// *************************************************************************** *
// *                                                                           *
// * Description:         CANDB File                                           *
// * Generated at:        2024-09-17 14:53                                     *
// * System:              SDB23200                                             *
// * Variant:             E371_PCMU_ADCU5                                      *
// * Network:             ChassisCAN1                                          *
// *                                                                           *
// *************************************************************************** *

VERSION "ChassisCAN1"

NS_ :

BS_ :

BU_ :  ASDM BBM ETC PSCM1 PSCM2 RBCM SAS VDDM

BO_ 147 AsdmChas1Fr01 : 8 ASDM
 SG_ AsyADL3FuncCtrlSts_UB : 32|1@0+ (1,0) [0|1] "" PSCM1
 SG_ AsyADL3FuncCtrlStsADMod : 27|2@0+ (1,0) [0|3] "" PSCM1
 SG_ AsyADL3FuncCtrlStsChks : 23|8@0+ (1.0,0.0) [0.0|255.0] "Unitless" PSCM1
 SG_ AsyADL3FuncCtrlStsCntr : 31|4@0+ (1.0,0.0) [0.0|15.0] "Unitless" PSCM1
 SG_ AsyADL3FuncCtrlStsCtrlSts : 33|1@0+ (1,0) [0|1] "" PSCM1
 SG_ AsyADL3FuncCtrlStsDegraded : 39|4@0+ (1.0,0.0) [0.0|15.0] "Unitless" PSCM1
 SG_ AsyADL3FuncCtrlStsQf : 25|2@0+ (1,0) [0|3] "" PSCM1
 SG_ AsyADL3FuncCtrlStsSts : 35|2@0+ (1,0) [0|3] "" PSCM1
 SG_ AsyADModeReq_UB : 48|1@0+ (1,0) [0|1] "" PSCM1
 SG_ AsyADModeReqADActiveReq : 51|2@0+ (1,0) [0|3] "" PSCM1
 SG_ AsyADModeReqADDeactiveReq : 49|1@0+ (1,0) [0|1] "" PSCM1
 SG_ AsyADModeReqChks : 47|8@0+ (1.0,0.0) [0.0|255.0] "Unitless" PSCM1
 SG_ AsyADModeReqCntr : 55|4@0+ (1.0,0.0) [0.0|15.0] "Unitless" PSCM1
 SG_ PASFuncActive : 15|1@0+ (1,0) [0|1] "" VDDM
 SG_ PASFuncActive_UB : 14|1@0+ (1,0) [0|1] "" VDDM
 SG_ RctaBrkReqQM : 13|1@0+ (1,0) [0|1] "" VDDM
 SG_ RctaBrkReqQM_UB : 12|1@0+ (1,0) [0|1] "" VDDM
 SG_ RcwmBrkReqQM : 11|1@0+ (1,0) [0|1] "" VDDM
 SG_ RcwmBrkReqQM_UB : 10|1@0+ (1,0) [0|1] "" VDDM

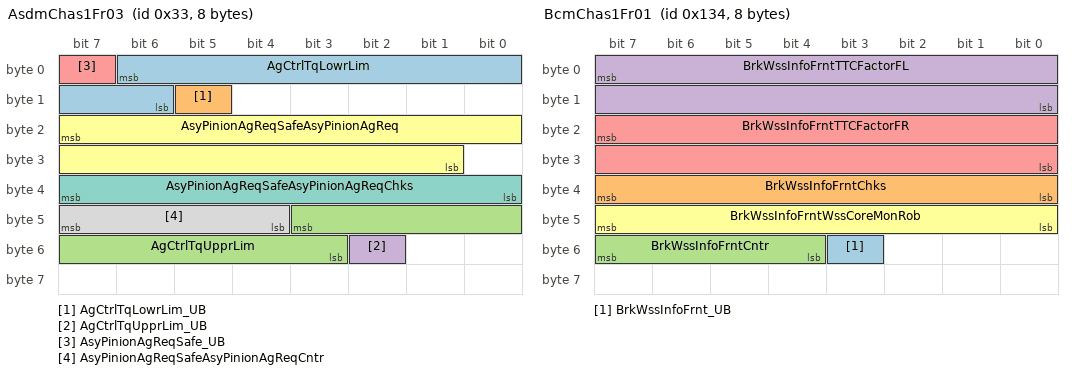
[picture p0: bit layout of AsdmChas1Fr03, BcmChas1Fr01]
BO_ 51 AsdmChas1Fr03 : 8 ASDM
 SG_ AgCtrlTqLowrLim : 6|9@0+ (0.125,-30.0) [-30.0|30.0] "Nm" PSCM1
 SG_ AgCtrlTqLowrLim_UB : 13|1@0+ (1,0) [0|1] "" PSCM1
 SG_ AgCtrlTqUpprLim : 43|9@0+ (0.125,-30.0) [-30.0|30.0] "Nm" PSCM1
 SG_ AgCtrlTqUpprLim_UB : 50|1@0+ (1,0) [0|1] "" PSCM1
 SG_ AsyPinionAgReqSafe_UB : 7|1@0+ (1,0) [0|1] "" PSCM1
 SG_ AsyPinionAgReqSafeAsyPinionAgReq : 23|15@0+ (0.0009765625,-14.5) [-14.5|17.4990234375] "rad" PSCM1
 SG_ AsyPinionAgReqSafeAsyPinionAgReqChks : 39|8@0+ (1.0,0.0) [0.0|255.0] "Unitless" PSCM1
 SG_ AsyPinionAgReqSafeAsyPinionAgReqCntr : 47|4@0+ (1.0,0.0) [0.0|15.0] "Unitless" PSCM1

BO_ 1321 AsdmChas1NMFr : 8 ASDM
 SG_ PNC16_ASDM : 16|1@0+ (1,0) [0|0] "" Vector__XXX
 SG_ PNC17_ASDM : 17|1@0+ (1,0) [0|0] "" Vector__XXX
 SG_ PNC18_ASDM : 18|1@0+ (1,0) [0|0] "" Vector__XXX
 SG_ PNC19_ASDM : 19|1@0+ (1,0) [0|0] "" Vector__XXX
 SG_ PNC20_ASDM : 20|1@0+ (1,0) [0|0] "" Vector__XXX
 SG_ PNC21_ASDM : 21|1@0+ (1,0) [0|0] "" Vector__XXX
 SG_ PNC22_ASDM : 22|1@0+ (1,0) [0|0] "" Vector__XXX
 SG_ PNC23_ASDM : 23|1@0+ (1,0) [0|0] "" Vector__XXX
 SG_ PNC24_ASDM : 24|1@0+ (1,0) [0|0] "" Vector__XXX
 SG_ PNC25_ASDM : 25|1@0+ (1,0) [0|0] "" Vector__XXX
 SG_ PNC26_ASDM : 26|1@0+ (1,0) [0|0] "" Vector__XXX
 SG_ PNC27_ASDM : 27|1@0+ (1,0) [0|0] "" Vector__XXX
 SG_ PNC28_ASDM : 28|1@0+ (1,0) [0|0] "" Vector__XXX
 SG_ PNC29_ASDM : 29|1@0+ (1,0) [0|0] "" Vector__XXX
 SG_ PNC30_ASDM : 30|1@0+ (1,0) [0|0] "" Vector__XXX
 SG_ PNC31_ASDM : 31|1@0+ (1,0) [0|0] "" Vector__XXX
 SG_ PNC32_ASDM : 32|1@0+ (1,0) [0|0] "" Vector__XXX
 SG_ PNC33_ASDM : 33|1@0+ (1,0) [0|0] "" Vector__XXX
 SG_ PNC34_ASDM : 34|1@0+ (1,0) [0|0] "" Vector__XXX
 SG_ PNC35_ASDM : 35|1@0+ (1,0) [0|0] "" Vector__XXX
 SG_ PNC36_ASDM : 36|1@0+ (1,0) [0|0] "" Vector__XXX
 SG_ PNC37_ASDM : 37|1@0+ (1,0) [0|0] "" Vector__XXX
 SG_ PNC38_ASDM : 38|1@0+ (1,0) [0|0] "" Vector__XXX
 SG_ PNC39_ASDM : 39|1@0+ (1,0) [0|0] "" Vector__XXX
 SG_ PNC40_ASDM : 40|1@0+ (1,0) [0|0] "" Vector__XXX
 SG_ PNC41_ASDM : 41|1@0+ (1,0) [0|0] "" Vector__XXX
 SG_ PNC42_ASDM : 42|1@0+ (1,0) [0|0] "" Vector__XXX
 SG_ NM_PNI_ASDM : 14|1@0+ (1,0) [0|0] "" Vector__XXX
 SG_ NM_AW_ASDM : 12|1@0+ (1,0) [0|0] "" Vector__XXX
 SG_ NM_CS_ASDM : 11|1@0+ (1,0) [0|0] "" Vector__XXX
 SG_ NM_RMR_ASDM : 8|1@0+ (1,0) [0|0] "" Vector__XXX
 SG_ NM_NodeID_ASDM : 7|8@0+ (1,0) [0|0] "" Vector__XXX

BO_ 308 BcmChas1Fr01 : 8 BBM
 SG_ BrkWssInfoFrnt_UB : 51|1@0+ (1,0) [0|1] "" RBCM
 SG_ BrkWssInfoFrntChks : 39|8@0+ (1.0,0.0) [0.0|255.0] "Unitless" RBCM
 SG_ BrkWssInfoFrntCntr : 55|4@0+ (1.0,0.0) [0.0|15.0] "Unitless" RBCM
 SG_ BrkWssInfoFrntTTCFactorFL : 7|16@0+ (0.00000916,0.7) [0.7|1.3003006] "Unitless" RBCM
 SG_ BrkWssInfoFrntTTCFactorFR : 23|16@0+ (0.00000916,0.7) [0.7|1.3003006] "Unitless" RBCM
 SG_ BrkWssInfoFrntWssCoreMonRob : 47|8@0+ (1.0,0.0) [0.0|255.0] "Unitless" RBCM

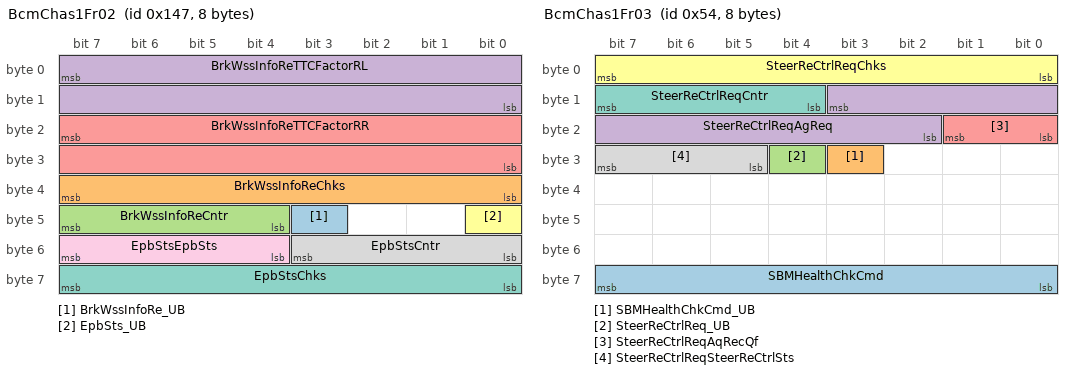
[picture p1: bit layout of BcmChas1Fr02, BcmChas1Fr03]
BO_ 327 BcmChas1Fr02 : 8 BBM
 SG_ BrkWssInfoRe_UB : 43|1@0+ (1,0) [0|1] "" RBCM
 SG_ BrkWssInfoReChks : 39|8@0+ (1.0,0.0) [0.0|255.0] "Unitless" RBCM
 SG_ BrkWssInfoReCntr : 47|4@0+ (1.0,0.0) [0.0|15.0] "Unitless" RBCM
 SG_ BrkWssInfoReTTCFactorRL : 7|16@0+ (0.00000916,0.7) [0.7|1.3003006] "Unitless" RBCM
 SG_ BrkWssInfoReTTCFactorRR : 23|16@0+ (0.00000916,0.7) [0.7|1.3003006] "Unitless" RBCM
 SG_ EpbSts_UB : 40|1@0+ (1,0) [0|1] "" RBCM
 SG_ EpbStsChks : 63|8@0+ (1.0,0.0) [0.0|255.0] "Unitless" RBCM
 SG_ EpbStsCntr : 51|4@0+ (1.0,0.0) [0.0|15.0] "Unitless" RBCM
 SG_ EpbStsEpbSts : 55|4@0+ (1,0) [0|15] "" RBCM

BO_ 84 BcmChas1Fr03 : 8 BBM
 SG_ SBMHealthChkCmd : 63|8@0+ (1.0,0.0) [0.0|255.0] "Unitless" RBCM
 SG_ SBMHealthChkCmd_UB : 27|1@0+ (1,0) [0|1] "" RBCM
 SG_ SteerReCtrlReq_UB : 28|1@0+ (1,0) [0|1] "" Vector__XXX
 SG_ SteerReCtrlReqAgReq : 11|10@0- (0.01,0.0) [-5.12|5.11] "Deg" Vector__XXX
 SG_ SteerReCtrlReqAqRecQf : 17|2@0+ (1,0) [0|3] "" Vector__XXX
 SG_ SteerReCtrlReqChks : 7|8@0+ (1.0,0.0) [0.0|255.0] "Unitless" Vector__XXX
 SG_ SteerReCtrlReqCntr : 15|4@0+ (1.0,0.0) [0.0|15.0] "Unitless" Vector__XXX
 SG_ SteerReCtrlReqSteerReCtrlSts : 31|3@0+ (1,0) [0|7] "" Vector__XXX

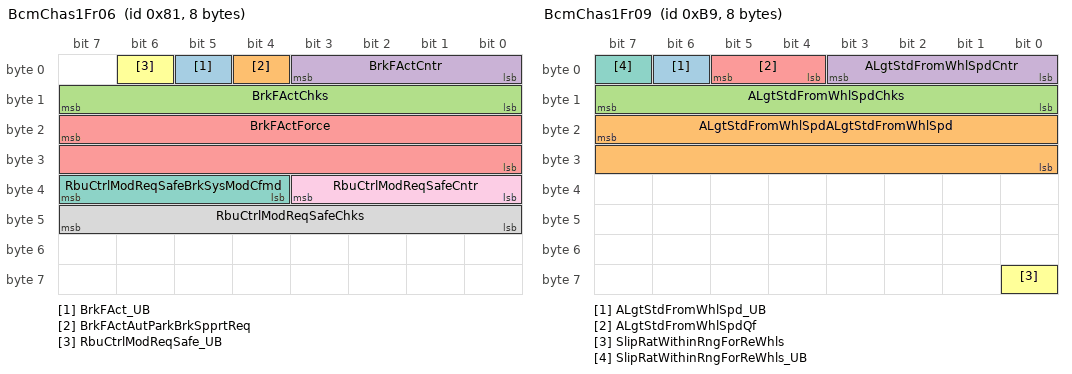
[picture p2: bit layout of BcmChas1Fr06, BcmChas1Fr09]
BO_ 129 BcmChas1Fr06 : 8 BBM
 SG_ BrkFAct_UB : 5|1@0+ (1,0) [0|1] "" RBCM
 SG_ BrkFActAutParkBrkSpprtReq : 4|1@0+ (1,0) [0|1] "" RBCM
 SG_ BrkFActChks : 15|8@0+ (1.0,0.0) [0.0|255.0] "Unitless" RBCM
 SG_ BrkFActCntr : 3|4@0+ (1.0,0.0) [0.0|15.0] "Unitless" RBCM
 SG_ BrkFActForce : 23|16@0+ (1.0,0.0) [0.0|50000.0] "N" RBCM
 SG_ RbuCtrlModReqSafe_UB : 6|1@0+ (1,0) [0|1] "" RBCM
 SG_ RbuCtrlModReqSafeBrkSysModCfmd : 39|4@0+ (1,0) [0|15] "" RBCM
 SG_ RbuCtrlModReqSafeChks : 47|8@0+ (1.0,0.0) [0.0|255.0] "Unitless" RBCM
 SG_ RbuCtrlModReqSafeCntr : 35|4@0+ (1.0,0.0) [0.0|15.0] "Unitless" RBCM

BO_ 265 BcmChas1Fr07 : 8 BBM
 SG_ EpbAvlPrim_UB : 57|1@0+ (1,0) [0|1] "" Vector__XXX
 SG_ EpbAvlPrimApplyFunctionalitiesAvailable : 27|1@0+ (1,0) [0|1] "" Vector__XXX
 SG_ EpbAvlPrimChks : 23|8@0+ (1.0,0.0) [0.0|255.0] "Unitless" Vector__XXX
 SG_ EpbAvlPrimCntr : 31|4@0+ (1.0,0.0) [0.0|15.0] "Unitless" Vector__XXX
 SG_ EpbAvlPrimDriveAwayIntention : 26|1@0+ (1,0) [0|1] "" Vector__XXX
 SG_ EpbAvlPrimHostAvailabilityFull : 25|1@0+ (1,0) [0|1] "" Vector__XXX
 SG_ EpbAvlPrimHostAvailabilityRelOnly : 24|1@0+ (1,0) [0|1] "" Vector__XXX
 SG_ EpbAvlPrimPrimarySystemAvailable : 39|1@0+ (1,0) [0|1] "" Vector__XXX
 SG_ EpbAvlPrimReserved1 : 38|1@0+ (1,0) [0|1] "" Vector__XXX
 SG_ EpbAvlPrimReserved2 : 37|1@0+ (1,0) [0|1] "" Vector__XXX
 SG_ EpbAvlPrimReserved3 : 36|1@0+ (1,0) [0|1] "" Vector__XXX
 SG_ EpbAvlPrimReserved4 : 35|1@0+ (1,0) [0|1] "" Vector__XXX
 SG_ EpbAvlPrimRollerTestBench : 34|1@0+ (1,0) [0|1] "" Vector__XXX
 SG_ PrimBrkSysSt_UB : 56|1@0+ (1,0) [0|1] "" RBCM
 SG_ PrimBrkSysStBrkSysSt : 7|4@0+ (1,0) [0|15] "" RBCM
 SG_ PrimBrkSysStChks : 15|8@0+ (1.0,0.0) [0.0|255.0] "Unitless" RBCM
 SG_ PrimBrkSysStCntr : 3|4@0+ (1.0,0.0) [0.0|15.0] "Unitless" RBCM

BO_ 185 BcmChas1Fr09 : 8 BBM
 SG_ ALgtStdFromWhlSpd_UB : 6|1@0+ (1,0) [0|1] "" Vector__XXX
 SG_ ALgtStdFromWhlSpdALgtStdFromWhlSpd : 23|16@0- (0.0009765625,0.0) [-18.0|18.0] "m/s^2" Vector__XXX
 SG_ ALgtStdFromWhlSpdChks : 15|8@0+ (1.0,0.0) [0.0|255.0] "Unitless" Vector__XXX
 SG_ ALgtStdFromWhlSpdCntr : 3|4@0+ (1.0,0.0) [0.0|15.0] "Unitless" Vector__XXX
 SG_ ALgtStdFromWhlSpdQf : 5|2@0+ (1,0) [0|3] "" Vector__XXX
 SG_ SlipRatWithinRngForReWhls : 56|1@0+ (1,0) [0|1] "" Vector__XXX
 SG_ SlipRatWithinRngForReWhls_UB : 7|1@0+ (1,0) [0|1] "" Vector__XXX

BO_ 1334 BcmChas1NMFr : 8 BBM
 SG_ PNC16_BBM : 16|1@0+ (1,0) [0|0] "" Vector__XXX
 SG_ PNC17_BBM : 17|1@0+ (1,0) [0|0] "" Vector__XXX
 SG_ PNC18_BBM : 18|1@0+ (1,0) [0|0] "" Vector__XXX
 SG_ PNC19_BBM : 19|1@0+ (1,0) [0|0] "" Vector__XXX
 SG_ PNC20_BBM : 20|1@0+ (1,0) [0|0] "" Vector__XXX
 SG_ PNC21_BBM : 21|1@0+ (1,0) [0|0] "" Vector__XXX
 SG_ PNC22_BBM : 22|1@0+ (1,0) [0|0] "" Vector__XXX
 SG_ PNC23_BBM : 23|1@0+ (1,0) [0|0] "" Vector__XXX
 SG_ PNC24_BBM : 24|1@0+ (1,0) [0|0] "" Vector__XXX
 SG_ PNC25_BBM : 25|1@0+ (1,0) [0|0] "" Vector__XXX
 SG_ PNC26_BBM : 26|1@0+ (1,0) [0|0] "" Vector__XXX
 SG_ PNC27_BBM : 27|1@0+ (1,0) [0|0] "" Vector__XXX
 SG_ PNC28_BBM : 28|1@0+ (1,0) [0|0] "" Vector__XXX
 SG_ PNC29_BBM : 29|1@0+ (1,0) [0|0] "" Vector__XXX
 SG_ PNC30_BBM : 30|1@0+ (1,0) [0|0] "" Vector__XXX
 SG_ PNC31_BBM : 31|1@0+ (1,0) [0|0] "" Vector__XXX
 SG_ PNC32_BBM : 32|1@0+ (1,0) [0|0] "" Vector__XXX
 SG_ PNC33_BBM : 33|1@0+ (1,0) [0|0] "" Vector__XXX
 SG_ PNC34_BBM : 34|1@0+ (1,0) [0|0] "" Vector__XXX
 SG_ PNC35_BBM : 35|1@0+ (1,0) [0|0] "" Vector__XXX
 SG_ PNC36_BBM : 36|1@0+ (1,0) [0|0] "" Vector__XXX
 SG_ PNC37_BBM : 37|1@0+ (1,0) [0|0] "" Vector__XXX
 SG_ PNC38_BBM : 38|1@0+ (1,0) [0|0] "" Vector__XXX
 SG_ PNC39_BBM : 39|1@0+ (1,0) [0|0] "" Vector__XXX
 SG_ PNC40_BBM : 40|1@0+ (1,0) [0|0] "" Vector__XXX
 SG_ PNC41_BBM : 41|1@0+ (1,0) [0|0] "" Vector__XXX
 SG_ PNC42_BBM : 42|1@0+ (1,0) [0|0] "" Vector__XXX
 SG_ NM_PNI_BBM : 14|1@0+ (1,0) [0|0] "" Vector__XXX
 SG_ NM_AW_BBM : 12|1@0+ (1,0) [0|0] "" Vector__XXX
 SG_ NM_CS_BBM : 11|1@0+ (1,0) [0|0] "" Vector__XXX
 SG_ NM_RMR_BBM : 8|1@0+ (1,0) [0|0] "" Vector__XXX
 SG_ NM_NodeID_BBM : 7|8@0+ (1,0) [0|0] "" Vector__XXX

BO_ 134 EcmChas1BsgFr40 : 8 VDDM
 SG_ DrvgCyc : 39|1@0+ (1,0) [0|1] "" Vector__XXX
 SG_ DrvgCyc_UB : 38|1@0+ (1,0) [0|1] "" Vector__XXX

BO_ 544 EcmChas1BsgFr41 : 8 VDDM
 SG_ AccrPedlRat_UB : 7|1@0+ (1,0) [0|1] "" RBCM
 SG_ AccrPedlRatAccrPedlRat : 6|15@0+ (0.00390625,0.0) [0.0|100.0] "%" RBCM
 SG_ AccrPedlRatChks : 23|8@0+ (1.0,0.0) [0.0|255.0] "Unitless" RBCM
 SG_ AccrPedlRatCntr : 31|4@0+ (1.0,0.0) [0.0|15.0] "Unitless" RBCM

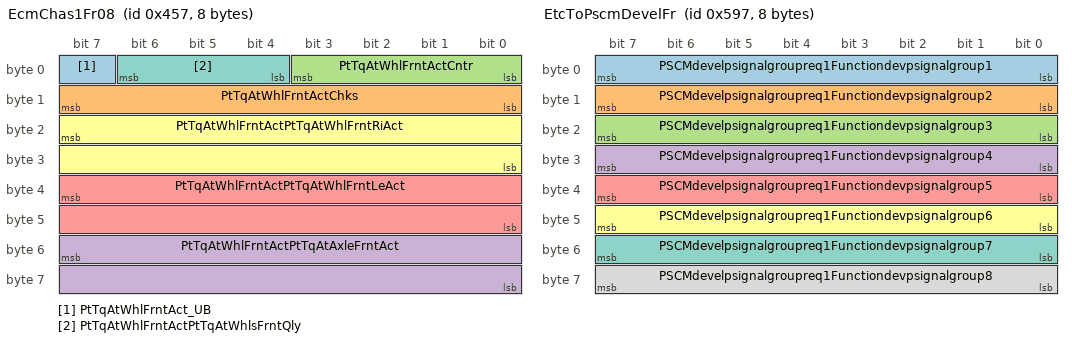
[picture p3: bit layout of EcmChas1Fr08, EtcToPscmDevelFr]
BO_ 1111 EcmChas1Fr08 : 8 VDDM
 SG_ PtTqAtWhlFrntAct_UB : 7|1@0+ (1,0) [0|1] "" PSCM1
 SG_ PtTqAtWhlFrntActChks : 15|8@0+ (1.0,0.0) [0.0|255.0] "Unitless" PSCM1
 SG_ PtTqAtWhlFrntActCntr : 3|4@0+ (1.0,0.0) [0.0|15.0] "Unitless" PSCM1
 SG_ PtTqAtWhlFrntActPtTqAtAxleFrntAct : 55|16@0- (1.0,0.0) [-20000.0|20000.0] "NewtonMeter" PSCM1
 SG_ PtTqAtWhlFrntActPtTqAtWhlFrntLeAct : 39|16@0- (1.0,0.0) [-20000.0|20000.0] "NewtonMeter" PSCM1
 SG_ PtTqAtWhlFrntActPtTqAtWhlFrntRiAct : 23|16@0- (1.0,0.0) [-20000.0|20000.0] "NewtonMeter" PSCM1
 SG_ PtTqAtWhlFrntActPtTqAtWhlsFrntQly : 6|3@0+ (1,0) [0|7] "" PSCM1

BO_ 131 EcmChas1Fr31 : 8 VDDM
 SG_ EngSt1WdSts_UB : 23|1@0+ (1,0) [0|1] "" Vector__XXX
 SG_ EngSt1WdStsChks : 7|8@0+ (1.0,0.0) [0.0|255.0] "Unitless" Vector__XXX
 SG_ EngSt1WdStsCntr : 15|4@0+ (1.0,0.0) [0.0|15.0] "Unitless" Vector__XXX
 SG_ EngSt1WdStsEngSt1WdSts : 11|4@0+ (1,0) [0|15] "" Vector__XXX

BO_ 752 EcmChas1Fr37 : 8 VDDM
 SG_ DrvrGearLvrInfoIndcn : 15|3@0+ (1,0) [0|7] "" Vector__XXX
 SG_ DrvrGearLvrInfoIndcn_UB : 12|1@0+ (1,0) [0|1] "" Vector__XXX
 SG_ EngSt1WdSts1 : 11|4@0+ (1,0) [0|15] "" SAS
 SG_ EngSt1WdSts1_UB : 41|1@0+ (1,0) [0|1] "" SAS

BO_ 121 EcmChas1Fr53 : 8 VDDM
 SG_ EngPAmbAir : 63|8@0+ (5.0,0.0) [0.0|1275.0] "hPa" Vector__XXX
 SG_ EngPAmbAir_UB : 48|1@0+ (1,0) [0|1] "" Vector__XXX

BO_ 1429 EtcToMvemXcpFr01 : 8 ETC

BO_ 1424 EtcToMvemXcpFr02 : 8 ETC

BO_ 1425 EtcToMvemXcpFr03 : 8 ETC

BO_ 1441 EtcToPscm1cChas1XcpFr01 : 8 ETC

BO_ 1409 EtcToPscmChas1XcpFr01 : 8 ETC

BO_ 1416 EtcToPscmChas1XcpFr02 : 8 ETC

BO_ 1418 EtcToPscmChas1XcpFr03 : 8 ETC

BO_ 1420 EtcToPscmChas1XcpFr04 : 8 ETC

BO_ 1431 EtcToPscmDevelFr : 8 ETC
 SG_ PSCMdevelpsignalgroupreq1Functiondevpsignalgroup1 : 7|8@0+ (1.0,0.0) [0.0|255.0] "Unitless" PSCM1
 SG_ PSCMdevelpsignalgroupreq1Functiondevpsignalgroup2 : 15|8@0+ (1.0,0.0) [0.0|255.0] "Unitless" PSCM1
 SG_ PSCMdevelpsignalgroupreq1Functiondevpsignalgroup3 : 23|8@0+ (1.0,0.0) [0.0|255.0] "Unitless" PSCM1
 SG_ PSCMdevelpsignalgroupreq1Functiondevpsignalgroup4 : 31|8@0+ (1.0,0.0) [0.0|255.0] "Unitless" PSCM1
 SG_ PSCMdevelpsignalgroupreq1Functiondevpsignalgroup5 : 39|8@0+ (1.0,0.0) [0.0|255.0] "Unitless" PSCM1
 SG_ PSCMdevelpsignalgroupreq1Functiondevpsignalgroup6 : 47|8@0+ (1.0,0.0) [0.0|255.0] "Unitless" PSCM1
 SG_ PSCMdevelpsignalgroupreq1Functiondevpsignalgroup7 : 55|8@0+ (1.0,0.0) [0.0|255.0] "Unitless" PSCM1
 SG_ PSCMdevelpsignalgroupreq1Functiondevpsignalgroup8 : 63|8@0+ (1.0,0.0) [0.0|255.0] "Unitless" PSCM1

BO_ 1442 EtcToRasmChas1XcpFr01 : 8 ETC

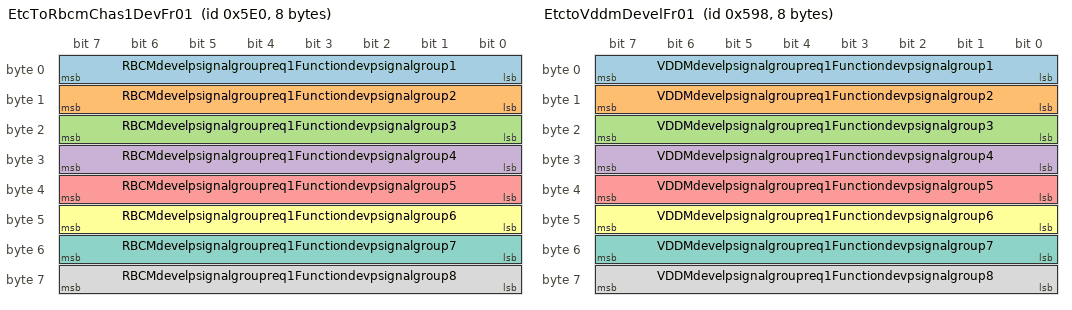
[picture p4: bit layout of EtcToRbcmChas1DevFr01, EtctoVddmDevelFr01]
BO_ 1504 EtcToRbcmChas1DevFr01 : 8 ETC
 SG_ RBCMdevelpsignalgroupreq1Functiondevpsignalgroup1 : 7|8@0+ (1.0,0.0) [0.0|255.0] "Unitless" Vector__XXX
 SG_ RBCMdevelpsignalgroupreq1Functiondevpsignalgroup2 : 15|8@0+ (1.0,0.0) [0.0|255.0] "Unitless" Vector__XXX
 SG_ RBCMdevelpsignalgroupreq1Functiondevpsignalgroup3 : 23|8@0+ (1.0,0.0) [0.0|255.0] "Unitless" Vector__XXX
 SG_ RBCMdevelpsignalgroupreq1Functiondevpsignalgroup4 : 31|8@0+ (1.0,0.0) [0.0|255.0] "Unitless" Vector__XXX
 SG_ RBCMdevelpsignalgroupreq1Functiondevpsignalgroup5 : 39|8@0+ (1.0,0.0) [0.0|255.0] "Unitless" Vector__XXX
 SG_ RBCMdevelpsignalgroupreq1Functiondevpsignalgroup6 : 47|8@0+ (1.0,0.0) [0.0|255.0] "Unitless" Vector__XXX
 SG_ RBCMdevelpsignalgroupreq1Functiondevpsignalgroup7 : 55|8@0+ (1.0,0.0) [0.0|255.0] "Unitless" Vector__XXX
 SG_ RBCMdevelpsignalgroupreq1Functiondevpsignalgroup8 : 63|8@0+ (1.0,0.0) [0.0|255.0] "Unitless" Vector__XXX

BO_ 1414 EtcToTcmXcpFr01 : 8 ETC

BO_ 1411 EtcToTcmXcpFr02 : 8 ETC

BO_ 1421 EtctoVddmBcmXCPFr01 : 8 ETC

BO_ 1432 EtctoVddmDevelFr01 : 8 ETC
 SG_ VDDMdevelpsignalgroupreq1Functiondevpsignalgroup1 : 7|8@0+ (1.0,0.0) [0.0|255.0] "Unitless" BBM
 SG_ VDDMdevelpsignalgroupreq1Functiondevpsignalgroup2 : 15|8@0+ (1.0,0.0) [0.0|255.0] "Unitless" BBM
 SG_ VDDMdevelpsignalgroupreq1Functiondevpsignalgroup3 : 23|8@0+ (1.0,0.0) [0.0|255.0] "Unitless" BBM
 SG_ VDDMdevelpsignalgroupreq1Functiondevpsignalgroup4 : 31|8@0+ (1.0,0.0) [0.0|255.0] "Unitless" BBM
 SG_ VDDMdevelpsignalgroupreq1Functiondevpsignalgroup5 : 39|8@0+ (1.0,0.0) [0.0|255.0] "Unitless" BBM
 SG_ VDDMdevelpsignalgroupreq1Functiondevpsignalgroup6 : 47|8@0+ (1.0,0.0) [0.0|255.0] "Unitless" BBM
 SG_ VDDMdevelpsignalgroupreq1Functiondevpsignalgroup7 : 55|8@0+ (1.0,0.0) [0.0|255.0] "Unitless" BBM
 SG_ VDDMdevelpsignalgroupreq1Functiondevpsignalgroup8 : 63|8@0+ (1.0,0.0) [0.0|255.0] "Unitless" BBM

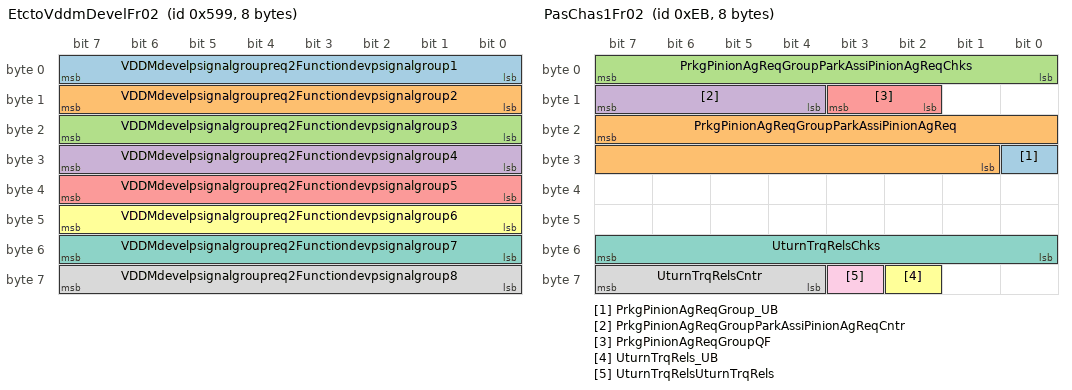
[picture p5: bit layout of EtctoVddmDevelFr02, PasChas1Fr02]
BO_ 1433 EtctoVddmDevelFr02 : 8 ETC
 SG_ VDDMdevelpsignalgroupreq2Functiondevpsignalgroup1 : 7|8@0+ (1.0,0.0) [0.0|255.0] "Unitless" BBM
 SG_ VDDMdevelpsignalgroupreq2Functiondevpsignalgroup2 : 15|8@0+ (1.0,0.0) [0.0|255.0] "Unitless" BBM
 SG_ VDDMdevelpsignalgroupreq2Functiondevpsignalgroup3 : 23|8@0+ (1.0,0.0) [0.0|255.0] "Unitless" BBM
 SG_ VDDMdevelpsignalgroupreq2Functiondevpsignalgroup4 : 31|8@0+ (1.0,0.0) [0.0|255.0] "Unitless" BBM
 SG_ VDDMdevelpsignalgroupreq2Functiondevpsignalgroup5 : 39|8@0+ (1.0,0.0) [0.0|255.0] "Unitless" BBM
 SG_ VDDMdevelpsignalgroupreq2Functiondevpsignalgroup6 : 47|8@0+ (1.0,0.0) [0.0|255.0] "Unitless" BBM
 SG_ VDDMdevelpsignalgroupreq2Functiondevpsignalgroup7 : 55|8@0+ (1.0,0.0) [0.0|255.0] "Unitless" BBM
 SG_ VDDMdevelpsignalgroupreq2Functiondevpsignalgroup8 : 63|8@0+ (1.0,0.0) [0.0|255.0] "Unitless" BBM

BO_ 235 PasChas1Fr02 : 8 ASDM
 SG_ PrkgPinionAgReqGroup_UB : 24|1@0+ (1,0) [0|1] "" PSCM1
 SG_ PrkgPinionAgReqGroupParkAssiPinionAgReq : 23|15@0+ (0.000976563,-14.5) [-14.5|17.499039821] "rad" PSCM1
 SG_ PrkgPinionAgReqGroupParkAssiPinionAgReqChks : 7|8@0+ (1.0,0.0) [0.0|255.0] "Unitless" PSCM1
 SG_ PrkgPinionAgReqGroupParkAssiPinionAgReqCntr : 15|4@0+ (1.0,0.0) [0.0|15.0] "Unitless" PSCM1
 SG_ PrkgPinionAgReqGroupQF : 11|2@0+ (1,0) [0|3] "" PSCM1
 SG_ UturnTrqRels_UB : 58|1@0+ (1,0) [0|1] "" PSCM1
 SG_ UturnTrqRelsChks : 55|8@0+ (1.0,0.0) [0.0|255.0] "Unitless" PSCM1
 SG_ UturnTrqRelsCntr : 63|4@0+ (1.0,0.0) [0.0|15.0] "Unitless" PSCM1
 SG_ UturnTrqRelsUturnTrqRels : 59|1@0+ (1,0) [0|1] "" PSCM1

BO_ 149 PasChas1Fr04 : 8 ASDM
 SG_ PrkgGearReqGroup_UB : 10|1@0+ (1,0) [0|1] "" VDDM
 SG_ PrkgGearReqGroupChks : 7|8@0+ (1.0,0.0) [0.0|255.0] "Unitless" VDDM
 SG_ PrkgGearReqGroupCntr : 15|4@0+ (1.0,0.0) [0.0|15.0] "Unitless" VDDM
 SG_ PrkgGearReqGroupReqSts1 : 11|1@0+ (1,0) [0|1] "" VDDM

BO_ 1654 Pscm2cToVddmChas1DiagResFrame : 8 PSCM2
 SG_ Pscm2cToVddmChas1DiagResNpdu : 7|64@0+ (1,0) [0|0] "" VDDM

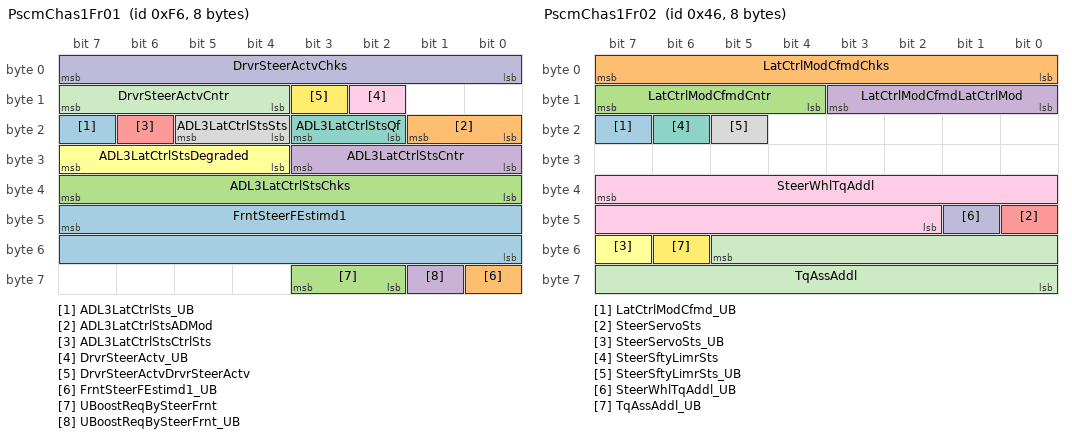
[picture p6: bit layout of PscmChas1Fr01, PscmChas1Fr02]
BO_ 246 PscmChas1Fr01 : 8 PSCM1
 SG_ ADL3LatCtrlSts_UB : 23|1@0+ (1,0) [0|1] "" ASDM
 SG_ ADL3LatCtrlStsADMod : 17|2@0+ (1,0) [0|3] "" ASDM
 SG_ ADL3LatCtrlStsChks : 39|8@0+ (1.0,0.0) [0.0|255.0] "Unitless" ASDM
 SG_ ADL3LatCtrlStsCntr : 27|4@0+ (1.0,0.0) [0.0|15.0] "Unitless" ASDM
 SG_ ADL3LatCtrlStsCtrlSts : 22|1@0+ (1,0) [0|1] "" ASDM
 SG_ ADL3LatCtrlStsDegraded : 31|4@0+ (1,0) [0|15] "" ASDM
 SG_ ADL3LatCtrlStsQf : 19|2@0+ (1,0) [0|3] "" ASDM
 SG_ ADL3LatCtrlStsSts : 21|2@0+ (1,0) [0|3] "" ASDM
 SG_ DrvrSteerActv_UB : 10|1@0+ (1,0) [0|1] "" ASDM
 SG_ DrvrSteerActvChks : 7|8@0+ (1.0,0.0) [0.0|255.0] "Unitless" ASDM
 SG_ DrvrSteerActvCntr : 15|4@0+ (1.0,0.0) [0.0|15.0] "Unitless" ASDM
 SG_ DrvrSteerActvDrvrSteerActv : 11|1@0+ (1,0) [0|1] "" ASDM
 SG_ FrntSteerFEstimd1 : 47|16@0- (1.0,0.0) [-32768.0|32767.0] "N" BBM
 SG_ FrntSteerFEstimd1_UB : 56|1@0+ (1,0) [0|1] "" BBM
 SG_ UBoostReqBySteerFrnt : 59|2@0+ (1,0) [0|3] "" VDDM
 SG_ UBoostReqBySteerFrnt_UB : 57|1@0+ (1,0) [0|1] "" VDDM

BO_ 70 PscmChas1Fr02 : 8 PSCM1
 SG_ LatCtrlModCfmd_UB : 23|1@0+ (1,0) [0|1] "" ASDM,BBM,VDDM
 SG_ LatCtrlModCfmdChks : 7|8@0+ (1.0,0.0) [0.0|255.0] "Unitless" ASDM,BBM,VDDM
 SG_ LatCtrlModCfmdCntr : 15|4@0+ (1.0,0.0) [0.0|15.0] "Unitless" ASDM,BBM,VDDM
 SG_ LatCtrlModCfmdLatCtrlMod : 11|4@0+ (1,0) [0|15] "" ASDM,BBM,VDDM
 SG_ SteerServoSts : 40|1@0+ (1,0) [0|1] "" ASDM,VDDM
 SG_ SteerServoSts_UB : 55|1@0+ (1,0) [0|1] "" ASDM,VDDM
 SG_ SteerSftyLimrSts : 22|1@0+ (1,0) [0|1] "" ASDM
 SG_ SteerSftyLimrSts_UB : 21|1@0+ (1,0) [0|1] "" ASDM
 SG_ SteerWhlTqAddl : 39|14@0- (0.00390625,0.0) [-30.0|30.0] "NewtonMeter" ASDM,BBM,VDDM
 SG_ SteerWhlTqAddl_UB : 41|1@0+ (1,0) [0|1] "" ASDM,BBM,VDDM
 SG_ TqAssAddl : 53|14@0- (0.00390625,0.0) [-30.0|30.0] "NewtonMeter" ASDM
 SG_ TqAssAddl_UB : 54|1@0+ (1,0) [0|1] "" ASDM

BO_ 444 PscmChas1Fr03 : 8 PSCM1
 SG_ DrvrSteerWhlHldGroup_UB : 1|1@0+ (1,0) [0|1] "" ASDM,VDDM
 SG_ DrvrSteerWhlHldGroupDrvrSteerWhlHld : 7|2@0+ (1,0) [0|3] "" ASDM,VDDM
 SG_ DrvrSteerWhlHldGroupDrvrSteerWhlHldQly : 5|4@0+ (1.0,0.0) [0.0|15.0] "Unitless" ASDM,VDDM
 SG_ SteerErrReq : 46|3@0+ (1,0) [0|7] "" VDDM
 SG_ SteerErrReq_UB : 47|1@0+ (1,0) [0|1] "" VDDM
 SG_ SteerExtFctSts_UB : 43|1@0+ (1,0) [0|1] "" ASDM
 SG_ SteerExtFctStsChks : 63|8@0+ (1.0,0.0) [0.0|255.0] "Unitless" ASDM
 SG_ SteerExtFctStsCntr : 51|4@0+ (1.0,0.0) [0.0|15.0] "Unitless" ASDM
 SG_ SteerExtFctStsDrvrSteerOvrd : 52|1@0+ (1,0) [0|1] "" ASDM
 SG_ SteerExtFctStsExtFctLowerLimActive : 53|1@0+ (1,0) [0|1] "" ASDM
 SG_ SteerExtFctStsExtFctRateLimActive : 54|1@0+ (1,0) [0|1] "" ASDM
 SG_ SteerExtFctStsExtFctUpperLimActive : 55|1@0+ (1,0) [0|1] "" ASDM
 SG_ SteerExtFctStsExtSafeLimActive : 40|1@0+ (1,0) [0|1] "" ASDM
 SG_ SteerExtFctStsLatAgReqNotInRange : 41|1@0+ (1,0) [0|1] "" ASDM
 SG_ SteerExtFctStsLatCtrlReqNotInRange : 42|1@0+ (1,0) [0|1] "" ASDM
 SG_ SteerStsToParkAssi : 15|3@0+ (1,0) [0|7] "" ASDM,BBM
 SG_ SteerStsToParkAssi_UB : 0|1@0+ (1,0) [0|1] "" ASDM,BBM

BO_ 955 PscmChas1Fr06 : 8 PSCM1
 SG_ PinionSteerAgMax1 : 54|15@0- (0.0009765625,0.0) [-14.5|14.5] "rad" VDDM
 SG_ PinionSteerAgMax1_UB : 55|1@0+ (1,0) [0|1] "" VDDM

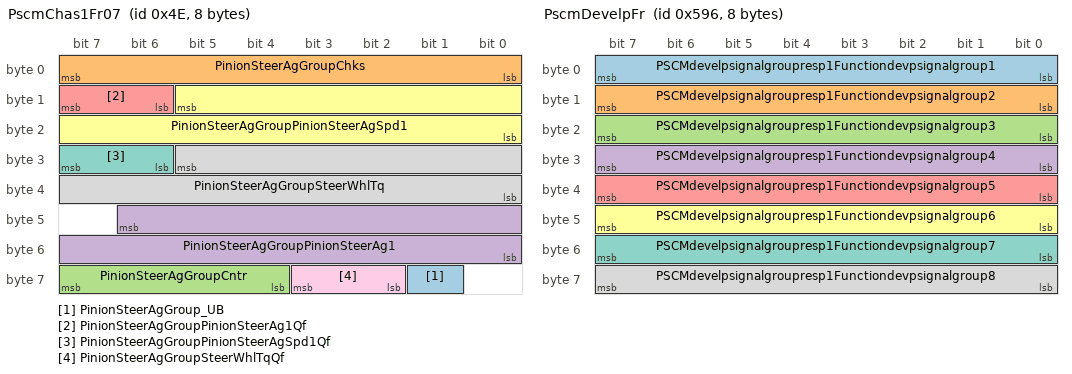
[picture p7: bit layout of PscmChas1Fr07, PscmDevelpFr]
BO_ 78 PscmChas1Fr07 : 8 PSCM1
 SG_ PinionSteerAgGroup_UB : 57|1@0+ (1,0) [0|1] "" ASDM,BBM,VDDM
 SG_ PinionSteerAgGroupChks : 7|8@0+ (1.0,0.0) [0.0|255.0] "Unitless" ASDM,BBM,VDDM
 SG_ PinionSteerAgGroupCntr : 63|4@0+ (1.0,0.0) [0.0|15.0] "Unitless" ASDM,BBM,VDDM
 SG_ PinionSteerAgGroupPinionSteerAg1 : 46|15@0- (0.0009765625,0.0) [-14.5|14.5] "rad" ASDM,BBM,VDDM
 SG_ PinionSteerAgGroupPinionSteerAg1Qf : 15|2@0+ (1,0) [0|3] "" ASDM,BBM,VDDM
 SG_ PinionSteerAgGroupPinionSteerAgSpd1 : 13|14@0- (0.0078125,0.0) [-50.0|50.0] "rad/s" ASDM,BBM,VDDM
 SG_ PinionSteerAgGroupPinionSteerAgSpd1Qf : 31|2@0+ (1,0) [0|3] "" ASDM,BBM,VDDM
 SG_ PinionSteerAgGroupSteerWhlTq : 29|14@0- (0.00390625,0.0) [-30.0|30.0] "NewtonMeter" ASDM,BBM,VDDM
 SG_ PinionSteerAgGroupSteerWhlTqQf : 59|2@0+ (1,0) [0|3] "" ASDM,BBM,VDDM

BO_ 1315 PscmChas1NMFr : 8 PSCM1
 SG_ PNC16_PSCM1 : 16|1@0+ (1,0) [0|0] "" Vector__XXX
 SG_ PNC17_PSCM1 : 17|1@0+ (1,0) [0|0] "" Vector__XXX
 SG_ PNC18_PSCM1 : 18|1@0+ (1,0) [0|0] "" Vector__XXX
 SG_ PNC19_PSCM1 : 19|1@0+ (1,0) [0|0] "" Vector__XXX
 SG_ PNC20_PSCM1 : 20|1@0+ (1,0) [0|0] "" Vector__XXX
 SG_ PNC21_PSCM1 : 21|1@0+ (1,0) [0|0] "" Vector__XXX
 SG_ PNC22_PSCM1 : 22|1@0+ (1,0) [0|0] "" Vector__XXX
 SG_ PNC23_PSCM1 : 23|1@0+ (1,0) [0|0] "" Vector__XXX
 SG_ PNC24_PSCM1 : 24|1@0+ (1,0) [0|0] "" Vector__XXX
 SG_ PNC25_PSCM1 : 25|1@0+ (1,0) [0|0] "" Vector__XXX
 SG_ PNC26_PSCM1 : 26|1@0+ (1,0) [0|0] "" Vector__XXX
 SG_ PNC27_PSCM1 : 27|1@0+ (1,0) [0|0] "" Vector__XXX
 SG_ PNC28_PSCM1 : 28|1@0+ (1,0) [0|0] "" Vector__XXX
 SG_ PNC29_PSCM1 : 29|1@0+ (1,0) [0|0] "" Vector__XXX
 SG_ PNC30_PSCM1 : 30|1@0+ (1,0) [0|0] "" Vector__XXX
 SG_ PNC31_PSCM1 : 31|1@0+ (1,0) [0|0] "" Vector__XXX
 SG_ PNC32_PSCM1 : 32|1@0+ (1,0) [0|0] "" Vector__XXX
 SG_ PNC33_PSCM1 : 33|1@0+ (1,0) [0|0] "" Vector__XXX
 SG_ PNC34_PSCM1 : 34|1@0+ (1,0) [0|0] "" Vector__XXX
 SG_ PNC35_PSCM1 : 35|1@0+ (1,0) [0|0] "" Vector__XXX
 SG_ PNC36_PSCM1 : 36|1@0+ (1,0) [0|0] "" Vector__XXX
 SG_ PNC37_PSCM1 : 37|1@0+ (1,0) [0|0] "" Vector__XXX
 SG_ PNC38_PSCM1 : 38|1@0+ (1,0) [0|0] "" Vector__XXX
 SG_ PNC39_PSCM1 : 39|1@0+ (1,0) [0|0] "" Vector__XXX
 SG_ PNC40_PSCM1 : 40|1@0+ (1,0) [0|0] "" Vector__XXX
 SG_ PNC41_PSCM1 : 41|1@0+ (1,0) [0|0] "" Vector__XXX
 SG_ PNC42_PSCM1 : 42|1@0+ (1,0) [0|0] "" Vector__XXX
 SG_ NM_PNI_PSCM1 : 14|1@0+ (1,0) [0|0] "" Vector__XXX
 SG_ NM_AW_PSCM1 : 12|1@0+ (1,0) [0|0] "" Vector__XXX
 SG_ NM_CS_PSCM1 : 11|1@0+ (1,0) [0|0] "" Vector__XXX
 SG_ NM_RMR_PSCM1 : 8|1@0+ (1,0) [0|0] "" Vector__XXX
 SG_ NM_NodeID_PSCM1 : 7|8@0+ (1,0) [0|0] "" Vector__XXX

BO_ 1430 PscmDevelpFr : 8 PSCM1
 SG_ PSCMdevelpsignalgroupresp1Functiondevpsignalgroup1 : 7|8@0+ (1.0,0.0) [0.0|255.0] "Unitless" ETC
 SG_ PSCMdevelpsignalgroupresp1Functiondevpsignalgroup2 : 15|8@0+ (1.0,0.0) [0.0|255.0] "Unitless" ETC
 SG_ PSCMdevelpsignalgroupresp1Functiondevpsignalgroup3 : 23|8@0+ (1.0,0.0) [0.0|255.0] "Unitless" ETC
 SG_ PSCMdevelpsignalgroupresp1Functiondevpsignalgroup4 : 31|8@0+ (1.0,0.0) [0.0|255.0] "Unitless" ETC
 SG_ PSCMdevelpsignalgroupresp1Functiondevpsignalgroup5 : 39|8@0+ (1.0,0.0) [0.0|255.0] "Unitless" ETC
 SG_ PSCMdevelpsignalgroupresp1Functiondevpsignalgroup6 : 47|8@0+ (1.0,0.0) [0.0|255.0] "Unitless" ETC
 SG_ PSCMdevelpsignalgroupresp1Functiondevpsignalgroup7 : 55|8@0+ (1.0,0.0) [0.0|255.0] "Unitless" ETC
 SG_ PSCMdevelpsignalgroupresp1Functiondevpsignalgroup8 : 63|8@0+ (1.0,0.0) [0.0|255.0] "Unitless" ETC

BO_ 1410 PscmToEtcChas1XcpFr01 : 8 PSCM1

BO_ 1417 PscmToEtcChas1XcpFr02 : 8 PSCM1

BO_ 1419 PscmToEtcChas1XcpFr03 : 8 PSCM1

BO_ 1415 PscmToEtcChas1XcpFr04 : 8 PSCM1

BO_ 1412 PscmToEtcChas1XcpFr05 : 8 PSCM1

BO_ 1423 PscmToEtcChas1XcpFr06 : 8 PSCM1

BO_ 1648 PscmToVddmChas1DiagResFrame : 8 PSCM1
 SG_ PscmToVddmChas1DiagResNpdu : 7|64@0+ (1,0) [0|0] "" VDDM

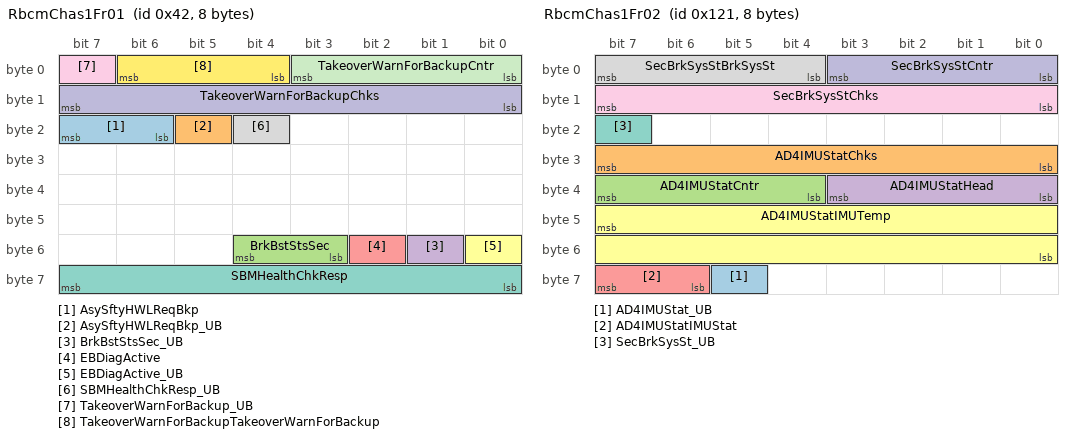
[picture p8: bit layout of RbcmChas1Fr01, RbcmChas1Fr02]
BO_ 66 RbcmChas1Fr01 : 8 RBCM
 SG_ AsySftyHWLReqBkp : 23|2@0+ (1,0) [0|3] "" Vector__XXX
 SG_ AsySftyHWLReqBkp_UB : 21|1@0+ (1,0) [0|1] "" Vector__XXX
 SG_ BrkBstStsSec : 52|2@0+ (1,0) [0|3] "" BBM
 SG_ BrkBstStsSec_UB : 49|1@0+ (1,0) [0|1] "" BBM
 SG_ EBDiagActive : 50|1@0+ (1,0) [0|1] "" BBM
 SG_ EBDiagActive_UB : 48|1@0+ (1,0) [0|1] "" BBM
 SG_ SBMHealthChkResp : 63|8@0+ (1.0,0.0) [0.0|255.0] "Unitless" BBM
 SG_ SBMHealthChkResp_UB : 20|1@0+ (1,0) [0|1] "" BBM
 SG_ TakeoverWarnForBackup_UB : 7|1@0+ (1,0) [0|1] "" Vector__XXX
 SG_ TakeoverWarnForBackupChks : 15|8@0+ (1.0,0.0) [0.0|255.0] "Unitless" Vector__XXX
 SG_ TakeoverWarnForBackupCntr : 3|4@0+ (1.0,0.0) [0.0|15.0] "Unitless" Vector__XXX
 SG_ TakeoverWarnForBackupTakeoverWarnForBackup : 6|3@0+ (1,0) [0|7] "" Vector__XXX

BO_ 289 RbcmChas1Fr02 : 8 RBCM
 SG_ AD4IMUStat_UB : 61|1@0+ (1,0) [0|1] "" BBM
 SG_ AD4IMUStatChks : 31|8@0+ (1.0,0.0) [0.0|255.0] "Unitless" BBM
 SG_ AD4IMUStatCntr : 39|4@0+ (1.0,0.0) [0.0|15.0] "Unitless" BBM
 SG_ AD4IMUStatHead : 35|4@0+ (1.0,0.0) [0.0|15.0] "Unitless" BBM
 SG_ AD4IMUStatIMUStat : 63|2@0+ (1,0) [0|3] "" BBM
 SG_ AD4IMUStatIMUTemp : 47|16@0- (0.01,0.0) [-50.0|150.0] "degC" BBM
 SG_ SecBrkSysSt_UB : 23|1@0+ (1,0) [0|1] "" BBM,VDDM
 SG_ SecBrkSysStBrkSysSt : 7|4@0+ (1,0) [0|15] "" BBM,VDDM
 SG_ SecBrkSysStChks : 15|8@0+ (1.0,0.0) [0.0|255.0] "Unitless" BBM,VDDM
 SG_ SecBrkSysStCntr : 3|4@0+ (1.0,0.0) [0.0|15.0] "Unitless" BBM,VDDM

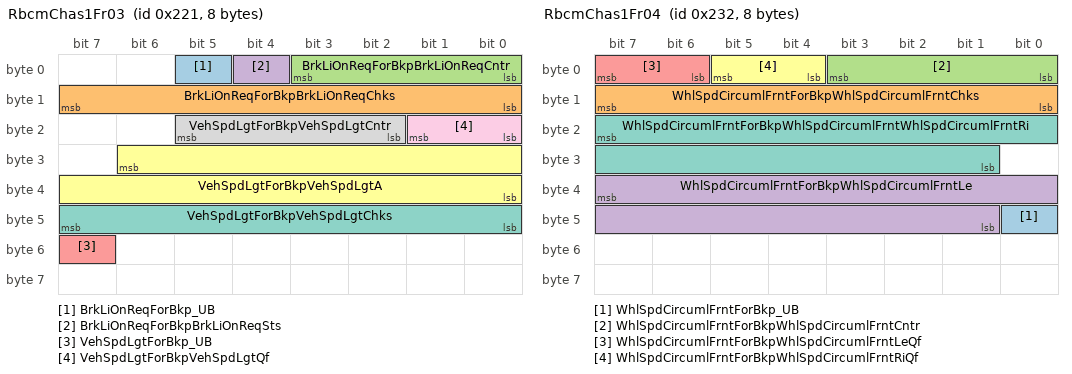
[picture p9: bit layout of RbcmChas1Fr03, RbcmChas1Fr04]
BO_ 545 RbcmChas1Fr03 : 8 RBCM
 SG_ BrkLiOnReqForBkp_UB : 5|1@0+ (1,0) [0|1] "" VDDM
 SG_ BrkLiOnReqForBkpBrkLiOnReqChks : 15|8@0+ (1.0,0.0) [0.0|255.0] "Unitless" VDDM
 SG_ BrkLiOnReqForBkpBrkLiOnReqCntr : 3|4@0+ (1.0,0.0) [0.0|15.0] "Unitless" VDDM
 SG_ BrkLiOnReqForBkpBrkLiOnReqSts : 4|1@0+ (1,0) [0|1] "" VDDM
 SG_ VehSpdLgtForBkp_UB : 55|1@0+ (1,0) [0|1] "" VDDM
 SG_ VehSpdLgtForBkpVehSpdLgtA : 30|15@0+ (0.00391,0.0) [0.0|125.0027] "m/s" VDDM
 SG_ VehSpdLgtForBkpVehSpdLgtChks : 47|8@0+ (1.0,0.0) [0.0|255.0] "Unitless" VDDM
 SG_ VehSpdLgtForBkpVehSpdLgtCntr : 21|4@0+ (1.0,0.0) [0.0|15.0] "Unitless" VDDM
 SG_ VehSpdLgtForBkpVehSpdLgtQf : 17|2@0+ (1,0) [0|3] "" VDDM

BO_ 562 RbcmChas1Fr04 : 8 RBCM
 SG_ WhlSpdCircumlFrntForBkp_UB : 40|1@0+ (1,0) [0|1] "" VDDM
 SG_ WhlSpdCircumlFrntForBkpWhlSpdCircumlFrntChks : 15|8@0+ (1.0,0.0) [0.0|255.0] "Unitless" VDDM
 SG_ WhlSpdCircumlFrntForBkpWhlSpdCircumlFrntCntr : 3|4@0+ (1.0,0.0) [0.0|15.0] "Unitless" VDDM
 SG_ WhlSpdCircumlFrntForBkpWhlSpdCircumlFrntLe : 39|15@0+ (0.00391,0.0) [0.0|125.0027] "m/s" VDDM
 SG_ WhlSpdCircumlFrntForBkpWhlSpdCircumlFrntLeQf : 7|2@0+ (1,0) [0|3] "" VDDM
 SG_ WhlSpdCircumlFrntForBkpWhlSpdCircumlFrntRiQf : 5|2@0+ (1,0) [0|3] "" VDDM
 SG_ WhlSpdCircumlFrntForBkpWhlSpdCircumlFrntWhlSpdCircumlFrntRi : 23|15@0+ (0.00391,0.0) [0.0|125.0027] "m/s" VDDM

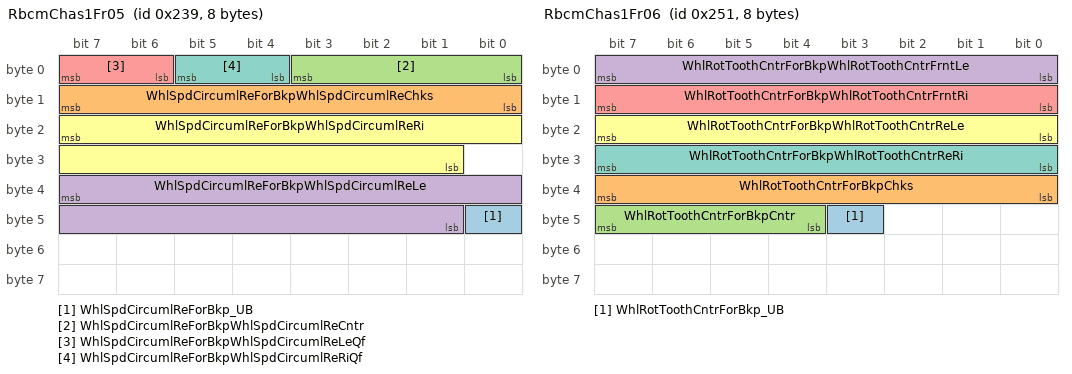
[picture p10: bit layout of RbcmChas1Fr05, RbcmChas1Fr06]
BO_ 569 RbcmChas1Fr05 : 8 RBCM
 SG_ WhlSpdCircumlReForBkp_UB : 40|1@0+ (1,0) [0|1] "" VDDM
 SG_ WhlSpdCircumlReForBkpWhlSpdCircumlReChks : 15|8@0+ (1.0,0.0) [0.0|255.0] "Unitless" VDDM
 SG_ WhlSpdCircumlReForBkpWhlSpdCircumlReCntr : 3|4@0+ (1.0,0.0) [0.0|15.0] "Unitless" VDDM
 SG_ WhlSpdCircumlReForBkpWhlSpdCircumlReLe : 39|15@0+ (0.00391,0.0) [0.0|125.0027] "m/s" VDDM
 SG_ WhlSpdCircumlReForBkpWhlSpdCircumlReLeQf : 7|2@0+ (1,0) [0|3] "" VDDM
 SG_ WhlSpdCircumlReForBkpWhlSpdCircumlReRi : 23|15@0+ (0.00391,0.0) [0.0|125.0027] "m/s" VDDM
 SG_ WhlSpdCircumlReForBkpWhlSpdCircumlReRiQf : 5|2@0+ (1,0) [0|3] "" VDDM

BO_ 593 RbcmChas1Fr06 : 8 RBCM
 SG_ WhlRotToothCntrForBkp_UB : 43|1@0+ (1,0) [0|1] "" VDDM
 SG_ WhlRotToothCntrForBkpChks : 39|8@0+ (1.0,0.0) [0.0|255.0] "Unitless" VDDM
 SG_ WhlRotToothCntrForBkpCntr : 47|4@0+ (1.0,0.0) [0.0|15.0] "Unitless" VDDM
 SG_ WhlRotToothCntrForBkpWhlRotToothCntrFrntLe : 7|8@0+ (1.0,0.0) [0.0|255.0] "Unitless" VDDM
 SG_ WhlRotToothCntrForBkpWhlRotToothCntrFrntRi : 15|8@0+ (1.0,0.0) [0.0|255.0] "Unitless" VDDM
 SG_ WhlRotToothCntrForBkpWhlRotToothCntrReLe : 23|8@0+ (1.0,0.0) [0.0|255.0] "Unitless" VDDM
 SG_ WhlRotToothCntrForBkpWhlRotToothCntrReRi : 31|8@0+ (1.0,0.0) [0.0|255.0] "Unitless" VDDM

BO_ 323 RbcmChas1Fr09 : 8 RBCM
 SG_ AD4IMUAcceX_UB : 56|1@0+ (1,0) [0|1] "" BBM
 SG_ AD4IMUAcceXAcce : 7|32@0- (0.00002,0.0) [-10.0|10.0] "g" BBM
 SG_ AD4IMUAcceXChks : 39|8@0+ (1.0,0.0) [0.0|255.0] "Unitless" BBM
 SG_ AD4IMUAcceXCntr : 47|4@0+ (1.0,0.0) [0.0|15.0] "Unitless" BBM
 SG_ AD4IMUAcceXHead : 43|4@0+ (1.0,0.0) [0.0|15.0] "Unitless" BBM

BO_ 177 RbcmChas1Fr10 : 8 RBCM
 SG_ AD4IMUAcceY_UB : 56|1@0+ (1,0) [0|1] "" BBM
 SG_ AD4IMUAcceYAcce : 7|32@0- (0.00002,0.0) [-10.0|10.0] "g" BBM
 SG_ AD4IMUAcceYChks : 39|8@0+ (1.0,0.0) [0.0|255.0] "Unitless" BBM
 SG_ AD4IMUAcceYCntr : 47|4@0+ (1.0,0.0) [0.0|15.0] "Unitless" BBM
 SG_ AD4IMUAcceYHead : 43|4@0+ (1.0,0.0) [0.0|15.0] "Unitless" BBM

BO_ 181 RbcmChas1Fr11 : 8 RBCM
 SG_ AD4IMUAcceZ_UB : 56|1@0+ (1,0) [0|1] "" BBM
 SG_ AD4IMUAcceZAcce : 7|32@0- (0.00002,0.0) [-10.0|10.0] "g" BBM
 SG_ AD4IMUAcceZChks : 39|8@0+ (1.0,0.0) [0.0|255.0] "Unitless" BBM
 SG_ AD4IMUAcceZCntr : 47|4@0+ (1.0,0.0) [0.0|15.0] "Unitless" BBM
 SG_ AD4IMUAcceZHead : 43|4@0+ (1.0,0.0) [0.0|15.0] "Unitless" BBM

BO_ 193 RbcmChas1Fr12 : 8 RBCM
 SG_ AD4IMUGyroX_UB : 56|1@0+ (1,0) [0|1] "" BBM
 SG_ AD4IMUGyroXChks : 7|8@0+ (1.0,0.0) [0.0|255.0] "Unitless" BBM
 SG_ AD4IMUGyroXCntr : 15|4@0+ (1.0,0.0) [0.0|15.0] "Unitless" BBM
 SG_ AD4IMUGyroXGyro : 23|32@0- (0.001,0.0) [-500.0|500.0] "DegPerSec" BBM
 SG_ AD4IMUGyroXHead : 11|4@0+ (1.0,0.0) [0.0|15.0] "Unitless" BBM

BO_ 200 RbcmChas1Fr13 : 8 RBCM
 SG_ AD4IMUGyroY_UB : 56|1@0+ (1,0) [0|1] "" BBM
 SG_ AD4IMUGyroYChks : 7|8@0+ (1.0,0.0) [0.0|255.0] "Unitless" BBM
 SG_ AD4IMUGyroYCntr : 15|4@0+ (1.0,0.0) [0.0|15.0] "Unitless" BBM
 SG_ AD4IMUGyroYGyro : 23|32@0- (0.001,0.0) [-500.0|500.0] "DegPerSec" BBM
 SG_ AD4IMUGyroYHead : 11|4@0+ (1.0,0.0) [0.0|15.0] "Unitless" BBM

BO_ 166 RbcmChas1Fr14 : 8 RBCM
 SG_ AD4IMUGyroZ_UB : 56|1@0+ (1,0) [0|1] "" BBM
 SG_ AD4IMUGyroZChks : 7|8@0+ (1.0,0.0) [0.0|255.0] "Unitless" BBM
 SG_ AD4IMUGyroZCntr : 15|4@0+ (1.0,0.0) [0.0|15.0] "Unitless" BBM
 SG_ AD4IMUGyroZGyro : 23|32@0- (0.001,0.0) [-500.0|500.0] "DegPerSec" BBM
 SG_ AD4IMUGyroZHead : 11|4@0+ (1.0,0.0) [0.0|15.0] "Unitless" BBM

BO_ 1333 RbcmChas1NMFr : 8 RBCM
 SG_ PNC16_RBCM : 16|1@0+ (1,0) [0|0] "" VDDM
 SG_ PNC17_RBCM : 17|1@0+ (1,0) [0|0] "" VDDM
 SG_ PNC18_RBCM : 18|1@0+ (1,0) [0|0] "" VDDM
 SG_ PNC19_RBCM : 19|1@0+ (1,0) [0|0] "" VDDM
 SG_ PNC20_RBCM : 20|1@0+ (1,0) [0|0] "" VDDM
 SG_ PNC21_RBCM : 21|1@0+ (1,0) [0|0] "" VDDM
 SG_ PNC22_RBCM : 22|1@0+ (1,0) [0|0] "" VDDM
 SG_ PNC23_RBCM : 23|1@0+ (1,0) [0|0] "" VDDM
 SG_ PNC24_RBCM : 24|1@0+ (1,0) [0|0] "" VDDM
 SG_ PNC25_RBCM : 25|1@0+ (1,0) [0|0] "" VDDM
 SG_ PNC26_RBCM : 26|1@0+ (1,0) [0|0] "" VDDM
 SG_ PNC27_RBCM : 27|1@0+ (1,0) [0|0] "" VDDM
 SG_ PNC28_RBCM : 28|1@0+ (1,0) [0|0] "" VDDM
 SG_ PNC29_RBCM : 29|1@0+ (1,0) [0|0] "" VDDM
 SG_ PNC30_RBCM : 30|1@0+ (1,0) [0|0] "" VDDM
 SG_ PNC31_RBCM : 31|1@0+ (1,0) [0|0] "" VDDM
 SG_ PNC32_RBCM : 32|1@0+ (1,0) [0|0] "" VDDM
 SG_ PNC33_RBCM : 33|1@0+ (1,0) [0|0] "" VDDM
 SG_ PNC34_RBCM : 34|1@0+ (1,0) [0|0] "" VDDM
 SG_ PNC35_RBCM : 35|1@0+ (1,0) [0|0] "" VDDM
 SG_ PNC36_RBCM : 36|1@0+ (1,0) [0|0] "" VDDM
 SG_ PNC37_RBCM : 37|1@0+ (1,0) [0|0] "" VDDM
 SG_ PNC38_RBCM : 38|1@0+ (1,0) [0|0] "" VDDM
 SG_ PNC39_RBCM : 39|1@0+ (1,0) [0|0] "" VDDM
 SG_ PNC40_RBCM : 40|1@0+ (1,0) [0|0] "" VDDM
 SG_ PNC41_RBCM : 41|1@0+ (1,0) [0|0] "" VDDM
 SG_ PNC42_RBCM : 42|1@0+ (1,0) [0|0] "" VDDM
 SG_ NM_PNI_RBCM : 14|1@0+ (1,0) [0|0] "" VDDM
 SG_ NM_AW_RBCM : 12|1@0+ (1,0) [0|0] "" VDDM
 SG_ NM_CS_RBCM : 11|1@0+ (1,0) [0|0] "" VDDM
 SG_ NM_RMR_RBCM : 8|1@0+ (1,0) [0|0] "" VDDM
 SG_ NM_NodeID_RBCM : 7|8@0+ (1,0) [0|0] "" VDDM

BO_ 1383 RbcmChas1VFCVectorFr : 8 RBCM
 SG_ VFCVectorRBCMBlockID : 1|2@0+ (1.0,0.0) [0.0|3.0] "Unitless" ETC
 SG_ VFCVectorRBCMVFCid0 : 2|1@0+ (1,0) [0|1] "" ETC
 SG_ VFCVectorRBCMVFCid1 : 3|1@0+ (1,0) [0|1] "" ETC
 SG_ VFCVectorRBCMVFCid10 : 12|1@0+ (1,0) [0|1] "" ETC
 SG_ VFCVectorRBCMVFCid11 : 13|1@0+ (1,0) [0|1] "" ETC
 SG_ VFCVectorRBCMVFCid12 : 14|1@0+ (1,0) [0|1] "" ETC
 SG_ VFCVectorRBCMVFCid13 : 15|1@0+ (1,0) [0|1] "" ETC
 SG_ VFCVectorRBCMVFCid14 : 16|1@0+ (1,0) [0|1] "" ETC
 SG_ VFCVectorRBCMVFCid15 : 17|1@0+ (1,0) [0|1] "" ETC
 SG_ VFCVectorRBCMVFCid16 : 18|1@0+ (1,0) [0|1] "" ETC
 SG_ VFCVectorRBCMVFCid17 : 19|1@0+ (1,0) [0|1] "" ETC
 SG_ VFCVectorRBCMVFCid18 : 20|1@0+ (1,0) [0|1] "" ETC
 SG_ VFCVectorRBCMVFCid19 : 21|1@0+ (1,0) [0|1] "" ETC
 SG_ VFCVectorRBCMVFCid2 : 4|1@0+ (1,0) [0|1] "" ETC
 SG_ VFCVectorRBCMVFCid20 : 22|1@0+ (1,0) [0|1] "" ETC
 SG_ VFCVectorRBCMVFCid21 : 23|1@0+ (1,0) [0|1] "" ETC
 SG_ VFCVectorRBCMVFCid22 : 24|1@0+ (1,0) [0|1] "" ETC
 SG_ VFCVectorRBCMVFCid23 : 25|1@0+ (1,0) [0|1] "" ETC
 SG_ VFCVectorRBCMVFCid24 : 26|1@0+ (1,0) [0|1] "" ETC
 SG_ VFCVectorRBCMVFCid25 : 27|1@0+ (1,0) [0|1] "" ETC
 SG_ VFCVectorRBCMVFCid26 : 28|1@0+ (1,0) [0|1] "" ETC
 SG_ VFCVectorRBCMVFCid27 : 29|1@0+ (1,0) [0|1] "" ETC
 SG_ VFCVectorRBCMVFCid28 : 30|1@0+ (1,0) [0|1] "" ETC
 SG_ VFCVectorRBCMVFCid29 : 31|1@0+ (1,0) [0|1] "" ETC
 SG_ VFCVectorRBCMVFCid3 : 5|1@0+ (1,0) [0|1] "" ETC
 SG_ VFCVectorRBCMVFCid30 : 32|1@0+ (1,0) [0|1] "" ETC
 SG_ VFCVectorRBCMVFCid31 : 33|1@0+ (1,0) [0|1] "" ETC
 SG_ VFCVectorRBCMVFCid32 : 34|1@0+ (1,0) [0|1] "" ETC
 SG_ VFCVectorRBCMVFCid33 : 35|1@0+ (1,0) [0|1] "" ETC
 SG_ VFCVectorRBCMVFCid34 : 36|1@0+ (1,0) [0|1] "" ETC
 SG_ VFCVectorRBCMVFCid35 : 37|1@0+ (1,0) [0|1] "" ETC
 SG_ VFCVectorRBCMVFCid36 : 38|1@0+ (1,0) [0|1] "" ETC
 SG_ VFCVectorRBCMVFCid37 : 39|1@0+ (1,0) [0|1] "" ETC
 SG_ VFCVectorRBCMVFCid38 : 40|1@0+ (1,0) [0|1] "" ETC
 SG_ VFCVectorRBCMVFCid39 : 41|1@0+ (1,0) [0|1] "" ETC
 SG_ VFCVectorRBCMVFCid4 : 6|1@0+ (1,0) [0|1] "" ETC
 SG_ VFCVectorRBCMVFCid40 : 42|1@0+ (1,0) [0|1] "" ETC
 SG_ VFCVectorRBCMVFCid41 : 43|1@0+ (1,0) [0|1] "" ETC
 SG_ VFCVectorRBCMVFCid42 : 44|1@0+ (1,0) [0|1] "" ETC
 SG_ VFCVectorRBCMVFCid43 : 45|1@0+ (1,0) [0|1] "" ETC
 SG_ VFCVectorRBCMVFCid44 : 46|1@0+ (1,0) [0|1] "" ETC
 SG_ VFCVectorRBCMVFCid45 : 47|1@0+ (1,0) [0|1] "" ETC
 SG_ VFCVectorRBCMVFCid46 : 48|1@0+ (1,0) [0|1] "" ETC
 SG_ VFCVectorRBCMVFCid47 : 49|1@0+ (1,0) [0|1] "" ETC
 SG_ VFCVectorRBCMVFCid48 : 50|1@0+ (1,0) [0|1] "" ETC
 SG_ VFCVectorRBCMVFCid49 : 51|1@0+ (1,0) [0|1] "" ETC
 SG_ VFCVectorRBCMVFCid5 : 7|1@0+ (1,0) [0|1] "" ETC
 SG_ VFCVectorRBCMVFCid50 : 52|1@0+ (1,0) [0|1] "" ETC
 SG_ VFCVectorRBCMVFCid51 : 53|1@0+ (1,0) [0|1] "" ETC
 SG_ VFCVectorRBCMVFCid52 : 54|1@0+ (1,0) [0|1] "" ETC
 SG_ VFCVectorRBCMVFCid53 : 55|1@0+ (1,0) [0|1] "" ETC
 SG_ VFCVectorRBCMVFCid54 : 56|1@0+ (1,0) [0|1] "" ETC
 SG_ VFCVectorRBCMVFCid55 : 57|1@0+ (1,0) [0|1] "" ETC
 SG_ VFCVectorRBCMVFCid56 : 58|1@0+ (1,0) [0|1] "" ETC
 SG_ VFCVectorRBCMVFCid57 : 59|1@0+ (1,0) [0|1] "" ETC
 SG_ VFCVectorRBCMVFCid58 : 60|1@0+ (1,0) [0|1] "" ETC
 SG_ VFCVectorRBCMVFCid59 : 61|1@0+ (1,0) [0|1] "" ETC
 SG_ VFCVectorRBCMVFCid6 : 8|1@0+ (1,0) [0|1] "" ETC
 SG_ VFCVectorRBCMVFCid60 : 62|1@0+ (1,0) [0|1] "" ETC
 SG_ VFCVectorRBCMVFCid61 : 63|1@0+ (1,0) [0|1] "" ETC
 SG_ VFCVectorRBCMVFCid7 : 9|1@0+ (1,0) [0|1] "" ETC
 SG_ VFCVectorRBCMVFCid8 : 10|1@0+ (1,0) [0|1] "" ETC
 SG_ VFCVectorRBCMVFCid9 : 11|1@0+ (1,0) [0|1] "" ETC

BO_ 1653 RbcmToVddmChas1DiagResFrame : 8 RBCM
 SG_ RbcmToVddmChas1DiagResNpdu : 7|64@0+ (1,0) [0|0] "" VDDM

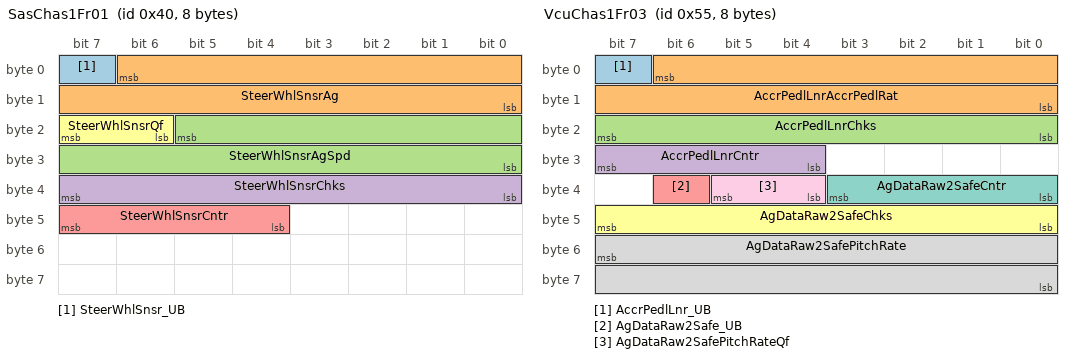
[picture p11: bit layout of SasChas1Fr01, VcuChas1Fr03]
BO_ 64 SasChas1Fr01 : 8 SAS
 SG_ SteerWhlSnsr_UB : 7|1@0+ (1,0) [0|1] "" ASDM,BBM,PSCM1,RBCM,VDDM
 SG_ SteerWhlSnsrAg : 6|15@0- (0.0009765625,0.0) [-14.5|14.5] "rad" ASDM,BBM,PSCM1,RBCM,VDDM
 SG_ SteerWhlSnsrAgSpd : 21|14@0- (0.0078125,0.0) [-50.0|50.0] "rad/s" ASDM,BBM,PSCM1,RBCM,VDDM
 SG_ SteerWhlSnsrChks : 39|8@0+ (1.0,0.0) [0.0|255.0] "Unitless" ASDM,BBM,PSCM1,RBCM,VDDM
 SG_ SteerWhlSnsrCntr : 47|4@0+ (1.0,0.0) [0.0|15.0] "Unitless" ASDM,BBM,PSCM1,RBCM,VDDM
 SG_ SteerWhlSnsrQf : 23|2@0+ (1,0) [0|3] "" ASDM,BBM,PSCM1,RBCM,VDDM

BO_ 1319 SasChas1NMFr : 8 SAS
 SG_ PNC16_SAS : 16|1@0+ (1,0) [0|0] "" RBCM
 SG_ PNC17_SAS : 17|1@0+ (1,0) [0|0] "" RBCM
 SG_ PNC18_SAS : 18|1@0+ (1,0) [0|0] "" RBCM
 SG_ PNC19_SAS : 19|1@0+ (1,0) [0|0] "" RBCM
 SG_ PNC20_SAS : 20|1@0+ (1,0) [0|0] "" RBCM
 SG_ PNC21_SAS : 21|1@0+ (1,0) [0|0] "" RBCM
 SG_ PNC22_SAS : 22|1@0+ (1,0) [0|0] "" RBCM
 SG_ PNC23_SAS : 23|1@0+ (1,0) [0|0] "" RBCM
 SG_ PNC24_SAS : 24|1@0+ (1,0) [0|0] "" RBCM
 SG_ PNC25_SAS : 25|1@0+ (1,0) [0|0] "" RBCM
 SG_ PNC26_SAS : 26|1@0+ (1,0) [0|0] "" RBCM
 SG_ PNC27_SAS : 27|1@0+ (1,0) [0|0] "" RBCM
 SG_ PNC28_SAS : 28|1@0+ (1,0) [0|0] "" RBCM
 SG_ PNC29_SAS : 29|1@0+ (1,0) [0|0] "" RBCM
 SG_ PNC30_SAS : 30|1@0+ (1,0) [0|0] "" RBCM
 SG_ PNC31_SAS : 31|1@0+ (1,0) [0|0] "" RBCM
 SG_ PNC32_SAS : 32|1@0+ (1,0) [0|0] "" RBCM
 SG_ PNC33_SAS : 33|1@0+ (1,0) [0|0] "" RBCM
 SG_ PNC34_SAS : 34|1@0+ (1,0) [0|0] "" RBCM
 SG_ PNC35_SAS : 35|1@0+ (1,0) [0|0] "" RBCM
 SG_ PNC36_SAS : 36|1@0+ (1,0) [0|0] "" RBCM
 SG_ PNC37_SAS : 37|1@0+ (1,0) [0|0] "" RBCM
 SG_ PNC38_SAS : 38|1@0+ (1,0) [0|0] "" RBCM
 SG_ PNC39_SAS : 39|1@0+ (1,0) [0|0] "" RBCM
 SG_ PNC40_SAS : 40|1@0+ (1,0) [0|0] "" RBCM
 SG_ PNC41_SAS : 41|1@0+ (1,0) [0|0] "" RBCM
 SG_ PNC42_SAS : 42|1@0+ (1,0) [0|0] "" RBCM
 SG_ NM_PNI_SAS : 14|1@0+ (1,0) [0|0] "" RBCM
 SG_ NM_AW_SAS : 12|1@0+ (1,0) [0|0] "" RBCM
 SG_ NM_CS_SAS : 11|1@0+ (1,0) [0|0] "" RBCM
 SG_ NM_RMR_SAS : 8|1@0+ (1,0) [0|0] "" RBCM
 SG_ NM_NodeID_SAS : 7|8@0+ (1,0) [0|0] "" RBCM

BO_ 1650 SasToVddmChas1DiagResFrame : 8 SAS
 SG_ SasToVddmChas1DiagResNpdu : 7|64@0+ (1,0) [0|0] "" VDDM

BO_ 54 VcuChas1Fr01 : 8 VDDM
 SG_ PrpsnTqReReq : 55|16@0- (1.0,0.0) [-20000.0|20000.0] "NewtonMeter" Vector__XXX
 SG_ PrpsnTqReReq_UB : 19|1@0+ (1,0) [0|1] "" Vector__XXX

BO_ 274 VcuChas1Fr02 : 8 VDDM
 SG_ SecParkBrkSysSt2_UB : 23|1@0+ (1,0) [0|1] "" BBM
 SG_ SecParkBrkSysSt2BrkSysSt : 7|4@0+ (1,0) [0|15] "" BBM
 SG_ SecParkBrkSysSt2Chks : 15|8@0+ (1.0,0.0) [0.0|255.0] "Unitless" BBM
 SG_ SecParkBrkSysSt2Cntr : 3|4@0+ (1.0,0.0) [0.0|15.0] "Unitless" BBM

BO_ 85 VcuChas1Fr03 : 8 VDDM
 SG_ AccrPedlLnr_UB : 7|1@0+ (1,0) [0|1] "" Vector__XXX
 SG_ AccrPedlLnrAccrPedlRat : 6|15@0+ (0.00390625,0.0) [0.0|100.0] "%" Vector__XXX
 SG_ AccrPedlLnrChks : 23|8@0+ (1.0,0.0) [0.0|255.0] "Unitless" Vector__XXX
 SG_ AccrPedlLnrCntr : 31|4@0+ (1.0,0.0) [0.0|15.0] "Unitless" Vector__XXX
 SG_ AgDataRaw2Safe_UB : 38|1@0+ (1,0) [0|1] "" RBCM
 SG_ AgDataRaw2SafeChks : 47|8@0+ (1.0,0.0) [0.0|255.0] "Unitless" RBCM
 SG_ AgDataRaw2SafeCntr : 35|4@0+ (1.0,0.0) [0.0|15.0] "Unitless" RBCM
 SG_ AgDataRaw2SafePitchRate : 55|16@0- (0.000244140625,0.0) [-6.0|6.0] "rad/s" RBCM
 SG_ AgDataRaw2SafePitchRateQf : 37|2@0+ (1,0) [0|3] "" RBCM

BO_ 375 VcuChas1Fr04 : 8 VDDM
 SG_ RlyPwrDistbnCmd1WdIgnRlyCmd : 58|1@0+ (1,0) [0|1] "" RBCM
 SG_ RlyPwrDistbnCmd1WdIgnRlyCmd_UB : 57|1@0+ (1,0) [0|1] "" RBCM

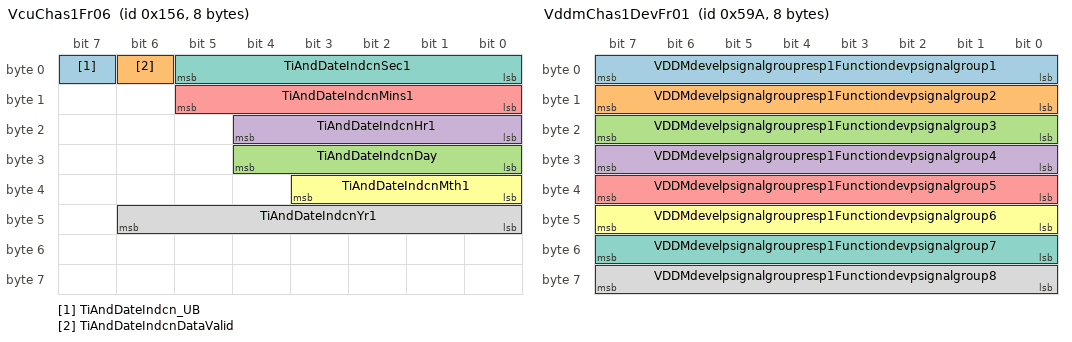
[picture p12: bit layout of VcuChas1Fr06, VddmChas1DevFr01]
BO_ 342 VcuChas1Fr06 : 8 VDDM
 SG_ TiAndDateIndcn_UB : 7|1@0+ (1,0) [0|1] "" PSCM1,RBCM
 SG_ TiAndDateIndcnDataValid : 6|1@0+ (1,0) [0|1] "" PSCM1,RBCM
 SG_ TiAndDateIndcnDay : 28|5@0+ (1.0,0.0) [1.0|31.0] "Days" PSCM1,RBCM
 SG_ TiAndDateIndcnHr1 : 20|5@0+ (1.0,0.0) [0.0|23.0] "hours" PSCM1,RBCM
 SG_ TiAndDateIndcnMins1 : 13|6@0+ (1.0,0.0) [0.0|59.0] "Mins" PSCM1,RBCM
 SG_ TiAndDateIndcnMth1 : 35|4@0+ (1.0,0.0) [1.0|12.0] "Month" PSCM1,RBCM
 SG_ TiAndDateIndcnSec1 : 5|6@0+ (1.0,0.0) [0.0|59.0] "s" PSCM1,RBCM
 SG_ TiAndDateIndcnYr1 : 46|7@0+ (1.0,0.0) [0.0|99.0] "Year" PSCM1,RBCM

BO_ 1434 VddmChas1DevFr01 : 8 BBM
 SG_ VDDMdevelpsignalgroupresp1Functiondevpsignalgroup1 : 7|8@0+ (1.0,0.0) [0.0|255.0] "Unitless" ETC
 SG_ VDDMdevelpsignalgroupresp1Functiondevpsignalgroup2 : 15|8@0+ (1.0,0.0) [0.0|255.0] "Unitless" ETC
 SG_ VDDMdevelpsignalgroupresp1Functiondevpsignalgroup3 : 23|8@0+ (1.0,0.0) [0.0|255.0] "Unitless" ETC
 SG_ VDDMdevelpsignalgroupresp1Functiondevpsignalgroup4 : 31|8@0+ (1.0,0.0) [0.0|255.0] "Unitless" ETC
 SG_ VDDMdevelpsignalgroupresp1Functiondevpsignalgroup5 : 39|8@0+ (1.0,0.0) [0.0|255.0] "Unitless" ETC
 SG_ VDDMdevelpsignalgroupresp1Functiondevpsignalgroup6 : 47|8@0+ (1.0,0.0) [0.0|255.0] "Unitless" ETC
 SG_ VDDMdevelpsignalgroupresp1Functiondevpsignalgroup7 : 55|8@0+ (1.0,0.0) [0.0|255.0] "Unitless" ETC
 SG_ VDDMdevelpsignalgroupresp1Functiondevpsignalgroup8 : 63|8@0+ (1.0,0.0) [0.0|255.0] "Unitless" ETC

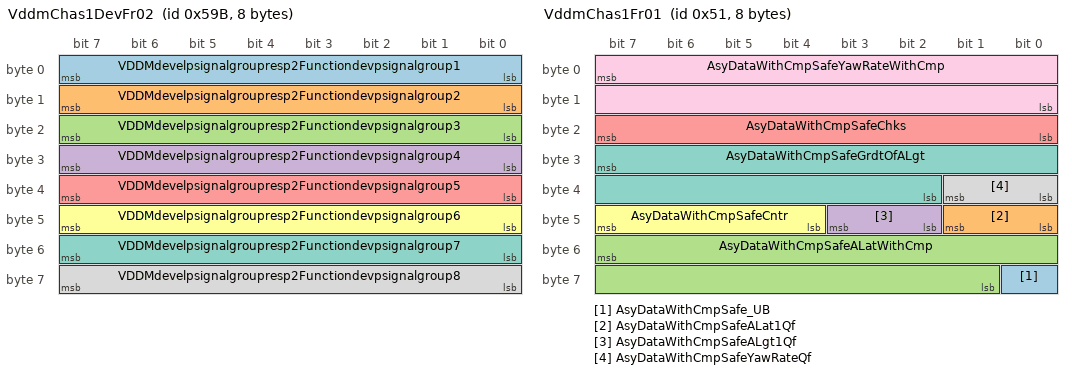
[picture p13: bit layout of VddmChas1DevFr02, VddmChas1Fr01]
BO_ 1435 VddmChas1DevFr02 : 8 BBM
 SG_ VDDMdevelpsignalgroupresp2Functiondevpsignalgroup1 : 7|8@0+ (1.0,0.0) [0.0|255.0] "Unitless" ETC
 SG_ VDDMdevelpsignalgroupresp2Functiondevpsignalgroup2 : 15|8@0+ (1.0,0.0) [0.0|255.0] "Unitless" ETC
 SG_ VDDMdevelpsignalgroupresp2Functiondevpsignalgroup3 : 23|8@0+ (1.0,0.0) [0.0|255.0] "Unitless" ETC
 SG_ VDDMdevelpsignalgroupresp2Functiondevpsignalgroup4 : 31|8@0+ (1.0,0.0) [0.0|255.0] "Unitless" ETC
 SG_ VDDMdevelpsignalgroupresp2Functiondevpsignalgroup5 : 39|8@0+ (1.0,0.0) [0.0|255.0] "Unitless" ETC
 SG_ VDDMdevelpsignalgroupresp2Functiondevpsignalgroup6 : 47|8@0+ (1.0,0.0) [0.0|255.0] "Unitless" ETC
 SG_ VDDMdevelpsignalgroupresp2Functiondevpsignalgroup7 : 55|8@0+ (1.0,0.0) [0.0|255.0] "Unitless" ETC
 SG_ VDDMdevelpsignalgroupresp2Functiondevpsignalgroup8 : 63|8@0+ (1.0,0.0) [0.0|255.0] "Unitless" ETC

BO_ 81 VddmChas1Fr01 : 8 VDDM
 SG_ AsyDataWithCmpSafe_UB : 56|1@0+ (1,0) [0|1] "" PSCM1
 SG_ AsyDataWithCmpSafeALat1Qf : 41|2@0+ (1,0) [0|3] "" PSCM1
 SG_ AsyDataWithCmpSafeALatWithCmp : 55|15@0- (0.0085,0.0) [-138.99200000000002|139.00050000000002] "m/s^2" PSCM1
 SG_ AsyDataWithCmpSafeALgt1Qf : 43|2@0+ (1,0) [0|3] "" PSCM1
 SG_ AsyDataWithCmpSafeChks : 23|8@0+ (1.0,0.0) [0.0|255.0] "Unitless" PSCM1
 SG_ AsyDataWithCmpSafeCntr : 47|4@0+ (1.0,0.0) [0.0|15.0] "Unitless" PSCM1
 SG_ AsyDataWithCmpSafeGrdtOfALgt : 31|14@0- (0.00390625,0.0) [-30.0|30.0] "m/s^3" PSCM1
 SG_ AsyDataWithCmpSafeYawRateQf : 33|2@0+ (1,0) [0|3] "" PSCM1
 SG_ AsyDataWithCmpSafeYawRateWithCmp : 7|16@0- (0.000244140625,0.0) [-6.0|6.0] "rad/s" PSCM1

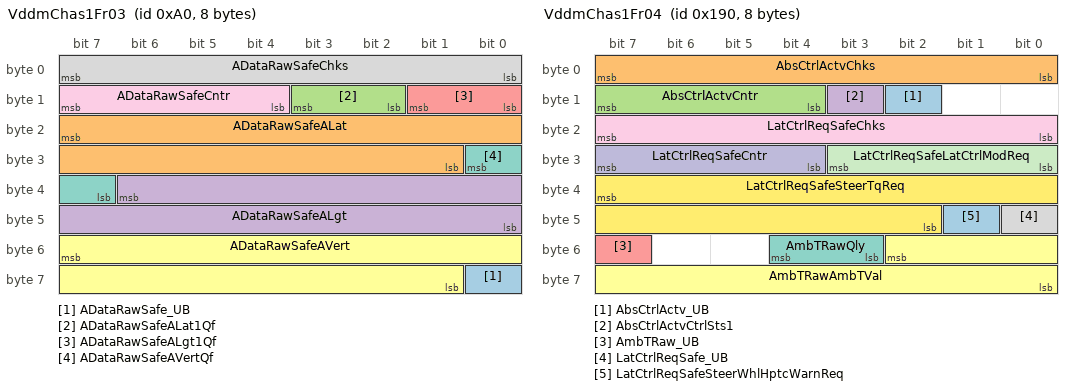
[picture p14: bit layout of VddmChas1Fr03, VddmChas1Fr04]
BO_ 160 VddmChas1Fr03 : 8 VDDM
 SG_ ADataRawSafe_UB : 56|1@0+ (1,0) [0|1] "" PSCM1,RBCM
 SG_ ADataRawSafeALat : 23|15@0- (0.0085,0.0) [-138.99200000000002|139.00050000000002] "m/s^2" PSCM1,RBCM
 SG_ ADataRawSafeALat1Qf : 11|2@0+ (1,0) [0|3] "" PSCM1,RBCM
 SG_ ADataRawSafeALgt : 38|15@0- (0.0085,0.0) [-138.99200000000002|139.00050000000002] "m/s^2" PSCM1,RBCM
 SG_ ADataRawSafeALgt1Qf : 9|2@0+ (1,0) [0|3] "" PSCM1,RBCM
 SG_ ADataRawSafeAVert : 55|15@0- (0.0085,0.0) [-138.99200000000002|139.00050000000002] "m/s^2" PSCM1,RBCM
 SG_ ADataRawSafeAVertQf : 24|2@0+ (1,0) [0|3] "" PSCM1,RBCM
 SG_ ADataRawSafeChks : 7|8@0+ (1.0,0.0) [0.0|255.0] "Unitless" PSCM1,RBCM
 SG_ ADataRawSafeCntr : 15|4@0+ (1.0,0.0) [0.0|15.0] "Unitless" PSCM1,RBCM

BO_ 400 VddmChas1Fr04 : 8 BBM
 SG_ AbsCtrlActv_UB : 10|1@0+ (1,0) [0|1] "" PSCM1
 SG_ AbsCtrlActvChks : 7|8@0+ (1.0,0.0) [0.0|255.0] "Unitless" PSCM1
 SG_ AbsCtrlActvCntr : 15|4@0+ (1.0,0.0) [0.0|15.0] "Unitless" PSCM1
 SG_ AbsCtrlActvCtrlSts1 : 11|1@0+ (1,0) [0|1] "" PSCM1
 SG_ AmbTRaw_UB : 55|1@0+ (1,0) [0|1] "" PSCM1
 SG_ AmbTRawAmbTVal : 50|11@0+ (0.1,-70.0) [-70.0|134.70000000000002] "degC" PSCM1
 SG_ AmbTRawQly : 52|2@0+ (1,0) [0|3] "" PSCM1
 SG_ LatCtrlReqSafe_UB : 40|1@0+ (1,0) [0|1] "" PSCM1
 SG_ LatCtrlReqSafeChks : 23|8@0+ (1.0,0.0) [0.0|255.0] "Unitless" PSCM1
 SG_ LatCtrlReqSafeCntr : 31|4@0+ (1.0,0.0) [0.0|15.0] "Unitless" PSCM1
 SG_ LatCtrlReqSafeLatCtrlModReq : 27|4@0+ (1,0) [0|15] "" PSCM1
 SG_ LatCtrlReqSafeSteerTqReq : 39|14@0- (0.00390625,0.0) [-30.0|30.0] "NewtonMeter" PSCM1
 SG_ LatCtrlReqSafeSteerWhlHptcWarnReq : 41|1@0+ (1,0) [0|1] "" PSCM1

BO_ 224 VddmChas1Fr05 : 8 BBM
 SG_ VehSpdLgt_UB : 39|1@0+ (1,0) [0|1] "" PSCM1,SAS
 SG_ VehSpdLgtA : 38|15@0+ (0.00391,0.0) [0.0|125.0027] "m/s" PSCM1,SAS
 SG_ VehSpdLgtChks : 55|8@0+ (1.0,0.0) [0.0|255.0] "Unitless" PSCM1,SAS
 SG_ VehSpdLgtCntr : 63|4@0+ (1.0,0.0) [0.0|15.0] "Unitless" PSCM1,SAS
 SG_ VehSpdLgtQf : 59|2@0+ (1,0) [0|3] "" PSCM1,SAS

BO_ 928 VddmChas1Fr08 : 8 BBM
 SG_ AmbTIndcdWithUnit_UB : 9|1@0+ (1,0) [0|1] "" SAS
 SG_ AmbTIndcdWithUnitAmbTIndcd : 19|12@0+ (0.1,-100.0) [-100.0|309.5] "Unitless" SAS
 SG_ AmbTIndcdWithUnitAmbTIndcdUnit : 23|2@0+ (1,0) [0|3] "" SAS
 SG_ AmbTIndcdWithUnitQF : 21|2@0+ (1,0) [0|3] "" SAS

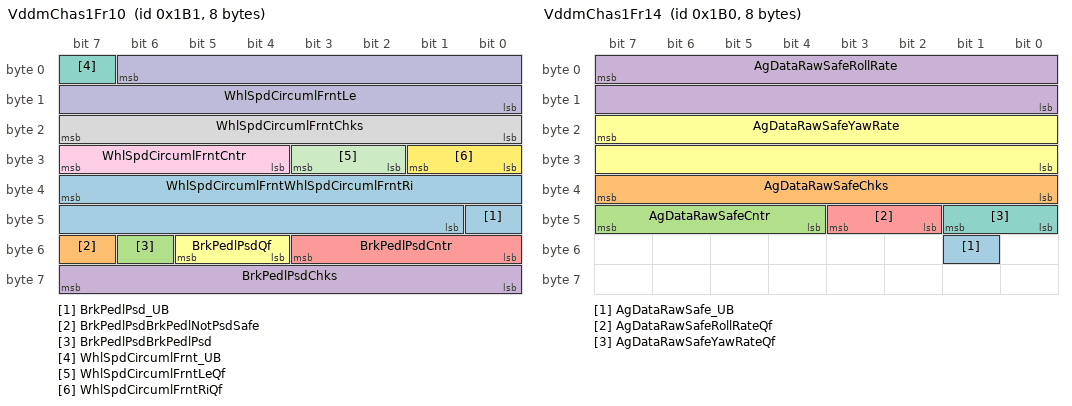
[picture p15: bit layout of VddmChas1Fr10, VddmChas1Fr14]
BO_ 433 VddmChas1Fr10 : 8 BBM
 SG_ BrkPedlPsd_UB : 40|1@0+ (1,0) [0|1] "" PSCM1
 SG_ BrkPedlPsdBrkPedlNotPsdSafe : 55|1@0+ (1,0) [0|1] "" PSCM1
 SG_ BrkPedlPsdBrkPedlPsd : 54|1@0+ (1,0) [0|1] "" PSCM1
 SG_ BrkPedlPsdChks : 63|8@0+ (1.0,0.0) [0.0|255.0] "Unitless" PSCM1
 SG_ BrkPedlPsdCntr : 51|4@0+ (1.0,0.0) [0.0|15.0] "Unitless" PSCM1
 SG_ BrkPedlPsdQf : 53|2@0+ (1,0) [0|3] "" PSCM1
 SG_ WhlSpdCircumlFrnt_UB : 7|1@0+ (1,0) [0|1] "" PSCM1
 SG_ WhlSpdCircumlFrntChks : 23|8@0+ (1.0,0.0) [0.0|255.0] "Unitless" PSCM1
 SG_ WhlSpdCircumlFrntCntr : 31|4@0+ (1.0,0.0) [0.0|15.0] "Unitless" PSCM1
 SG_ WhlSpdCircumlFrntLe : 6|15@0+ (0.00391,0.0) [0.0|125.0027] "m/s" PSCM1
 SG_ WhlSpdCircumlFrntLeQf : 27|2@0+ (1,0) [0|3] "" PSCM1
 SG_ WhlSpdCircumlFrntRiQf : 25|2@0+ (1,0) [0|3] "" PSCM1
 SG_ WhlSpdCircumlFrntWhlSpdCircumlFrntRi : 39|15@0+ (0.00391,0.0) [0.0|125.0027] "m/s" PSCM1

BO_ 432 VddmChas1Fr14 : 8 VDDM
 SG_ AgDataRawSafe_UB : 49|1@0+ (1,0) [0|1] "" PSCM1,RBCM
 SG_ AgDataRawSafeChks : 39|8@0+ (1.0,0.0) [0.0|255.0] "Unitless" PSCM1,RBCM
 SG_ AgDataRawSafeCntr : 47|4@0+ (1.0,0.0) [0.0|15.0] "Unitless" PSCM1,RBCM
 SG_ AgDataRawSafeRollRate : 7|16@0- (0.000244140625,0.0) [-6.0|6.0] "rad/s" PSCM1,RBCM
 SG_ AgDataRawSafeRollRateQf : 43|2@0+ (1,0) [0|3] "" PSCM1,RBCM
 SG_ AgDataRawSafeYawRate : 23|16@0- (0.000244140625,0.0) [-6.0|6.0] "rad/s" PSCM1,RBCM
 SG_ AgDataRawSafeYawRateQf : 41|2@0+ (1,0) [0|3] "" PSCM1,RBCM

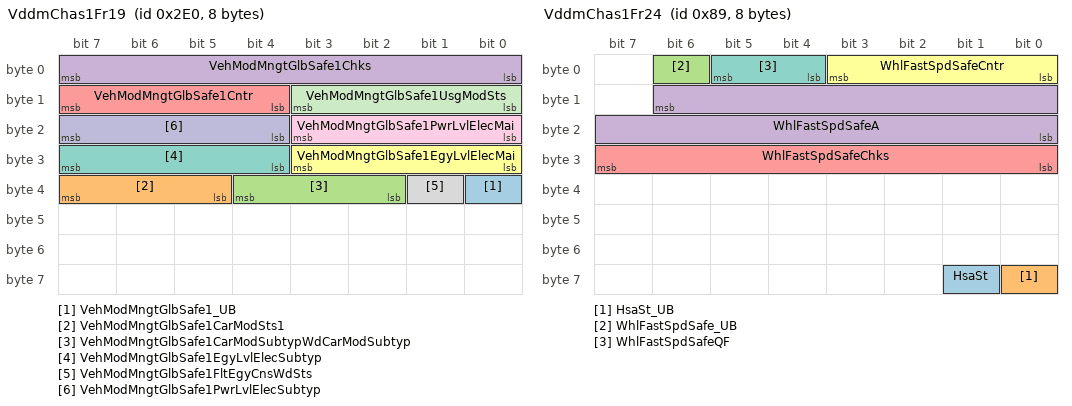
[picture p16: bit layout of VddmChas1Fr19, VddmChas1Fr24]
BO_ 736 VddmChas1Fr19 : 8 VDDM
 SG_ VehModMngtGlbSafe1_UB : 32|1@0+ (1,0) [0|1] "" PSCM1,SAS
 SG_ VehModMngtGlbSafe1CarModSts1 : 39|3@0+ (1,0) [0|7] "" PSCM1,SAS
 SG_ VehModMngtGlbSafe1CarModSubtypWdCarModSubtyp : 36|3@0+ (1.0,0.0) [0.0|7.0] "Unitless" PSCM1,SAS
 SG_ VehModMngtGlbSafe1Chks : 7|8@0+ (1.0,0.0) [0.0|255.0] "Unitless" PSCM1,SAS
 SG_ VehModMngtGlbSafe1Cntr : 15|4@0+ (1.0,0.0) [0.0|15.0] "Unitless" PSCM1,SAS
 SG_ VehModMngtGlbSafe1EgyLvlElecMai : 27|4@0+ (1.0,0.0) [0.0|15.0] "Unitless" PSCM1,SAS
 SG_ VehModMngtGlbSafe1EgyLvlElecSubtyp : 31|4@0+ (1.0,0.0) [0.0|15.0] "Unitless" PSCM1,SAS
 SG_ VehModMngtGlbSafe1FltEgyCnsWdSts : 33|1@0+ (1,0) [0|1] "" PSCM1,SAS
 SG_ VehModMngtGlbSafe1PwrLvlElecMai : 19|4@0+ (1.0,0.0) [0.0|15.0] "Unitless" PSCM1,SAS
 SG_ VehModMngtGlbSafe1PwrLvlElecSubtyp : 23|4@0+ (1.0,0.0) [0.0|15.0] "Unitless" PSCM1,SAS
 SG_ VehModMngtGlbSafe1UsgModSts : 11|4@0+ (1,0) [0|15] "" PSCM1,SAS

BO_ 38 VddmChas1Fr21 : 8 VDDM
 SG_ VFCInfoEna : 62|1@0+ (1,0) [0|1] "" Vector__XXX
 SG_ VFCInfoEna_UB : 61|1@0+ (1,0) [0|1] "" Vector__XXX

BO_ 1123 VddmChas1Fr22 : 8 VDDM
 SG_ SteerSetg_UB : 51|1@0+ (1,0) [0|1] "" PSCM1
 SG_ SteerSetgPen : 59|4@0+ (1,0) [0|15] "" PSCM1
 SG_ SteerSetgSteerAsscLvl : 62|3@0+ (1,0) [0|7] "" PSCM1
 SG_ SteerSetgSteerMod : 50|3@0+ (1,0) [0|7] "" PSCM1

BO_ 784 VddmChas1Fr23 : 8 VDDM
 SG_ CmptmtTFrnt_UB : 23|1@0+ (1,0) [0|1] "" SAS
 SG_ CmptmtTFrntCmptmtTFrnt : 21|11@0+ (0.1,-60.0) [-60.0|125.0] "degC" SAS
 SG_ CmptmtTFrntFanForCmptmtTRunng : 24|1@0+ (1,0) [0|1] "" SAS
 SG_ CmptmtTFrntQf : 26|2@0+ (1,0) [0|3] "" SAS

BO_ 137 VddmChas1Fr24 : 8 BBM
 SG_ HsaSt : 57|1@0+ (1,0) [0|1] "" Vector__XXX
 SG_ HsaSt_UB : 56|1@0+ (1,0) [0|1] "" Vector__XXX
 SG_ WhlFastSpdSafe_UB : 6|1@0+ (1,0) [0|1] "" PSCM1,RBCM
 SG_ WhlFastSpdSafeA : 14|15@0+ (0.00391,0.0) [0.0|125.0027] "m/s" PSCM1,RBCM
 SG_ WhlFastSpdSafeChks : 31|8@0+ (1.0,0.0) [0.0|255.0] "Unitless" PSCM1,RBCM
 SG_ WhlFastSpdSafeCntr : 3|4@0+ (1.0,0.0) [0.0|15.0] "Unitless" PSCM1,RBCM
 SG_ WhlFastSpdSafeQF : 5|2@0+ (1,0) [0|3] "" PSCM1,RBCM

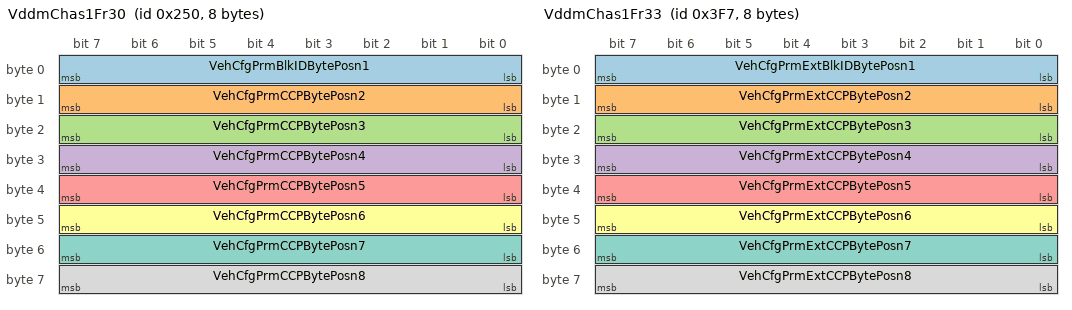
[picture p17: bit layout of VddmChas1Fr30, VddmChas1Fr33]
BO_ 592 VddmChas1Fr30 : 8 VDDM
 SG_ VehCfgPrmBlkIDBytePosn1 : 7|8@0+ (1.0,0.0) [0.0|255.0] "Unitless" PSCM1,RBCM,SAS
 SG_ VehCfgPrmCCPBytePosn2 : 15|8@0+ (1.0,0.0) [0.0|255.0] "Unitless" PSCM1,RBCM,SAS
 SG_ VehCfgPrmCCPBytePosn3 : 23|8@0+ (1.0,0.0) [0.0|255.0] "Unitless" PSCM1,RBCM,SAS
 SG_ VehCfgPrmCCPBytePosn4 : 31|8@0+ (1.0,0.0) [0.0|255.0] "Unitless" PSCM1,RBCM,SAS
 SG_ VehCfgPrmCCPBytePosn5 : 39|8@0+ (1.0,0.0) [0.0|255.0] "Unitless" PSCM1,RBCM,SAS
 SG_ VehCfgPrmCCPBytePosn6 : 47|8@0+ (1.0,0.0) [0.0|255.0] "Unitless" PSCM1,RBCM,SAS
 SG_ VehCfgPrmCCPBytePosn7 : 55|8@0+ (1.0,0.0) [0.0|255.0] "Unitless" PSCM1,RBCM,SAS
 SG_ VehCfgPrmCCPBytePosn8 : 63|8@0+ (1.0,0.0) [0.0|255.0] "Unitless" PSCM1,RBCM,SAS

BO_ 1015 VddmChas1Fr33 : 8 VDDM
 SG_ VehCfgPrmExtBlkIDBytePosn1 : 7|8@0+ (1.0,0.0) [0.0|255.0] "Unitless" PSCM1,RBCM
 SG_ VehCfgPrmExtCCPBytePosn2 : 15|8@0+ (1.0,0.0) [0.0|255.0] "Unitless" PSCM1,RBCM
 SG_ VehCfgPrmExtCCPBytePosn3 : 23|8@0+ (1.0,0.0) [0.0|255.0] "Unitless" PSCM1,RBCM
 SG_ VehCfgPrmExtCCPBytePosn4 : 31|8@0+ (1.0,0.0) [0.0|255.0] "Unitless" PSCM1,RBCM
 SG_ VehCfgPrmExtCCPBytePosn5 : 39|8@0+ (1.0,0.0) [0.0|255.0] "Unitless" PSCM1,RBCM
 SG_ VehCfgPrmExtCCPBytePosn6 : 47|8@0+ (1.0,0.0) [0.0|255.0] "Unitless" PSCM1,RBCM
 SG_ VehCfgPrmExtCCPBytePosn7 : 55|8@0+ (1.0,0.0) [0.0|255.0] "Unitless" PSCM1,RBCM
 SG_ VehCfgPrmExtCCPBytePosn8 : 63|8@0+ (1.0,0.0) [0.0|255.0] "Unitless" PSCM1,RBCM

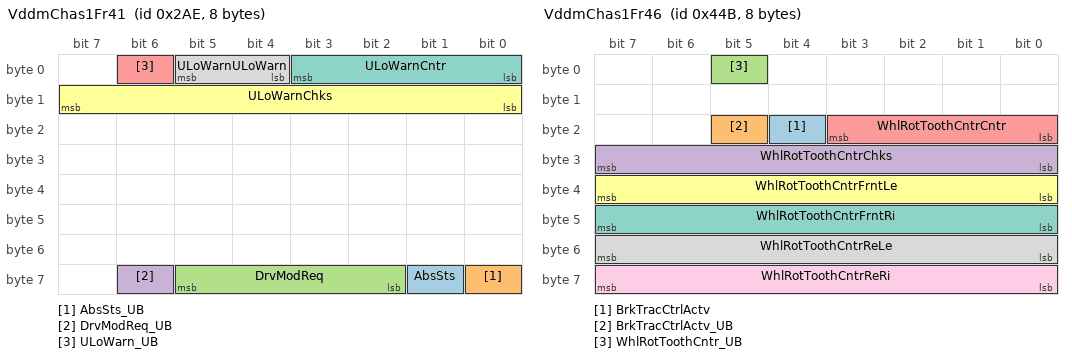
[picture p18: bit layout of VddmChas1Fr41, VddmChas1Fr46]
BO_ 686 VddmChas1Fr41 : 8 BBM
 SG_ AbsSts : 57|1@0+ (1,0) [0|1] "" Vector__XXX
 SG_ AbsSts_UB : 56|1@0+ (1,0) [0|1] "" Vector__XXX
 SG_ DrvModReq : 61|4@0+ (1,0) [0|15] "" PSCM1
 SG_ DrvModReq_UB : 62|1@0+ (1,0) [0|1] "" PSCM1
 SG_ ULoWarn_UB : 6|1@0+ (1,0) [0|1] "" PSCM1
 SG_ ULoWarnChks : 15|8@0+ (1.0,0.0) [0.0|255.0] "Unitless" PSCM1
 SG_ ULoWarnCntr : 3|4@0+ (1.0,0.0) [0.0|15.0] "Unitless" PSCM1
 SG_ ULoWarnULoWarn : 5|2@0+ (1,0) [0|3] "" PSCM1

BO_ 1267 VddmChas1Fr44 : 8 BBM
 SG_ EscSt_UB : 39|1@0+ (1,0) [0|1] "" PSCM1
 SG_ EscStChks : 47|8@0+ (1.0,0.0) [0.0|255.0] "Unitless" PSCM1
 SG_ EscStCntr : 35|4@0+ (1.0,0.0) [0.0|15.0] "Unitless" PSCM1
 SG_ EscStEscSt : 38|3@0+ (1,0) [0|7] "" PSCM1

BO_ 1099 VddmChas1Fr46 : 8 BBM
 SG_ BrkTracCtrlActv : 20|1@0+ (1,0) [0|1] "" PSCM1
 SG_ BrkTracCtrlActv_UB : 21|1@0+ (1,0) [0|1] "" PSCM1
 SG_ WhlRotToothCntr_UB : 5|1@0+ (1,0) [0|1] "" PSCM1
 SG_ WhlRotToothCntrChks : 31|8@0+ (1.0,0.0) [0.0|255.0] "Unitless" PSCM1
 SG_ WhlRotToothCntrCntr : 19|4@0+ (1.0,0.0) [0.0|15.0] "Unitless" PSCM1
 SG_ WhlRotToothCntrFrntLe : 39|8@0+ (1.0,0.0) [0.0|255.0] "Unitless" PSCM1
 SG_ WhlRotToothCntrFrntRi : 47|8@0+ (1.0,0.0) [0.0|255.0] "Unitless" PSCM1
 SG_ WhlRotToothCntrReLe : 55|8@0+ (1.0,0.0) [0.0|255.0] "Unitless" PSCM1
 SG_ WhlRotToothCntrReRi : 63|8@0+ (1.0,0.0) [0.0|255.0] "Unitless" PSCM1

BO_ 26 VddmChas1Fr47 : 8 VDDM
 SG_ AgDataCmpQuality_UB : 43|1@0+ (1,0) [0|1] "" PSCM1
 SG_ AgDataCmpQualityPitchRateCmpQuality : 7|8@0+ (1.0,0.0) [0.0|255.0] "Unitless" PSCM1
 SG_ AgDataCmpQualityRollRateCmpQuality : 15|8@0+ (1.0,0.0) [0.0|255.0] "Unitless" PSCM1
 SG_ AgDataCmpQualityYawRateCmpQuality : 23|8@0+ (1.0,0.0) [0.0|255.0] "Unitless" PSCM1

BO_ 1159 VddmChas1Fr48 : 8 BBM
 SG_ VehMtnSt_UB : 7|1@0+ (1,0) [0|1] "" PSCM1
 SG_ VehMtnStChks : 15|8@0+ (1.0,0.0) [0.0|255.0] "Unitless" PSCM1
 SG_ VehMtnStCntr : 6|4@0+ (1.0,0.0) [0.0|15.0] "Unitless" PSCM1
 SG_ VehMtnStVehMtnSt : 2|3@0+ (1,0) [0|7] "" PSCM1

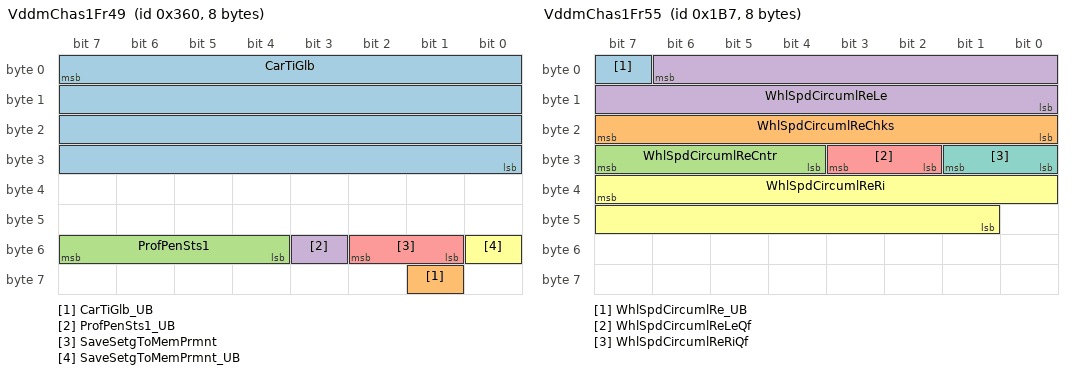
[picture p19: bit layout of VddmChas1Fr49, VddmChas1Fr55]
BO_ 864 VddmChas1Fr49 : 8 VDDM
 SG_ CarTiGlb : 7|32@0+ (0.1,0.0) [0.0|429496729.5] "s" PSCM1,SAS
 SG_ CarTiGlb_UB : 57|1@0+ (1,0) [0|1] "" PSCM1,SAS
 SG_ ProfPenSts1 : 55|4@0+ (1,0) [0|15] "" PSCM1
 SG_ ProfPenSts1_UB : 51|1@0+ (1,0) [0|1] "" PSCM1
 SG_ SaveSetgToMemPrmnt : 50|2@0+ (1,0) [0|3] "" PSCM1
 SG_ SaveSetgToMemPrmnt_UB : 48|1@0+ (1,0) [0|1] "" PSCM1

BO_ 896 VddmChas1Fr50 : 8 VDDM
 SG_ VehBattU_UB : 54|1@0+ (1,0) [0|1] "" PSCM1,SAS
 SG_ VehBattUSysU : 63|8@0+ (0.1,0.0) [0.0|25.0] "Volt" PSCM1,SAS
 SG_ VehBattUSysUQf : 49|2@0+ (1,0) [0|3] "" PSCM1,SAS

BO_ 496 VddmChas1Fr53 : 8 VDDM
 SG_ BkpOfDstTrvld : 7|21@0+ (1.0,0.0) [0.0|2000000.0] "km" PSCM1,SAS
 SG_ BkpOfDstTrvld_UB : 53|1@0+ (1,0) [0|1] "" PSCM1,SAS
 SG_ DrvModReqForChampnMod : 18|3@0+ (1,0) [0|7] "" PSCM1
 SG_ DrvModReqForChampnMod_UB : 54|1@0+ (1,0) [0|1] "" PSCM1

BO_ 580 VddmChas1Fr54 : 8 VDDM
 SG_ IDcDcActLoSide_UB : 4|1@0+ (1,0) [0|1] "" PSCM1
 SG_ IDcDcActLoSideChks : 15|8@0+ (1.0,0.0) [0.0|255.0] "Unitless" PSCM1
 SG_ IDcDcActLoSideCntr : 3|4@0+ (1.0,0.0) [0.0|15.0] "Unitless" PSCM1
 SG_ IDcDcActLoSideIDcDcActLoSide : 23|12@0+ (0.1,0.0) [0.0|409.5] "A" PSCM1

BO_ 439 VddmChas1Fr55 : 8 BBM
 SG_ WhlSpdCircumlRe_UB : 7|1@0+ (1,0) [0|1] "" PSCM1
 SG_ WhlSpdCircumlReChks : 23|8@0+ (1.0,0.0) [0.0|255.0] "Unitless" PSCM1
 SG_ WhlSpdCircumlReCntr : 31|4@0+ (1.0,0.0) [0.0|15.0] "Unitless" PSCM1
 SG_ WhlSpdCircumlReLe : 6|15@0+ (0.00391,0.0) [0.0|125.0027] "m/s" PSCM1
 SG_ WhlSpdCircumlReLeQf : 27|2@0+ (1,0) [0|3] "" PSCM1
 SG_ WhlSpdCircumlReRi : 39|15@0+ (0.00391,0.0) [0.0|125.0027] "m/s" PSCM1
 SG_ WhlSpdCircumlReRiQf : 25|2@0+ (1,0) [0|3] "" PSCM1

BO_ 1313 VddmChas1NMFr : 8 VDDM
 SG_ PNC16_VDDM : 16|1@0+ (1,0) [0|0] "" Vector__XXX
 SG_ PNC17_VDDM : 17|1@0+ (1,0) [0|0] "" Vector__XXX
 SG_ PNC18_VDDM : 18|1@0+ (1,0) [0|0] "" Vector__XXX
 SG_ PNC19_VDDM : 19|1@0+ (1,0) [0|0] "" Vector__XXX
 SG_ PNC20_VDDM : 20|1@0+ (1,0) [0|0] "" Vector__XXX
 SG_ PNC21_VDDM : 21|1@0+ (1,0) [0|0] "" Vector__XXX
 SG_ PNC22_VDDM : 22|1@0+ (1,0) [0|0] "" Vector__XXX
 SG_ PNC23_VDDM : 23|1@0+ (1,0) [0|0] "" Vector__XXX
 SG_ PNC24_VDDM : 24|1@0+ (1,0) [0|0] "" Vector__XXX
 SG_ PNC25_VDDM : 25|1@0+ (1,0) [0|0] "" Vector__XXX
 SG_ PNC26_VDDM : 26|1@0+ (1,0) [0|0] "" Vector__XXX
 SG_ PNC27_VDDM : 27|1@0+ (1,0) [0|0] "" Vector__XXX
 SG_ PNC28_VDDM : 28|1@0+ (1,0) [0|0] "" Vector__XXX
 SG_ PNC29_VDDM : 29|1@0+ (1,0) [0|0] "" Vector__XXX
 SG_ PNC30_VDDM : 30|1@0+ (1,0) [0|0] "" Vector__XXX
 SG_ PNC31_VDDM : 31|1@0+ (1,0) [0|0] "" Vector__XXX
 SG_ PNC32_VDDM : 32|1@0+ (1,0) [0|0] "" Vector__XXX
 SG_ PNC33_VDDM : 33|1@0+ (1,0) [0|0] "" Vector__XXX
 SG_ PNC34_VDDM : 34|1@0+ (1,0) [0|0] "" Vector__XXX
 SG_ PNC35_VDDM : 35|1@0+ (1,0) [0|0] "" Vector__XXX
 SG_ PNC36_VDDM : 36|1@0+ (1,0) [0|0] "" Vector__XXX
 SG_ PNC37_VDDM : 37|1@0+ (1,0) [0|0] "" Vector__XXX
 SG_ PNC38_VDDM : 38|1@0+ (1,0) [0|0] "" Vector__XXX
 SG_ PNC39_VDDM : 39|1@0+ (1,0) [0|0] "" Vector__XXX
 SG_ PNC40_VDDM : 40|1@0+ (1,0) [0|0] "" Vector__XXX
 SG_ PNC41_VDDM : 41|1@0+ (1,0) [0|0] "" Vector__XXX
 SG_ PNC42_VDDM : 42|1@0+ (1,0) [0|0] "" Vector__XXX
 SG_ NM_PNI_VDDM : 14|1@0+ (1,0) [0|0] "" Vector__XXX
 SG_ NM_AW_VDDM : 12|1@0+ (1,0) [0|0] "" Vector__XXX
 SG_ NM_CS_VDDM : 11|1@0+ (1,0) [0|0] "" Vector__XXX
 SG_ NM_RMR_VDDM : 8|1@0+ (1,0) [0|0] "" Vector__XXX
 SG_ NM_NodeID_VDDM : 7|8@0+ (1,0) [0|0] "" Vector__XXX

BO_ 2047 VddmToAllFuncChas1DiagReqFrame : 8 VDDM
 SG_ VddmToAllFuncChas1DiagReqNpdu : 7|64@0+ (1,0) [0|0] "" PSCM1, PSCM2, RBCM, SAS

BO_ 1908 VddmToPscm100FITbChas1DiagReqFrame : 8 VDDM
 SG_ VddmToPscm100FITbChas1DiagReqNpdu : 7|64@0+ (1,0) [0|0] "" Vector__XXX

BO_ 1910 VddmToPscm2cChas1DiagReqFrame : 8 VDDM
 SG_ VddmToPscm2cChas1DiagReqNpdu : 7|64@0+ (1,0) [0|0] "" PSCM2

BO_ 1904 VddmToPscmChas1DiagReqFrame : 8 VDDM
 SG_ VddmToPscmChas1DiagReqNpdu : 7|64@0+ (1,0) [0|0] "" PSCM1

BO_ 1909 VddmToRbcmChas1DiagReqFrame : 8 VDDM
 SG_ VddmToRbcmChas1DiagReqNpdu : 7|64@0+ (1,0) [0|0] "" RBCM

BO_ 1906 VddmToSasChas1DiagReqFrame : 8 VDDM
 SG_ VddmToSasChas1DiagReqNpdu : 7|64@0+ (1,0) [0|0] "" SAS

// Node Comments
CM_ BU_ ETC "External Tester Connector";
CM_ BU_ SAS "Steering Angle Sensor";

// Signal Comments
CM_ SG_ 147 AsyADL3FuncCtrlStsADMod "ADMod";
CM_ SG_ 147 AsyADL3FuncCtrlStsChks "Checksum";
CM_ SG_ 147 AsyADL3FuncCtrlStsCntr "Counter";
CM_ SG_ 147 AsyADL3FuncCtrlStsCtrlSts "CtrlSts";
CM_ SG_ 147 AsyADL3FuncCtrlStsDegraded "Degraded";
CM_ SG_ 147 AsyADL3FuncCtrlStsQf "Qf";
CM_ SG_ 147 AsyADL3FuncCtrlStsSts "Status";
CM_ SG_ 147 AsyADModeReqADActiveReq "ADActiveRequest";
CM_ SG_ 147 AsyADModeReqADDeactiveReq "AD Deactive Request";
CM_ SG_ 147 AsyADModeReqChks "Checksum";
CM_ SG_ 147 AsyADModeReqCntr "Counter";
CM_ SG_ 147 PASFuncActive "Parking function.";
CM_ SG_ 147 RctaBrkReqQM "Indicating RCTA braking is committed.
This signal complies with QM.";
CM_ SG_ 147 RcwmBrkReqQM "Indicating RCW braking request is committed. This signal complies with QM.";
CM_ SG_ 51 AgCtrlTqLowrLim "Lower limit for angle controller torque request.";
CM_ SG_ 51 AgCtrlTqUpprLim "Upper limit for angle controller torque request.";
CM_ SG_ 51 AsyPinionAgReqSafeAsyPinionAgReq "Steering request signal from Active Safety with end-to-end protection ";
CM_ SG_ 51 AsyPinionAgReqSafeAsyPinionAgReqChks "CRC";
CM_ SG_ 51 AsyPinionAgReqSafeAsyPinionAgReqCntr "Counter";
CM_ SG_ 308 BrkWssInfoFrntChks "checksum
";
CM_ SG_ 308 BrkWssInfoFrntCntr "counter";
CM_ SG_ 308 BrkWssInfoFrntTTCFactorFL "Correction factor needed by BBM to calculate Vehicle speed. If VDDM lost, then BBM use the latest value";
CM_ SG_ 308 BrkWssInfoFrntTTCFactorFR "Correction factor needed by BBM to calculate Vehicle speed. If VDDM lost, then BBM use the latest value";
CM_ SG_ 308 BrkWssInfoFrntWssCoreMonRob "wss core monitor";
CM_ SG_ 327 BrkWssInfoReChks "checksum
";
CM_ SG_ 327 BrkWssInfoReCntr "counter";
CM_ SG_ 327 BrkWssInfoReTTCFactorRL "Correction factor needed by BBM to calculate Vehicle speed. If VDDM lost, then BBM use the latest value";
CM_ SG_ 327 BrkWssInfoReTTCFactorRR "Correction factor needed by BBM to calculate Vehicle speed. If VDDM lost, then BBM use the latest value";
CM_ SG_ 327 EpbStsChks "Electrical Park Brake system status information Status for the rear wheel park actuator";
CM_ SG_ 327 EpbStsCntr "Electrical Park Brake system status information Counter for EPB status";
CM_ SG_ 327 EpbStsEpbSts "Electrical Park Brake system status information Status for the rear wheel park actuator";
CM_ SG_ 84 SBMHealthChkCmd "These signals are for BCM  and RBCM handshake during SelfTest, to check RBCM pressure build and valve status on lifecycle.";
CM_ SG_ 84 SteerReCtrlReqAgReq "Steering angle request";
CM_ SG_ 84 SteerReCtrlReqAqRecQf "Steering angle request Qf";
CM_ SG_ 84 SteerReCtrlReqChks "Checksum";
CM_ SG_ 84 SteerReCtrlReqCntr "Rolling counter";
CM_ SG_ 84 SteerReCtrlReqSteerReCtrlSts "Control bits for angle request, corporate with steer angle request and Qf to realize rear axle angle control";
CM_ SG_ 129 BrkFActAutParkBrkSpprtReq "AutParkBrkSpprtReq";
CM_ SG_ 129 BrkFActChks "checksum";
CM_ SG_ 129 BrkFActCntr "counter";
CM_ SG_ 129 BrkFActForce "Brake force in Newtons";
CM_ SG_ 129 RbuCtrlModReqSafeBrkSysModCfmd "Mode confirmation";
CM_ SG_ 129 RbuCtrlModReqSafeChks "checksum";
CM_ SG_ 129 RbuCtrlModReqSafeCntr "counter";
CM_ SG_ 265 EpbAvlPrimApplyFunctionalitiesAvailable "apply func available";
CM_ SG_ 265 EpbAvlPrimChks "Checksum";
CM_ SG_ 265 EpbAvlPrimCntr "Counter";
CM_ SG_ 265 EpbAvlPrimDriveAwayIntention "DAR";
CM_ SG_ 265 EpbAvlPrimHostAvailabilityFull "Host availabiltiy full";
CM_ SG_ 265 EpbAvlPrimHostAvailabilityRelOnly "Host availablity relay only";
CM_ SG_ 265 EpbAvlPrimPrimarySystemAvailable "Primary system available ";
CM_ SG_ 265 EpbAvlPrimReserved1 "reserved";
CM_ SG_ 265 EpbAvlPrimReserved2 "reserved";
CM_ SG_ 265 EpbAvlPrimReserved3 "reserved";
CM_ SG_ 265 EpbAvlPrimReserved4 "reserved";
CM_ SG_ 265 EpbAvlPrimRollerTestBench "Rollerbench";
CM_ SG_ 265 PrimBrkSysStBrkSysSt "brake system state";
CM_ SG_ 265 PrimBrkSysStChks "checksum";
CM_ SG_ 265 PrimBrkSysStCntr "counter";
CM_ SG_ 185 ALgtStdFromWhlSpdALgtStdFromWhlSpd "Longitudinal acceleration over ground.
end2endprotection=profile1A dataid= 12345 Longitudinal acceleration over ground";
CM_ SG_ 185 ALgtStdFromWhlSpdChks "Longitudinal acceleration over ground.
end2endprotection=profile1A dataid=12345 Checksum for longitudinal acceleration over ground";
CM_ SG_ 185 ALgtStdFromWhlSpdCntr "Longitudinal acceleration over ground.
end2endprotection=profile1A dataid=12345 Counter for longitudinal acceleration over ground";
CM_ SG_ 185 ALgtStdFromWhlSpdQf "Longitudinal acceleration over ground.
end2endprotection=profile1A dataid=12345 Qf for longitudinal acceleration over ground";
CM_ SG_ 185 SlipRatWithinRngForReWhls "The boolean flag of both rear wheels' slip ratio beyond the calibrated threshold";
CM_ SG_ 134 DrvgCyc " Transition from 0 to 1 indicates a start of a new Driving Cycle.";
CM_ SG_ 544 AccrPedlRatAccrPedlRat "Accelerator Pedal Position with adapted 0 point. Value as percentage of fully pressed pedal";
CM_ SG_ 544 AccrPedlRatChks "Accelerator Pedal Position with adapted 0 point. Value as percentage of fully pressed pedal. Checksum";
CM_ SG_ 544 AccrPedlRatCntr "Accelerator Pedal Position with adapted 0 point. Value as percentage of fully pressed pedal. Counter";
CM_ SG_ 1111 PtTqAtWhlFrntActChks "checksum";
CM_ SG_ 1111 PtTqAtWhlFrntActCntr "counter";
CM_ SG_ 1111 PtTqAtWhlFrntActPtTqAtAxleFrntAct "Actual torque delivered by the powertrain to the front axle";
CM_ SG_ 1111 PtTqAtWhlFrntActPtTqAtWhlFrntLeAct "Actual torque delivered by the powertrain to the front left wheel.";
CM_ SG_ 1111 PtTqAtWhlFrntActPtTqAtWhlFrntRiAct "Actual torque delivered by the powertrain to the front right wheel.";
CM_ SG_ 1111 PtTqAtWhlFrntActPtTqAtWhlsFrntQly "quality factor";
CM_ SG_ 131 EngSt1WdStsChks "checksum";
CM_ SG_ 131 EngSt1WdStsCntr "counter";
CM_ SG_ 131 EngSt1WdStsEngSt1WdSts "Signaling the state of the powerpack";
CM_ SG_ 752 DrvrGearLvrInfoIndcn "Indicates to the driver why the gear lever information is change.";
CM_ SG_ 752 EngSt1WdSts1 "Signaling the state of the powerpack(without E2E)";
CM_ SG_ 121 EngPAmbAir "Ambient pressure";
CM_ SG_ 1431 PSCMdevelpsignalgroupreq1Functiondevpsignalgroup1 "develop signal group request";
CM_ SG_ 1431 PSCMdevelpsignalgroupreq1Functiondevpsignalgroup2 "develop signal group request";
CM_ SG_ 1431 PSCMdevelpsignalgroupreq1Functiondevpsignalgroup3 "develop signal group request";
CM_ SG_ 1431 PSCMdevelpsignalgroupreq1Functiondevpsignalgroup4 "develop signal group request";
CM_ SG_ 1431 PSCMdevelpsignalgroupreq1Functiondevpsignalgroup5 "develop signal group request";
CM_ SG_ 1431 PSCMdevelpsignalgroupreq1Functiondevpsignalgroup6 "develop signal group request";
CM_ SG_ 1431 PSCMdevelpsignalgroupreq1Functiondevpsignalgroup7 "develop signal group request";
CM_ SG_ 1431 PSCMdevelpsignalgroupreq1Functiondevpsignalgroup8 "develop signal group request";
CM_ SG_ 1504 RBCMdevelpsignalgroupreq1Functiondevpsignalgroup1 "RBCM development signal";
CM_ SG_ 1504 RBCMdevelpsignalgroupreq1Functiondevpsignalgroup2 "RBCM development signal";
CM_ SG_ 1504 RBCMdevelpsignalgroupreq1Functiondevpsignalgroup3 "RBCM development signal";
CM_ SG_ 1504 RBCMdevelpsignalgroupreq1Functiondevpsignalgroup4 "RBCM development signal";
CM_ SG_ 1504 RBCMdevelpsignalgroupreq1Functiondevpsignalgroup5 "RBCM development signal";
CM_ SG_ 1504 RBCMdevelpsignalgroupreq1Functiondevpsignalgroup6 "RBCM development signal";
CM_ SG_ 1504 RBCMdevelpsignalgroupreq1Functiondevpsignalgroup7 "RBCM development signal";
CM_ SG_ 1504 RBCMdevelpsignalgroupreq1Functiondevpsignalgroup8 "RBCM development signal";
CM_ SG_ 1432 VDDMdevelpsignalgroupreq1Functiondevpsignalgroup1 "develop signal group request";
CM_ SG_ 1432 VDDMdevelpsignalgroupreq1Functiondevpsignalgroup2 "develop signal group request";
CM_ SG_ 1432 VDDMdevelpsignalgroupreq1Functiondevpsignalgroup3 "develop signal group request";
CM_ SG_ 1432 VDDMdevelpsignalgroupreq1Functiondevpsignalgroup4 "develop signal group request";
CM_ SG_ 1432 VDDMdevelpsignalgroupreq1Functiondevpsignalgroup5 "develop signal group request";
CM_ SG_ 1432 VDDMdevelpsignalgroupreq1Functiondevpsignalgroup6 "develop signal group request";
CM_ SG_ 1432 VDDMdevelpsignalgroupreq1Functiondevpsignalgroup7 "develop signal group request";
CM_ SG_ 1432 VDDMdevelpsignalgroupreq1Functiondevpsignalgroup8 "develop signal group request";
CM_ SG_ 1433 VDDMdevelpsignalgroupreq2Functiondevpsignalgroup1 "VDDM development signal";
CM_ SG_ 1433 VDDMdevelpsignalgroupreq2Functiondevpsignalgroup2 "VDDM development signal";
CM_ SG_ 1433 VDDMdevelpsignalgroupreq2Functiondevpsignalgroup3 "VDDM development signal";
CM_ SG_ 1433 VDDMdevelpsignalgroupreq2Functiondevpsignalgroup4 "VDDM development signal";
CM_ SG_ 1433 VDDMdevelpsignalgroupreq2Functiondevpsignalgroup5 "VDDM development signal";
CM_ SG_ 1433 VDDMdevelpsignalgroupreq2Functiondevpsignalgroup6 "VDDM development signal";
CM_ SG_ 1433 VDDMdevelpsignalgroupreq2Functiondevpsignalgroup7 "VDDM development signal";
CM_ SG_ 1433 VDDMdevelpsignalgroupreq2Functiondevpsignalgroup8 "VDDM development signal";
CM_ SG_ 235 PrkgPinionAgReqGroupParkAssiPinionAgReq "The requested steering pinion angle by the autonomous parking system.";
CM_ SG_ 235 PrkgPinionAgReqGroupParkAssiPinionAgReqChks "counter,For E2E Protection";
CM_ SG_ 235 PrkgPinionAgReqGroupParkAssiPinionAgReqCntr "CRC,to check the signal,For E2E Protection";
CM_ SG_ 235 PrkgPinionAgReqGroupQF "QF";
CM_ SG_ 235 UturnTrqRelsChks "Checksum";
CM_ SG_ 235 UturnTrqRelsCntr "Counter";
CM_ SG_ 235 UturnTrqRelsUturnTrqRels "Describes whether the current lateral control request is in U-turn mode.";
CM_ SG_ 149 PrkgGearReqGroupChks "counter";
CM_ SG_ 149 PrkgGearReqGroupCntr "checksum";
CM_ SG_ 149 PrkgGearReqGroupReqSts1 "After selecting the RPA and before the handshake is successful, the PAS requests to suspend the P file to pull up the EPB";
CM_ SG_ 246 ADL3LatCtrlStsADMod "Steering system AD mode status";
CM_ SG_ 246 ADL3LatCtrlStsChks "Counter of the signal group";
CM_ SG_ 246 ADL3LatCtrlStsCntr "Counter of the signal group";
CM_ SG_ 246 ADL3LatCtrlStsCtrlSts "Inform to AD systems which Channel (Primary/Secondary) signals is being used";
CM_ SG_ 246 ADL3LatCtrlStsDegraded "degraded";
CM_ SG_ 246 ADL3LatCtrlStsQf "quality factor";
CM_ SG_ 246 ADL3LatCtrlStsSts "- Green (2)- Full TJP function, neither input signal nor ECU internal error - Yellow (1)- TJP function but with minor error-  Red (0) - One or more Channel (Primary /Secondary) cant implement TJP for internal ECU or input signal error";
CM_ SG_ 246 DrvrSteerActvChks "Confirmation of driver steer actively Checksum";
CM_ SG_ 246 DrvrSteerActvCntr "Confirmation of driver steer actively Counter";
CM_ SG_ 246 DrvrSteerActvDrvrSteerActv "Indicates if the driver steers actively";
CM_ SG_ 246 FrntSteerFEstimd1 "FrntSteerFEstimd1 (Front Steer Force Estimated) provides estimates of the front steering rack force.";
CM_ SG_ 246 UBoostReqBySteerFrnt "UBoosReqBySteerFrnt is sent to the Electrical Management subsystem to request that sufficient electrical power is prodived for the steering system during special driving situations, e.g. parking manouvers.";
CM_ SG_ 70 LatCtrlModCfmdChks "Confirmation of lateral control request Confirmed lateral mode";
CM_ SG_ 70 LatCtrlModCfmdCntr "Confirmation of lateral control request Confirmed lateral mode";
CM_ SG_ 70 LatCtrlModCfmdLatCtrlMod "Confirmation of lateral control request Confirmed lateral mode";
CM_ SG_ 70 SteerServoSts "Status of lateral control request";
CM_ SG_ 70 SteerSftyLimrSts "Indicates the status of the PSCM's safety limiter for external functions.";
CM_ SG_ 70 SteerWhlTqAddl "Overlay torque from external requests";
CM_ SG_ 70 TqAssAddl "Total torque at motor";
CM_ SG_ 444 DrvrSteerWhlHldGroupDrvrSteerWhlHld "Hands on steering wheel information. Signal indicating whether the driver has his hands on the steering wheel or not.";
CM_ SG_ 444 DrvrSteerWhlHldGroupDrvrSteerWhlHldQly "Hands on steering wheel information. Confidence value for the DrvrSteerWhlHld estimation calculation, specifically indicating the confidence for the hands off state.";
CM_ SG_ 444 SteerErrReq "Sent from steering system to display to notify driver if no steering torque assist is available. Messages sent from Steering system to DIM";
CM_ SG_ 444 SteerExtFctStsChks "Confirmation of steer external function status Checksum";
CM_ SG_ 444 SteerExtFctStsCntr "Confirmation of steer external function status Counter";
CM_ SG_ 444 SteerExtFctStsDrvrSteerOvrd "Steering request of asking driver to take over";
CM_ SG_ 444 SteerExtFctStsExtFctLowerLimActive "Column  Torque Lower Limit ";
CM_ SG_ 444 SteerExtFctStsExtFctRateLimActive "External function rate Limit ";
CM_ SG_ 444 SteerExtFctStsExtFctUpperLimActive "Column Torque Upper Limit ";
CM_ SG_ 444 SteerExtFctStsExtSafeLimActive "External function torque output vs defined safety limiters ";
CM_ SG_ 444 SteerExtFctStsLatAgReqNotInRange "Pinion angle /current trajectory between primary and fall back ";
CM_ SG_ 444 SteerExtFctStsLatCtrlReqNotInRange "Lateral Ctrl request and primary and fall back ";
CM_ SG_ 444 SteerStsToParkAssi "SteerStsToParkAssi contains PSCM status related to execution of SAP.";
CM_ SG_ 955 PinionSteerAgMax1 "PinionSteerAgMax1 contains the current maximal pinion angle. Depends on tire size and vehicle type.";
CM_ SG_ 78 PinionSteerAgGroupChks "Checksum for PinionSteerAgGroup";
CM_ SG_ 78 PinionSteerAgGroupCntr "Counter for PinionSteerAgGroup";
CM_ SG_ 78 PinionSteerAgGroupPinionSteerAg1 "Calculated pinion steer angle at the front steering device";
CM_ SG_ 78 PinionSteerAgGroupPinionSteerAg1Qf "Quality factor for PinionSteerAg1";
CM_ SG_ 78 PinionSteerAgGroupPinionSteerAgSpd1 "Calculated pinion steer angle speed at the front steering device ";
CM_ SG_ 78 PinionSteerAgGroupPinionSteerAgSpd1Qf "Quality factor for PinionSteerAgSpd1";
CM_ SG_ 78 PinionSteerAgGroupSteerWhlTq "Torque on steering wheel";
CM_ SG_ 78 PinionSteerAgGroupSteerWhlTqQf "Quality factor for SteerWhlTq";
CM_ SG_ 1430 PSCMdevelpsignalgroupresp1Functiondevpsignalgroup1 "PSCM development signal";
CM_ SG_ 1430 PSCMdevelpsignalgroupresp1Functiondevpsignalgroup2 "PSCM development signal";
CM_ SG_ 1430 PSCMdevelpsignalgroupresp1Functiondevpsignalgroup3 "PSCM development signal";
CM_ SG_ 1430 PSCMdevelpsignalgroupresp1Functiondevpsignalgroup4 "PSCM development signal";
CM_ SG_ 1430 PSCMdevelpsignalgroupresp1Functiondevpsignalgroup5 "PSCM development signal";
CM_ SG_ 1430 PSCMdevelpsignalgroupresp1Functiondevpsignalgroup6 "PSCM development signal";
CM_ SG_ 1430 PSCMdevelpsignalgroupresp1Functiondevpsignalgroup7 "PSCM development signal";
CM_ SG_ 1430 PSCMdevelpsignalgroupresp1Functiondevpsignalgroup8 "PSCM development signal";
CM_ SG_ 66 AsySftyHWLReqBkp "Request to turn on/off the Hazard Warning Light For FLC2 SSM.";
CM_ SG_ 66 BrkBstStsSec "0: RHB_NotAvailable
1: RHB_Available
2: Reserved
3: Reserved";
CM_ SG_ 66 EBDiagActive "0: diagnosis is inactive
1: diagnosis is active";
CM_ SG_ 66 SBMHealthChkResp "These signals are for BCM  and RBCM handshake during SelfTest, to check RBCM pressure build and valve status on lifecycle.";
CM_ SG_ 66 TakeoverWarnForBackupChks "E2E Protect";
CM_ SG_ 66 TakeoverWarnForBackupCntr "E2E Protect";
CM_ SG_ 66 TakeoverWarnForBackupTakeoverWarnForBackup "Take over message sent to driver when FLC2 is working as back up replacement for ASDM.";
CM_ SG_ 289 AD4IMUStatChks "checksum";
CM_ SG_ 289 AD4IMUStatCntr "count";
CM_ SG_ 289 AD4IMUStatHead "Simultaneous number identification ";
CM_ SG_ 289 AD4IMUStatIMUStat "IMU(vehicle)  status";
CM_ SG_ 289 AD4IMUStatIMUTemp "IMU temperature";
CM_ SG_ 289 SecBrkSysStBrkSysSt "brake system state";
CM_ SG_ 289 SecBrkSysStChks "checksum";
CM_ SG_ 289 SecBrkSysStCntr "counter";
CM_ SG_ 545 BrkLiOnReqForBkpBrkLiOnReqChks "Checksum";
CM_ SG_ 545 BrkLiOnReqForBkpBrkLiOnReqCntr "Counter";
CM_ SG_ 545 BrkLiOnReqForBkpBrkLiOnReqSts "Status";
CM_ SG_ 545 VehSpdLgtForBkpVehSpdLgtA "vehicle speed for backup";
CM_ SG_ 545 VehSpdLgtForBkpVehSpdLgtChks "checksum";
CM_ SG_ 545 VehSpdLgtForBkpVehSpdLgtCntr "counter";
CM_ SG_ 545 VehSpdLgtForBkpVehSpdLgtQf "vehicle speed quality factor for backup";
CM_ SG_ 562 WhlSpdCircumlFrntForBkpWhlSpdCircumlFrntChks "Individual wheel speed from front wheel speed sensors. Checksum";
CM_ SG_ 562 WhlSpdCircumlFrntForBkpWhlSpdCircumlFrntCntr "Individual wheel speed from front wheel speed sensors. Counter";
CM_ SG_ 562 WhlSpdCircumlFrntForBkpWhlSpdCircumlFrntLe "Individual wheel speed from front wheel speed sensors. Wheel speed from front left wheel speed sensor using nominal value of wheel radius.";
CM_ SG_ 562 WhlSpdCircumlFrntForBkpWhlSpdCircumlFrntLeQf "Individual wheel speed from front wheel speed sensors. Qf for wheel speed sensor";
CM_ SG_ 562 WhlSpdCircumlFrntForBkpWhlSpdCircumlFrntRiQf "Individual wheel speed from front wheel speed sensors. Qf for wheel speed sensor";
CM_ SG_ 562 WhlSpdCircumlFrntForBkpWhlSpdCircumlFrntWhlSpdCircumlFrntRi "Individual wheel speed from front wheel speed sensors. Wheel speed from front right wheel speed sensor using nominal value of wheel radius
";
CM_ SG_ 569 WhlSpdCircumlReForBkpWhlSpdCircumlReChks "Individual wheel speed from rear wheel speed sensors. Checksum";
CM_ SG_ 569 WhlSpdCircumlReForBkpWhlSpdCircumlReCntr "Individual wheel speed from rear wheel speed sensors. Counter";
CM_ SG_ 569 WhlSpdCircumlReForBkpWhlSpdCircumlReLe "Individual wheel speed from rear wheel speed sensors. Wheel speed from rear left wheel speed sensor using nominal value of wheel radius.";
CM_ SG_ 569 WhlSpdCircumlReForBkpWhlSpdCircumlReLeQf "Individual wheel speed from rear wheel speed sensors. Qf for wheel speed sensor";
CM_ SG_ 569 WhlSpdCircumlReForBkpWhlSpdCircumlReRi "Individual wheel speed from rear wheel speed sensors. Wheel speed from rear right wheel speed sensor using nominal value of wheel radius.";
CM_ SG_ 569 WhlSpdCircumlReForBkpWhlSpdCircumlReRiQf "Individual wheel speed from rear wheel speed sensors. Qf for wheel speed sensor";
CM_ SG_ 593 WhlRotToothCntrForBkpChks "check sum";
CM_ SG_ 593 WhlRotToothCntrForBkpCntr "counter";
CM_ SG_ 593 WhlRotToothCntrForBkpWhlRotToothCntrFrntLe "Wheel rotation ticks for each individual wheel. Wheel rotation impuls counter front left. For one complete wheel revolution the counter will increase by 96 (with 48 magnetic pole-pairs).";
CM_ SG_ 593 WhlRotToothCntrForBkpWhlRotToothCntrFrntRi "Wheel rotation ticks for each individual wheel. Wheel rotation impuls counter front right. For one complete wheel revolution the counter will increase by 96 (with 48 magnetic pole-pairs).";
CM_ SG_ 593 WhlRotToothCntrForBkpWhlRotToothCntrReLe "Wheel rotation ticks for each individual wheel. Wheel rotation impuls counter rear left. For one complete wheel revolution the counter will increase by 96 (with 48 magnetic pole-pairs).";
CM_ SG_ 593 WhlRotToothCntrForBkpWhlRotToothCntrReRi "Wheel rotation ticks for each individual wheel. Wheel rotation impuls counter rear right. For one complete wheel revolution the counter will increase by 96 (with 48 magnetic pole-pairs).";
CM_ SG_ 323 AD4IMUAcceXAcce "IMU(vehicle) acceleration of X";
CM_ SG_ 323 AD4IMUAcceXChks "checksum";
CM_ SG_ 323 AD4IMUAcceXCntr "count";
CM_ SG_ 323 AD4IMUAcceXHead "Simultaneous number identification ";
CM_ SG_ 177 AD4IMUAcceYAcce "IMU(vehicle) acceleration of Y";
CM_ SG_ 177 AD4IMUAcceYChks "checksum";
CM_ SG_ 177 AD4IMUAcceYCntr "count";
CM_ SG_ 177 AD4IMUAcceYHead "Simultaneous number identification ";
CM_ SG_ 181 AD4IMUAcceZAcce "IMU(vehicle) acceleration of Z";
CM_ SG_ 181 AD4IMUAcceZChks "checksum";
CM_ SG_ 181 AD4IMUAcceZCntr "count";
CM_ SG_ 181 AD4IMUAcceZHead "Simultaneous number identification ";
CM_ SG_ 193 AD4IMUGyroXChks "checksum";
CM_ SG_ 193 AD4IMUGyroXCntr "count";
CM_ SG_ 193 AD4IMUGyroXGyro "IMU(vehicle) gyroscope of X";
CM_ SG_ 193 AD4IMUGyroXHead "Simultaneous number identification ";
CM_ SG_ 200 AD4IMUGyroYChks "checksum";
CM_ SG_ 200 AD4IMUGyroYCntr "count";
CM_ SG_ 200 AD4IMUGyroYGyro "IMU(vehicle) gyroscope of Y";
CM_ SG_ 200 AD4IMUGyroYHead "Simultaneous number identification ";
CM_ SG_ 166 AD4IMUGyroZChks "checksum";
CM_ SG_ 166 AD4IMUGyroZCntr "count";
CM_ SG_ 166 AD4IMUGyroZGyro "IMU(vehicle) gyroscope of Z";
CM_ SG_ 166 AD4IMUGyroZHead "Simultaneous number identification ";
CM_ SG_ 1383 VFCVectorRBCMBlockID "BlockID";
CM_ SG_ 1383 VFCVectorRBCMVFCid0 "SettingsComfort";
CM_ SG_ 1383 VFCVectorRBCMVFCid1 "ParkingDrivingClimatization";
CM_ SG_ 1383 VFCVectorRBCMVFCid10 "ExteriorLighting";
CM_ SG_ 1383 VFCVectorRBCMVFCid11 "VFCid11";
CM_ SG_ 1383 VFCVectorRBCMVFCid12 "Alarm";
CM_ SG_ 1383 VFCVectorRBCMVFCid13 "VFCid13";
CM_ SG_ 1383 VFCVectorRBCMVFCid14 "InteriorLighting";
CM_ SG_ 1383 VFCVectorRBCMVFCid15 "VFCid15";
CM_ SG_ 1383 VFCVectorRBCMVFCid16 "Locking";
CM_ SG_ 1383 VFCVectorRBCMVFCid17 "RemoteKeyFunctionality";
CM_ SG_ 1383 VFCVectorRBCMVFCid18 "PropulsionStart";
CM_ SG_ 1383 VFCVectorRBCMVFCid19 "VFCid19";
CM_ SG_ 1383 VFCVectorRBCMVFCid2 "PostClimatisation";
CM_ SG_ 1383 VFCVectorRBCMVFCid20 "VFCid20";
CM_ SG_ 1383 VFCVectorRBCMVFCid21 "PowerClosures";
CM_ SG_ 1383 VFCVectorRBCMVFCid22 "VehicleDriving";
CM_ SG_ 1383 VFCVectorRBCMVFCid23 "VFCid23";
CM_ SG_ 1383 VFCVectorRBCMVFCid24 "SettingsProfile";
CM_ SG_ 1383 VFCVectorRBCMVFCid25 "SeatComfortFunctions";
CM_ SG_ 1383 VFCVectorRBCMVFCid26 "Brake";
CM_ SG_ 1383 VFCVectorRBCMVFCid27 "InfotainmentPoll";
CM_ SG_ 1383 VFCVectorRBCMVFCid28 "HVEnergyStorage";
CM_ SG_ 1383 VFCVectorRBCMVFCid29 "VFCid29";
CM_ SG_ 1383 VFCVectorRBCMVFCid3 "PowertrainParkingClimatization";
CM_ SG_ 1383 VFCVectorRBCMVFCid30 "TelematicsConnectivity";
CM_ SG_ 1383 VFCVectorRBCMVFCid31 "VFCid31";
CM_ SG_ 1383 VFCVectorRBCMVFCid32 "VFCid32";
CM_ SG_ 1383 VFCVectorRBCMVFCid33 "Diagnostics";
CM_ SG_ 1383 VFCVectorRBCMVFCid34 "VehicleModeManagement";
CM_ SG_ 1383 VFCVectorRBCMVFCid35 "TrailerCaravanFunctions";
CM_ SG_ 1383 VFCVectorRBCMVFCid36 "Immobilizer";
CM_ SG_ 1383 VFCVectorRBCMVFCid37 "Windows";
CM_ SG_ 1383 VFCVectorRBCMVFCid38 "Visibility";
CM_ SG_ 1383 VFCVectorRBCMVFCid39 "VFCid39";
CM_ SG_ 1383 VFCVectorRBCMVFCid4 "VFCid4";
CM_ SG_ 1383 VFCVectorRBCMVFCid40 "VFCid40";
CM_ SG_ 1383 VFCVectorRBCMVFCid41 "InfotainmentPush";
CM_ SG_ 1383 VFCVectorRBCMVFCid42 "ChargingHV";
CM_ SG_ 1383 VFCVectorRBCMVFCid43 "BodyPreClimatisation";
CM_ SG_ 1383 VFCVectorRBCMVFCid44 "Crash";
CM_ SG_ 1383 VFCVectorRBCMVFCid45 "GlobalShortDuration";
CM_ SG_ 1383 VFCVectorRBCMVFCid46 "ExteriorLightsHazard";
CM_ SG_ 1383 VFCVectorRBCMVFCid47 "VFCid47";
CM_ SG_ 1383 VFCVectorRBCMVFCid48 "DoorOpenWarning";
CM_ SG_ 1383 VFCVectorRBCMVFCid49 "ChargingLVInit";
CM_ SG_ 1383 VFCVectorRBCMVFCid5 "VFCid5";
CM_ SG_ 1383 VFCVectorRBCMVFCid50 "VFCid50";
CM_ SG_ 1383 VFCVectorRBCMVFCid51 "VFCid51";
CM_ SG_ 1383 VFCVectorRBCMVFCid52 "HVBatteryThermalEventWarning";
CM_ SG_ 1383 VFCVectorRBCMVFCid53 "VisualAssist";
CM_ SG_ 1383 VFCVectorRBCMVFCid54 "VFCid54";
CM_ SG_ 1383 VFCVectorRBCMVFCid55 "VFCid55";
CM_ SG_ 1383 VFCVectorRBCMVFCid56 "VFCid56";
CM_ SG_ 1383 VFCVectorRBCMVFCid57 "VFCid57";
CM_ SG_ 1383 VFCVectorRBCMVFCid58 "VFCid58";
CM_ SG_ 1383 VFCVectorRBCMVFCid59 "VFCid59";
CM_ SG_ 1383 VFCVectorRBCMVFCid6 "SettingsVehicle";
CM_ SG_ 1383 VFCVectorRBCMVFCid60 "VFCid60";
CM_ SG_ 1383 VFCVectorRBCMVFCid61 "VFCid61";
CM_ SG_ 1383 VFCVectorRBCMVFCid7 "VFCid7";
CM_ SG_ 1383 VFCVectorRBCMVFCid8 "VFCid8";
CM_ SG_ 1383 VFCVectorRBCMVFCid9 "IPWakeup";
CM_ SG_ 64 SteerWhlSnsrAg "Actual steering wheel angle from the actual centre position of the steering wheel. ";
CM_ SG_ 64 SteerWhlSnsrAgSpd "Actual steering wheel angle from the actual centre position of the steering wheel. Steering angle speed with steering wheel rotation direction.  ";
CM_ SG_ 64 SteerWhlSnsrChks "Checksum for steering wheel sensor data.";
CM_ SG_ 64 SteerWhlSnsrCntr "Counter value for steering wheel sensor data.";
CM_ SG_ 64 SteerWhlSnsrQf "Qf for steering wheel sensor information";
CM_ SG_ 54 PrpsnTqReReq "Propulsion wheel torque request at rear wheel axle. This request is arbitrated from driver request and autonomous driving functions (CC, ACC, etc) requests. The torque includes effects from auxiliary loads, transmission, etc.";
CM_ SG_ 274 SecParkBrkSysSt2BrkSysSt "second parking brake system status2";
CM_ SG_ 274 SecParkBrkSysSt2Chks "checksum";
CM_ SG_ 274 SecParkBrkSysSt2Cntr "counter";
CM_ SG_ 85 AccrPedlLnrAccrPedlRat "CVC filtered accelerator pedal";
CM_ SG_ 85 AccrPedlLnrChks "checksum";
CM_ SG_ 85 AccrPedlLnrCntr "counter";
CM_ SG_ 85 AgDataRaw2SafeChks "IMU pitch rate data. Check sum";
CM_ SG_ 85 AgDataRaw2SafeCntr "IMU pitch rate data. Counter";
CM_ SG_ 85 AgDataRaw2SafePitchRate "IMU pitch rate data. Pitch Rate";
CM_ SG_ 85 AgDataRaw2SafePitchRateQf "IMU pitch rate data. Quality factor for Pitch Rate";
CM_ SG_ 375 RlyPwrDistbnCmd1WdIgnRlyCmd "Ignition relay status";
CM_ SG_ 342 TiAndDateIndcnDataValid "Current time (Hr, Min and Sec) and date (Year, Months and days) data for indication. See requirement for more information about the signals. Signal qualifier, No means values should be ignored.";
CM_ SG_ 342 TiAndDateIndcnDay "Current time (Hr, Min and Sec) and date (Year, Months and days) data for indication. See requirement for more information about the signals. Day";
CM_ SG_ 342 TiAndDateIndcnHr1 "Current time (Hr, Min and Sec) and date (Year, Months and days) data for indication. See requirement for more information about the signals. Hour";
CM_ SG_ 342 TiAndDateIndcnMins1 "Current time (Hr, Min and Sec) and date (Year, Months and days) data for indication. See requirement for more information about the signals. Minutes";
CM_ SG_ 342 TiAndDateIndcnMth1 "Current time (Hr, Min and Sec) and date (Year, Months and days) data for indication. See requirement for more information about the signals. Month, 1-12";
CM_ SG_ 342 TiAndDateIndcnSec1 "Current time (Hr, Min and Sec) and date (Year, Months and days) data for indication. See requirement for more information about the signals. Seconds";
CM_ SG_ 342 TiAndDateIndcnYr1 "Current time (Hr, Min and Sec) and date (Year, Months and days) data for indication. See requirement for more information about the signals. Year, 0-99";
CM_ SG_ 1434 VDDMdevelpsignalgroupresp1Functiondevpsignalgroup1 "develop signal group response";
CM_ SG_ 1434 VDDMdevelpsignalgroupresp1Functiondevpsignalgroup2 "develop signal group response";
CM_ SG_ 1434 VDDMdevelpsignalgroupresp1Functiondevpsignalgroup3 "develop signal group response";
CM_ SG_ 1434 VDDMdevelpsignalgroupresp1Functiondevpsignalgroup4 "develop signal group response";
CM_ SG_ 1434 VDDMdevelpsignalgroupresp1Functiondevpsignalgroup5 "develop signal group response";
CM_ SG_ 1434 VDDMdevelpsignalgroupresp1Functiondevpsignalgroup6 "develop signal group response";
CM_ SG_ 1434 VDDMdevelpsignalgroupresp1Functiondevpsignalgroup7 "develop signal group response";
CM_ SG_ 1434 VDDMdevelpsignalgroupresp1Functiondevpsignalgroup8 "develop signal group response";
CM_ SG_ 1435 VDDMdevelpsignalgroupresp2Functiondevpsignalgroup1 "develop signal group response";
CM_ SG_ 1435 VDDMdevelpsignalgroupresp2Functiondevpsignalgroup2 "develop signal group response";
CM_ SG_ 1435 VDDMdevelpsignalgroupresp2Functiondevpsignalgroup3 "develop signal group response";
CM_ SG_ 1435 VDDMdevelpsignalgroupresp2Functiondevpsignalgroup4 "develop signal group response";
CM_ SG_ 1435 VDDMdevelpsignalgroupresp2Functiondevpsignalgroup5 "develop signal group response";
CM_ SG_ 1435 VDDMdevelpsignalgroupresp2Functiondevpsignalgroup6 "develop signal group response";
CM_ SG_ 1435 VDDMdevelpsignalgroupresp2Functiondevpsignalgroup7 "develop signal group response";
CM_ SG_ 1435 VDDMdevelpsignalgroupresp2Functiondevpsignalgroup8 "develop signal group response";
CM_ SG_ 81 AsyDataWithCmpSafeALat1Qf "IMU processed special data. Quality factor for Lateral acceleration signal";
CM_ SG_ 81 AsyDataWithCmpSafeALatWithCmp "IMU processed special data.  Compensated Lateral acceleration";
CM_ SG_ 81 AsyDataWithCmpSafeALgt1Qf "IMU processed special data. Quality factor for Longitudinal acceleration";
CM_ SG_ 81 AsyDataWithCmpSafeChks "IMU processed special data. Check sum";
CM_ SG_ 81 AsyDataWithCmpSafeCntr "IMU processed special data. Counter";
CM_ SG_ 81 AsyDataWithCmpSafeGrdtOfALgt "IMU processed special data. Derivative of Longitudinal acceleration";
CM_ SG_ 81 AsyDataWithCmpSafeYawRateQf "IMU processed special data. Quality Factor for Yaw Rate";
CM_ SG_ 81 AsyDataWithCmpSafeYawRateWithCmp "IMU processed special data. Compensated Yaw rate";
CM_ SG_ 160 ADataRawSafeALat "IMU acceleration data Lateral acceleration";
CM_ SG_ 160 ADataRawSafeALat1Qf "IMU acceleration data Quality factor for Lateral acceleration signal";
CM_ SG_ 160 ADataRawSafeALgt "IMU acceleration data Longitudinal acceleration";
CM_ SG_ 160 ADataRawSafeALgt1Qf "IMU acceleration data Quality factor for Longitudinal acceleration";
CM_ SG_ 160 ADataRawSafeAVert "IMU acceleration data Vertical acceleration";
CM_ SG_ 160 ADataRawSafeAVertQf "IMU acceleration data Quality factor for Vertical acceleration";
CM_ SG_ 160 ADataRawSafeChks "IMU acceleration data Check sum";
CM_ SG_ 160 ADataRawSafeCntr "IMU acceleration data Counter";
CM_ SG_ 400 AbsCtrlActvChks "checksum";
CM_ SG_ 400 AbsCtrlActvCntr "counter";
CM_ SG_ 400 AbsCtrlActvCtrlSts1 "Anti Blocking Systems (ABS) control is active (at least one wheel)
0 = No wheel is in Anti Blocking Systems (ABS) control
1 = At least one wheel is in Anti Blocking Systems (ABS) control";
CM_ SG_ 400 AmbTRawAmbTVal "Unfiltered ambient temp raw data in deg C. Ambient temp value";
CM_ SG_ 400 AmbTRawQly "Unfiltered ambient temp raw data in deg C. Quality Factor of the ambient temp";
CM_ SG_ 400 LatCtrlReqSafeChks "Requests for lateral control by steering actuator. Checksum";
CM_ SG_ 400 LatCtrlReqSafeCntr "Requests for lateral control by steering actuator. Counter";
CM_ SG_ 400 LatCtrlReqSafeLatCtrlModReq "Request";
CM_ SG_ 400 LatCtrlReqSafeSteerTqReq "Requests for lateral control by steering actuator. Steering wheel torque request.";
CM_ SG_ 400 LatCtrlReqSafeSteerWhlHptcWarnReq "Enable steering wheel haptic warning";
CM_ SG_ 224 VehSpdLgtA "Vehicle speed longitudinal based on wheel speed sensors and longitudinal acceleration.";
CM_ SG_ 224 VehSpdLgtChks "Checksum";
CM_ SG_ 224 VehSpdLgtCntr "Counter";
CM_ SG_ 224 VehSpdLgtQf "Quality factor for vehicle speed as measured by wheel speed sensors and longitudinal acceleration.";
CM_ SG_ 928 AmbTIndcdWithUnitAmbTIndcd "Indicated ambient temperature";
CM_ SG_ 928 AmbTIndcdWithUnitAmbTIndcdUnit "Unit of the indicated temperature";
CM_ SG_ 928 AmbTIndcdWithUnitQF "QF";
CM_ SG_ 433 BrkPedlPsdBrkPedlNotPsdSafe "Set to 1 if brake pedal is not pressed, otherwise 0";
CM_ SG_ 433 BrkPedlPsdBrkPedlPsd "Set to 1 if brake pedal is pressed, otherwise 0";
CM_ SG_ 433 BrkPedlPsdChks "Checksum";
CM_ SG_ 433 BrkPedlPsdCntr "Counter";
CM_ SG_ 433 BrkPedlPsdQf "Quality factor";
CM_ SG_ 433 WhlSpdCircumlFrntChks "Individual wheel speed from front wheel speed sensors. Checksum";
CM_ SG_ 433 WhlSpdCircumlFrntCntr "Individual wheel speed from front wheel speed sensors. Counter";
CM_ SG_ 433 WhlSpdCircumlFrntLe "Individual wheel speed from front wheel speed sensors. Wheel speed from front left wheel speed sensor using nominal value of wheel radius.";
CM_ SG_ 433 WhlSpdCircumlFrntLeQf "Individual wheel speed from front wheel speed sensors. Qf for wheel speed sensor";
CM_ SG_ 433 WhlSpdCircumlFrntRiQf "Individual wheel speed from front wheel speed sensors. Qf for wheel speed sensor";
CM_ SG_ 433 WhlSpdCircumlFrntWhlSpdCircumlFrntRi "Individual wheel speed from front wheel speed sensors. Wheel speed from front right wheel speed sensor using nominal value of wheel radius";
CM_ SG_ 432 AgDataRawSafeChks "IMU angular rate data. Check summa";
CM_ SG_ 432 AgDataRawSafeCntr "IMU angular rate data. Counter";
CM_ SG_ 432 AgDataRawSafeRollRate "IMU angular rate data. Roll Rate";
CM_ SG_ 432 AgDataRawSafeRollRateQf "IMU angular rate data. Quality factor for Roll Rate";
CM_ SG_ 432 AgDataRawSafeYawRate "IMU angular rate data. Yaw Rate";
CM_ SG_ 432 AgDataRawSafeYawRateQf "IMU angular rate data. Quality Factor for Yaw Rate";
CM_ SG_ 736 VehModMngtGlbSafe1CarModSts1 "CarMode Status";
CM_ SG_ 736 VehModMngtGlbSafe1CarModSubtypWdCarModSubtyp "CarMode substate status";
CM_ SG_ 736 VehModMngtGlbSafe1Chks "Checksum";
CM_ SG_ 736 VehModMngtGlbSafe1Cntr "Counter";
CM_ SG_ 736 VehModMngtGlbSafe1EgyLvlElecMai "Main energy level in the vehicle.";
CM_ SG_ 736 VehModMngtGlbSafe1EgyLvlElecSubtyp "Substate of the energy level in the vehicle.";
CM_ SG_ 736 VehModMngtGlbSafe1FltEgyCnsWdSts "High quiescent current detected by CEM via BMS.";
CM_ SG_ 736 VehModMngtGlbSafe1PwrLvlElecMai "Main Power level in the vehicle.";
CM_ SG_ 736 VehModMngtGlbSafe1PwrLvlElecSubtyp "Substate of the power level in the vehicle.";
CM_ SG_ 736 VehModMngtGlbSafe1UsgModSts "UsageMode Status";
CM_ SG_ 38 VFCInfoEna "VFCVectorFrame enable and disable setting";
CM_ SG_ 1123 SteerSetgPen "IdPen";
CM_ SG_ 1123 SteerSetgSteerAsscLvl "Steer Assistance Level";
CM_ SG_ 1123 SteerSetgSteerMod "Steer Mode";
CM_ SG_ 784 CmptmtTFrntCmptmtTFrnt "Measured temperature in compartment. ";
CM_ SG_ 784 CmptmtTFrntFanForCmptmtTRunng "Fan for component temperature requirement.";
CM_ SG_ 784 CmptmtTFrntQf "Component temperature sensor signal quality.";
CM_ SG_ 137 HsaSt "HSA function status";
CM_ SG_ 137 WhlFastSpdSafeA "Vehicle speed longitudinal based on wheel speed sensors and longitudinal acceleration.";
CM_ SG_ 137 WhlFastSpdSafeChks "checksum";
CM_ SG_ 137 WhlFastSpdSafeCntr "counter";
CM_ SG_ 137 WhlFastSpdSafeQF "Quality factor for vehicle speed as measured by wheel speed sensors and longitudinal acceleration.";
CM_ SG_ 592 VehCfgPrmBlkIDBytePosn1 "signal block counter.";
CM_ SG_ 592 VehCfgPrmCCPBytePosn2 " (BlockID-1)*7 + 1. ";
CM_ SG_ 592 VehCfgPrmCCPBytePosn3 " (BlockID-1)*7 + 2. ";
CM_ SG_ 592 VehCfgPrmCCPBytePosn4 " (BlockID-1)*7 + 3. ";
CM_ SG_ 592 VehCfgPrmCCPBytePosn5 " (BlockID-1)*7 + 4. ";
CM_ SG_ 592 VehCfgPrmCCPBytePosn6 " (BlockID-1)*7 + 5. ";
CM_ SG_ 592 VehCfgPrmCCPBytePosn7 " (BlockID-1)*7 + 6. ";
CM_ SG_ 592 VehCfgPrmCCPBytePosn8 " (BlockID-1)*7 + 7. ";
CM_ SG_ 1015 VehCfgPrmExtBlkIDBytePosn1 "CarConfigExtended BlockID";
CM_ SG_ 1015 VehCfgPrmExtCCPBytePosn2 "CarConfigExtended BytePos2";
CM_ SG_ 1015 VehCfgPrmExtCCPBytePosn3 "CarConfigExtended BytePos3";
CM_ SG_ 1015 VehCfgPrmExtCCPBytePosn4 "CarConfigExtended BytePos4";
CM_ SG_ 1015 VehCfgPrmExtCCPBytePosn5 "CarConfigExtended BytePos5";
CM_ SG_ 1015 VehCfgPrmExtCCPBytePosn6 "CarConfigExtended BytePos6";
CM_ SG_ 1015 VehCfgPrmExtCCPBytePosn7 "CarConfigExtended BytePos7";
CM_ SG_ 1015 VehCfgPrmExtCCPBytePosn8 "CarConfigExtended BytePos8";
CM_ SG_ 686 AbsSts "Indicates if the ABS function is temporarily or permantly disabled due to a failure.";
CM_ SG_ 686 DrvModReq "drive mode";
CM_ SG_ 686 ULoWarnChks "Checksum";
CM_ SG_ 686 ULoWarnCntr "Counter";
CM_ SG_ 686 ULoWarnULoWarn "Low voltage warning at LVEEM system";
CM_ SG_ 1267 EscStChks "Information on activation/ deactivation of Electronic Stability Control (ESC) Checksum for Esc state";
CM_ SG_ 1267 EscStCntr "Information on activation/ deactivation of Electronic Stability Control (ESC) Counter for Esc state";
CM_ SG_ 1267 EscStEscSt "Information on activation/ deactivation of Electronic Stability Control (ESC) Esc state information for Esc ON, Esc OFF or Esc Sport";
CM_ SG_ 1099 BrkTracCtrlActv "Indicates InCtrl if brake traction control (TC) is active on at least one wheel.";
CM_ SG_ 1099 WhlRotToothCntrChks "check sum";
CM_ SG_ 1099 WhlRotToothCntrCntr "counter";
CM_ SG_ 1099 WhlRotToothCntrFrntLe "Wheel rotation ticks for each individual wheel. Wheel rotation impuls counter front left. For one complete wheel revolution the counter will increase by 96 (with 48 magnetic pole-pairs).";
CM_ SG_ 1099 WhlRotToothCntrFrntRi "Wheel rotation ticks for each individual wheel. Wheel rotation impuls counter front right. For one complete wheel revolution the counter will increase by 96 (with 48 magnetic pole-pairs).";
CM_ SG_ 1099 WhlRotToothCntrReLe "Wheel rotation ticks for each individual wheel. Wheel rotation impuls counter rear left. For one complete wheel revolution the counter will increase by 96 (with 48 magnetic pole-pairs).";
CM_ SG_ 1099 WhlRotToothCntrReRi "Wheel rotation ticks for each individual wheel. Wheel rotation impuls counter rear right. For one complete wheel revolution the counter will increase by 96 (with 48 magnetic pole-pairs).";
CM_ SG_ 26 AgDataCmpQualityPitchRateCmpQuality "Quality of offset compensation for pitchrate";
CM_ SG_ 26 AgDataCmpQualityRollRateCmpQuality "Quality of offset compensation for rollrate";
CM_ SG_ 26 AgDataCmpQualityYawRateCmpQuality "Quality of offset compensation for yawrate";
CM_ SG_ 1159 VehMtnStChks "Vehicle motion state information based on wheel speed sensors. Provides information about vehicle stand still and vehicle rolling direction. Checksum for vehicle motion state";
CM_ SG_ 1159 VehMtnStCntr "Vehicle motion state information based on wheel speed sensors. Provides information about vehicle stand still and vehicle rolling direction. Counter for vehicle motion state";
CM_ SG_ 1159 VehMtnStVehMtnSt "Vehicle motion state information based on wheel speed sensors. Provides information about vehicle stand still and vehicle rolling direction. Vehicle motion state";
CM_ SG_ 864 CarTiGlb "Presents a tiime value that shall be used by all ECUs to time-stamp diagnsotic trouble codes (DTC) according to the requirements for Global DTC snapshot data.";
CM_ SG_ 864 ProfPenSts1 "Signal communicates which profile that is active in the car
(Personal settings).";
CM_ SG_ 864 SaveSetgToMemPrmnt "Signal for personal settings saving concept
0: Profile locked, no saving to be performed
1: On the event (toggle 0 to 1) settings shall be saved (manually saving)
2: Automatic saving";
CM_ SG_ 896 VehBattUSysU "Vehicle System Voltage At 12V side";
CM_ SG_ 896 VehBattUSysUQf "Present vehicle voltage measured by CEM with QF";
CM_ SG_ 496 BkpOfDstTrvld "total traveled distance.";
CM_ SG_ 496 DrvModReqForChampnMod "Drive Mode for champion mode";
CM_ SG_ 580 IDcDcActLoSideChks "Actul current output checksum";
CM_ SG_ 580 IDcDcActLoSideCntr "Actul current output counter";
CM_ SG_ 580 IDcDcActLoSideIDcDcActLoSide "Actul current output";
CM_ SG_ 439 WhlSpdCircumlReChks "Individual wheel speed from rear wheel speed sensors. Checksum";
CM_ SG_ 439 WhlSpdCircumlReCntr "Individual wheel speed from rear wheel speed sensors. Counter";
CM_ SG_ 439 WhlSpdCircumlReLe "Individual wheel speed from rear wheel speed sensors. Wheel speed from rear left wheel speed sensor using nominal value of wheel radius.";
CM_ SG_ 439 WhlSpdCircumlReLeQf "Individual wheel speed from rear wheel speed sensors. Qf for wheel speed sensor";
CM_ SG_ 439 WhlSpdCircumlReRi "Individual wheel speed from rear wheel speed sensors. Wheel speed from rear right wheel speed sensor using nominal value of wheel radius.";
CM_ SG_ 439 WhlSpdCircumlReRiQf "Individual wheel speed from rear wheel speed sensors. Qf for wheel speed sensor";

// Attribute definitions
BA_DEF_  "Baudrate" INT 1000 1000000; // [bps]
BA_DEF_  "BusType" STRING;
BA_DEF_  "DBName" STRING;
BA_DEF_  "ProtocolType" STRING;
BA_DEF_ BU_ "NmAsrNode" ENUM "No","Yes";
BA_DEF_ BU_ "NmAsrNodeIdentifier" INT 0 255;
BA_DEF_ BO_ "GenMsgCycleTime" INT 0 65536; // [ms]
BA_DEF_ BO_ "GenMsgDelayTime" INT 0 65536; // [ms]
BA_DEF_ BO_ "GenMsgSendType" ENUM "cyclic", "spontaneous", "not-used", "not-used", "not-used", "cyclicAndSpontaneous", "not-used", "cyclicIfActive", "NoMsgSendType"; // [us]
BA_DEF_ BO_ "GenMsgStartDelayTime" INT 0 65536; // [ms]
BA_DEF_ SG_ "GenSigSendType" ENUM "Cyclic","OnWrite","OnWriteWithRepetition","OnChange","OnChangeWithRepetition","IfActive","IfActiveWithRepetition","NoSigSendType";
BA_DEF_ SG_ "GenSigStartValue" HEX 0 80000000;
BA_DEF_ BO_ "GenMsgILSupport" ENUM "No","Yes";
BA_DEF_ BO_ "NmAsrMessage" ENUM "No","Yes";
BA_DEF_  "NmAsrBaseAddress" HEX 0 536870911;
BA_DEF_  "NmAsrMessageCount" INT 0 255;
BA_DEF_ BU_ "NodeLayerModules" STRING;
BA_DEF_ BU_ "ILused" ENUM "No","Yes";
BA_DEF_ SG_ "GenSigFuncType" ENUM "NoFunction","n/a","n/a","n/a","n/a","n/a","n/a","n/a","n/a","n/a","n/a","n/a","n/a","n/a","n/a","CHK","CNTR","n/a","n/a","n/a","CNTR_AR_01","CRC_AR_01_BOTH","CRC_AR_01_ALT","CRC_AR_01_LOW","CRC_AR_01_NIBBLE","CNTR_AR_04","CRC_AR_04A","CNTR_AR_05","CRC_AR_05";
BA_DEF_ SG_ "GenSigDataID" STRING;

BA_DEF_DEF_ "BusType" "";
BA_DEF_DEF_ "DBName" "";
BA_DEF_DEF_ "ProtocolType" "";
BA_DEF_DEF_ "NmAsrNode" "No";
BA_DEF_DEF_ "NmAsrNodeIdentifier" 0;
BA_DEF_DEF_ "GenSigStartValue" 0;
BA_DEF_DEF_ "GenSigSendType" "NoSigSendType";
BA_DEF_DEF_ "GenMsgCycleTime" 0;
BA_DEF_DEF_ "GenMsgDelayTime" 0;
BA_DEF_DEF_ "GenMsgStartDelayTime" 0;
BA_DEF_DEF_ "GenMsgSendType" "NoMsgSendType";
BA_DEF_DEF_ "GenMsgILSupport" "Yes";
BA_DEF_DEF_ "NmAsrMessage" "No";
BA_DEF_DEF_ "NmAsrBaseAddress" 1280;
BA_DEF_DEF_ "NmAsrMessageCount" 64;
BA_DEF_DEF_ "NodeLayerModules" "CANoeILNLSPA.dll";
BA_DEF_DEF_ "ILused" "Yes";
BA_DEF_DEF_ "GenSigFuncType" "NoFunction";
BA_DEF_DEF_ "GenSigDataID" "";

BA_ "Baudrate" 500000;
BA_ "BusType" "CAN";
BA_ "DBName" "ChassisCAN1";
BA_ "ProtocolType" "CAN";
// Network
// ECU: ASDM
BA_ "NmAsrNode" BU_ ASDM 1;
BA_ "NmAsrNodeIdentifier" BU_ ASDM 41;
BA_ "NodeLayerModules" BU_ ASDM "CANoeILNLSPA.dll,AsrNM33.dll";
// ECU: BBM
BA_ "NmAsrNode" BU_ BBM 1;
BA_ "NmAsrNodeIdentifier" BU_ BBM 54;
BA_ "NodeLayerModules" BU_ BBM "CANoeILNLSPA.dll,AsrNM33.dll";
// ECU: ETC
BA_ "ILused" BU_ ETC 0;
// ECU: PSCM1
BA_ "NmAsrNode" BU_ PSCM1 1;
BA_ "NmAsrNodeIdentifier" BU_ PSCM1 35;
BA_ "NodeLayerModules" BU_ PSCM1 "CANoeILNLSPA.dll,AsrNM33.dll";
// ECU: PSCM2
BA_ "ILused" BU_ PSCM2 0;
// ECU: RBCM
BA_ "NmAsrNode" BU_ RBCM 1;
BA_ "NmAsrNodeIdentifier" BU_ RBCM 53;
BA_ "NodeLayerModules" BU_ RBCM "CANoeILNLSPA.dll,AsrNM33.dll";
// ECU: SAS
BA_ "NmAsrNode" BU_ SAS 1;
BA_ "NmAsrNodeIdentifier" BU_ SAS 39;
BA_ "NodeLayerModules" BU_ SAS "CANoeILNLSPA.dll,AsrNM33.dll";
// ECU: VDDM
BA_ "NmAsrNode" BU_ VDDM 1;
BA_ "NmAsrNodeIdentifier" BU_ VDDM 33;
BA_ "NodeLayerModules" BU_ VDDM "CANoeILNLSPA.dll,AsrNM33.dll";
// Frame: AsdmChas1Fr01
BA_ "GenMsgCycleTime" BO_ 147 20.000;
BA_ "GenMsgSendType" BO_ 147 0;
// Frame: AsdmChas1Fr03
BA_ "GenMsgCycleTime" BO_ 51 10.000;
BA_ "GenMsgSendType" BO_ 51 0;
// Frame: AsdmChas1NMFr
BA_ "GenMsgDelayTime" BO_ 1321 20.000;
BA_ "GenMsgSendType" BO_ 1321 1;
// Frame: BcmChas1Fr01
BA_ "GenMsgCycleTime" BO_ 308 50.000;
BA_ "GenMsgSendType" BO_ 308 0;
// Frame: BcmChas1Fr02
BA_ "GenMsgCycleTime" BO_ 327 50.000;
BA_ "GenMsgSendType" BO_ 327 0;
// Frame: BcmChas1Fr03
BA_ "GenMsgCycleTime" BO_ 84 10.000;
BA_ "GenMsgSendType" BO_ 84 0;
// Frame: BcmChas1Fr06
BA_ "GenMsgCycleTime" BO_ 129 10.000;
BA_ "GenMsgSendType" BO_ 129 0;
// Frame: BcmChas1Fr07
BA_ "GenMsgCycleTime" BO_ 265 20.000;
BA_ "GenMsgSendType" BO_ 265 0;
// Frame: BcmChas1Fr09
BA_ "GenMsgCycleTime" BO_ 185 20.000;
BA_ "GenMsgSendType" BO_ 185 0;
// Frame: BcmChas1NMFr
BA_ "GenMsgDelayTime" BO_ 1334 20.000;
BA_ "GenMsgSendType" BO_ 1334 1;
// Frame: EcmChas1BsgFr40
BA_ "GenMsgCycleTime" BO_ 134 50.000;
BA_ "GenMsgSendType" BO_ 134 0;
// Frame: EcmChas1BsgFr41
BA_ "GenMsgCycleTime" BO_ 544 100.000;
BA_ "GenMsgSendType" BO_ 544 0;
// Frame: EcmChas1Fr08
BA_ "GenMsgCycleTime" BO_ 1111 50.000;
BA_ "GenMsgSendType" BO_ 1111 0;
// Frame: EcmChas1Fr31
BA_ "GenMsgCycleTime" BO_ 131 10.000;
BA_ "GenMsgSendType" BO_ 131 0;
// Frame: EcmChas1Fr37
BA_ "GenMsgCycleTime" BO_ 752 80.000;
BA_ "GenMsgSendType" BO_ 752 0;
// Frame: EcmChas1Fr53
BA_ "GenMsgCycleTime" BO_ 121 20.000;
BA_ "GenMsgSendType" BO_ 121 0;
// Frame: EtcToMvemXcpFr01
BA_ "GenMsgDelayTime" BO_ 1429 5.000;
BA_ "GenMsgSendType" BO_ 1429 1;
// Frame: EtcToMvemXcpFr02
BA_ "GenMsgDelayTime" BO_ 1424 5.000;
BA_ "GenMsgSendType" BO_ 1424 1;
// Frame: EtcToMvemXcpFr03
BA_ "GenMsgDelayTime" BO_ 1425 5.000;
BA_ "GenMsgSendType" BO_ 1425 1;
// Frame: EtcToPscm1cChas1XcpFr01
BA_ "GenMsgDelayTime" BO_ 1441 5.000;
BA_ "GenMsgSendType" BO_ 1441 1;
// Frame: EtcToPscmChas1XcpFr01
BA_ "GenMsgDelayTime" BO_ 1409 5.000;
BA_ "GenMsgSendType" BO_ 1409 1;
// Frame: EtcToPscmChas1XcpFr02
BA_ "GenMsgDelayTime" BO_ 1416 5.000;
BA_ "GenMsgSendType" BO_ 1416 1;
// Frame: EtcToPscmChas1XcpFr03
BA_ "GenMsgDelayTime" BO_ 1418 5.000;
BA_ "GenMsgSendType" BO_ 1418 1;
// Frame: EtcToPscmChas1XcpFr04
BA_ "GenMsgDelayTime" BO_ 1420 5.000;
BA_ "GenMsgSendType" BO_ 1420 1;
// Frame: EtcToPscmDevelFr
BA_ "GenMsgDelayTime" BO_ 1431 95.000;
BA_ "GenMsgSendType" BO_ 1431 1;
// Frame: EtcToRasmChas1XcpFr01
BA_ "GenMsgDelayTime" BO_ 1442 5.000;
BA_ "GenMsgSendType" BO_ 1442 1;
// Frame: EtcToRbcmChas1DevFr01
BA_ "GenMsgDelayTime" BO_ 1504 95.000;
BA_ "GenMsgSendType" BO_ 1504 1;
// Frame: EtcToTcmXcpFr01
BA_ "GenMsgDelayTime" BO_ 1414 10.000;
BA_ "GenMsgSendType" BO_ 1414 1;
// Frame: EtcToTcmXcpFr02
BA_ "GenMsgDelayTime" BO_ 1411 10.000;
BA_ "GenMsgSendType" BO_ 1411 1;
// Frame: EtctoVddmBcmXCPFr01
BA_ "GenMsgDelayTime" BO_ 1421 10.000;
BA_ "GenMsgSendType" BO_ 1421 1;
// Frame: EtctoVddmDevelFr01
BA_ "GenMsgDelayTime" BO_ 1432 95.000;
BA_ "GenMsgSendType" BO_ 1432 1;
// Frame: EtctoVddmDevelFr02
BA_ "GenMsgDelayTime" BO_ 1433 95.000;
BA_ "GenMsgSendType" BO_ 1433 1;
// Frame: PasChas1Fr02
BA_ "GenMsgCycleTime" BO_ 235 15.000;
BA_ "GenMsgSendType" BO_ 235 0;
// Frame: PasChas1Fr04
BA_ "GenMsgDelayTime" BO_ 149 10.000;
BA_ "GenMsgSendType" BO_ 149 1;
// Frame: Pscm2cToVddmChas1DiagResFrame
BA_ "GenMsgDelayTime" BO_ 1654 5.000;
BA_ "GenMsgSendType" BO_ 1654 1;
// Frame: PscmChas1Fr01
BA_ "GenMsgCycleTime" BO_ 246 10.000;
BA_ "GenMsgSendType" BO_ 246 0;
// Frame: PscmChas1Fr02
BA_ "GenMsgCycleTime" BO_ 70 15.000;
BA_ "GenMsgSendType" BO_ 70 0;
// Frame: PscmChas1Fr03
BA_ "GenMsgCycleTime" BO_ 444 25.000;
BA_ "GenMsgSendType" BO_ 444 0;
// Frame: PscmChas1Fr06
BA_ "GenMsgCycleTime" BO_ 955 400.000;
BA_ "GenMsgSendType" BO_ 955 0;
// Frame: PscmChas1Fr07
BA_ "GenMsgCycleTime" BO_ 78 10.000;
BA_ "GenMsgSendType" BO_ 78 0;
// Frame: PscmChas1NMFr
BA_ "GenMsgDelayTime" BO_ 1315 20.000;
BA_ "GenMsgSendType" BO_ 1315 1;
// Frame: PscmDevelpFr
BA_ "GenMsgDelayTime" BO_ 1430 95.000;
BA_ "GenMsgSendType" BO_ 1430 1;
// Frame: PscmToEtcChas1XcpFr01
BA_ "GenMsgDelayTime" BO_ 1410 5.000;
BA_ "GenMsgSendType" BO_ 1410 1;
// Frame: PscmToEtcChas1XcpFr02
BA_ "GenMsgDelayTime" BO_ 1417 5.000;
BA_ "GenMsgSendType" BO_ 1417 1;
// Frame: PscmToEtcChas1XcpFr03
BA_ "GenMsgDelayTime" BO_ 1419 5.000;
BA_ "GenMsgSendType" BO_ 1419 1;
// Frame: PscmToEtcChas1XcpFr04
BA_ "GenMsgDelayTime" BO_ 1415 5.000;
BA_ "GenMsgSendType" BO_ 1415 1;
// Frame: PscmToEtcChas1XcpFr05
BA_ "GenMsgDelayTime" BO_ 1412 5.000;
BA_ "GenMsgSendType" BO_ 1412 1;
// Frame: PscmToEtcChas1XcpFr06
BA_ "GenMsgDelayTime" BO_ 1423 5.000;
BA_ "GenMsgSendType" BO_ 1423 1;
// Frame: PscmToVddmChas1DiagResFrame
BA_ "GenMsgDelayTime" BO_ 1648 5.000;
BA_ "GenMsgSendType" BO_ 1648 1;
// Frame: RbcmChas1Fr01
BA_ "GenMsgCycleTime" BO_ 66 10.000;
BA_ "GenMsgSendType" BO_ 66 0;
// Frame: RbcmChas1Fr02
BA_ "GenMsgCycleTime" BO_ 289 20.000;
BA_ "GenMsgSendType" BO_ 289 0;
// Frame: RbcmChas1Fr03
BA_ "GenMsgCycleTime" BO_ 545 70.000;
BA_ "GenMsgSendType" BO_ 545 0;
// Frame: RbcmChas1Fr04
BA_ "GenMsgCycleTime" BO_ 562 70.000;
BA_ "GenMsgSendType" BO_ 562 0;
// Frame: RbcmChas1Fr05
BA_ "GenMsgCycleTime" BO_ 569 70.000;
BA_ "GenMsgSendType" BO_ 569 0;
// Frame: RbcmChas1Fr06
BA_ "GenMsgCycleTime" BO_ 593 80.000;
BA_ "GenMsgSendType" BO_ 593 0;
// Frame: RbcmChas1Fr09
BA_ "GenMsgCycleTime" BO_ 323 20.000;
BA_ "GenMsgSendType" BO_ 323 0;
// Frame: RbcmChas1Fr10
BA_ "GenMsgCycleTime" BO_ 177 20.000;
BA_ "GenMsgSendType" BO_ 177 0;
// Frame: RbcmChas1Fr11
BA_ "GenMsgCycleTime" BO_ 181 20.000;
BA_ "GenMsgSendType" BO_ 181 0;
// Frame: RbcmChas1Fr12
BA_ "GenMsgCycleTime" BO_ 193 20.000;
BA_ "GenMsgSendType" BO_ 193 0;
// Frame: RbcmChas1Fr13
BA_ "GenMsgCycleTime" BO_ 200 20.000;
BA_ "GenMsgSendType" BO_ 200 0;
// Frame: RbcmChas1Fr14
BA_ "GenMsgCycleTime" BO_ 166 20.000;
BA_ "GenMsgSendType" BO_ 166 0;
// Frame: RbcmChas1NMFr
BA_ "GenMsgDelayTime" BO_ 1333 20.000;
BA_ "GenMsgSendType" BO_ 1333 1;
// Frame: RbcmChas1VFCVectorFr
BA_ "GenMsgDelayTime" BO_ 1383 495.000;
BA_ "GenMsgSendType" BO_ 1383 1;
// Frame: RbcmToVddmChas1DiagResFrame
BA_ "GenMsgDelayTime" BO_ 1653 5.000;
BA_ "GenMsgSendType" BO_ 1653 1;
// Frame: SasChas1Fr01
BA_ "GenMsgCycleTime" BO_ 64 10.000;
BA_ "GenMsgSendType" BO_ 64 0;
// Frame: SasChas1NMFr
BA_ "GenMsgDelayTime" BO_ 1319 20.000;
BA_ "GenMsgSendType" BO_ 1319 1;
// Frame: SasToVddmChas1DiagResFrame
BA_ "GenMsgDelayTime" BO_ 1650 5.000;
BA_ "GenMsgSendType" BO_ 1650 1;
// Frame: VcuChas1Fr01
BA_ "GenMsgCycleTime" BO_ 54 10.000;
BA_ "GenMsgSendType" BO_ 54 0;
// Frame: VcuChas1Fr02
BA_ "GenMsgCycleTime" BO_ 274 20.000;
BA_ "GenMsgSendType" BO_ 274 0;
// Frame: VcuChas1Fr03
BA_ "GenMsgCycleTime" BO_ 85 10.000;
BA_ "GenMsgSendType" BO_ 85 0;
// Frame: VcuChas1Fr04
BA_ "GenMsgCycleTime" BO_ 375 50.000;
BA_ "GenMsgSendType" BO_ 375 0;
// Frame: VcuChas1Fr06
BA_ "GenMsgCycleTime" BO_ 342 30.000;
BA_ "GenMsgSendType" BO_ 342 0;
// Frame: VddmChas1DevFr01
BA_ "GenMsgDelayTime" BO_ 1434 95.000;
BA_ "GenMsgSendType" BO_ 1434 1;
// Frame: VddmChas1DevFr02
BA_ "GenMsgDelayTime" BO_ 1435 95.000;
BA_ "GenMsgSendType" BO_ 1435 1;
// Frame: VddmChas1Fr01
BA_ "GenMsgCycleTime" BO_ 81 10.000;
BA_ "GenMsgSendType" BO_ 81 0;
// Frame: VddmChas1Fr03
BA_ "GenMsgCycleTime" BO_ 160 15.000;
BA_ "GenMsgSendType" BO_ 160 0;
// Frame: VddmChas1Fr04
BA_ "GenMsgCycleTime" BO_ 400 20.000;
BA_ "GenMsgSendType" BO_ 400 0;
// Frame: VddmChas1Fr05
BA_ "GenMsgCycleTime" BO_ 224 20.000;
BA_ "GenMsgSendType" BO_ 224 0;
// Frame: VddmChas1Fr08
BA_ "GenMsgCycleTime" BO_ 928 320.000;
BA_ "GenMsgSendType" BO_ 928 0;
// Frame: VddmChas1Fr10
BA_ "GenMsgCycleTime" BO_ 433 30.000;
BA_ "GenMsgSendType" BO_ 433 0;
// Frame: VddmChas1Fr14
BA_ "GenMsgCycleTime" BO_ 432 30.000;
BA_ "GenMsgSendType" BO_ 432 0;
// Frame: VddmChas1Fr19
BA_ "GenMsgCycleTime" BO_ 736 70.000;
BA_ "GenMsgSendType" BO_ 736 0;
// Frame: VddmChas1Fr21
BA_ "GenMsgDelayTime" BO_ 38 300.000;
BA_ "GenMsgSendType" BO_ 38 1;
// Frame: VddmChas1Fr22
BA_ "GenMsgCycleTime" BO_ 1123 170.000;
BA_ "GenMsgSendType" BO_ 1123 0;
// Frame: VddmChas1Fr23
BA_ "GenMsgCycleTime" BO_ 784 170.000;
BA_ "GenMsgSendType" BO_ 784 0;
// Frame: VddmChas1Fr24
BA_ "GenMsgCycleTime" BO_ 137 20.000;
BA_ "GenMsgSendType" BO_ 137 0;
// Frame: VddmChas1Fr30
BA_ "GenMsgDelayTime" BO_ 592 80.000;
BA_ "GenMsgSendType" BO_ 592 1;
// Frame: VddmChas1Fr33
BA_ "GenMsgDelayTime" BO_ 1015 80.000;
BA_ "GenMsgSendType" BO_ 1015 1;
// Frame: VddmChas1Fr41
BA_ "GenMsgCycleTime" BO_ 686 120.000;
BA_ "GenMsgSendType" BO_ 686 0;
// Frame: VddmChas1Fr44
BA_ "GenMsgCycleTime" BO_ 1267 170.000;
BA_ "GenMsgSendType" BO_ 1267 0;
// Frame: VddmChas1Fr46
BA_ "GenMsgCycleTime" BO_ 1099 170.000;
BA_ "GenMsgSendType" BO_ 1099 0;
// Frame: VddmChas1Fr47
BA_ "GenMsgCycleTime" BO_ 26 100.000;
BA_ "GenMsgSendType" BO_ 26 0;
// Frame: VddmChas1Fr48
BA_ "GenMsgCycleTime" BO_ 1159 700.000;
BA_ "GenMsgSendType" BO_ 1159 0;
// Frame: VddmChas1Fr49
BA_ "GenMsgCycleTime" BO_ 864 80.000;
BA_ "GenMsgSendType" BO_ 864 0;
// Frame: VddmChas1Fr50
BA_ "GenMsgCycleTime" BO_ 896 700.000;
BA_ "GenMsgSendType" BO_ 896 0;
// Frame: VddmChas1Fr53
BA_ "GenMsgCycleTime" BO_ 496 30.000;
BA_ "GenMsgSendType" BO_ 496 0;
// Frame: VddmChas1Fr54
BA_ "GenMsgCycleTime" BO_ 580 200.000;
BA_ "GenMsgSendType" BO_ 580 0;
// Frame: VddmChas1Fr55
BA_ "GenMsgCycleTime" BO_ 439 30.000;
BA_ "GenMsgSendType" BO_ 439 0;
// Frame: VddmChas1NMFr
BA_ "GenMsgDelayTime" BO_ 1313 20.000;
BA_ "GenMsgSendType" BO_ 1313 1;
// Frame: VddmToAllFuncChas1DiagReqFrame
BA_ "GenMsgDelayTime" BO_ 2047 5.000;
BA_ "GenMsgSendType" BO_ 2047 1;
// Frame: VddmToPscm100FITbChas1DiagReqFrame
BA_ "GenMsgDelayTime" BO_ 1908 5.000;
BA_ "GenMsgSendType" BO_ 1908 1;
// Frame: VddmToPscm2cChas1DiagReqFrame
BA_ "GenMsgDelayTime" BO_ 1910 5.000;
BA_ "GenMsgSendType" BO_ 1910 1;
// Frame: VddmToPscmChas1DiagReqFrame
BA_ "GenMsgDelayTime" BO_ 1904 5.000;
BA_ "GenMsgSendType" BO_ 1904 1;
// Frame: VddmToRbcmChas1DiagReqFrame
BA_ "GenMsgDelayTime" BO_ 1909 5.000;
BA_ "GenMsgSendType" BO_ 1909 1;
// Frame: VddmToSasChas1DiagReqFrame
BA_ "GenMsgDelayTime" BO_ 1906 5.000;
BA_ "GenMsgSendType" BO_ 1906 1;
BA_ "GenMsgILSupport" BO_ 1321 0;
BA_ "GenMsgILSupport" BO_ 1334 0;
BA_ "GenMsgILSupport" BO_ 1315 0;
BA_ "GenMsgILSupport" BO_ 1333 0;
BA_ "GenMsgILSupport" BO_ 1319 0;
BA_ "GenMsgILSupport" BO_ 1313 0;
BA_ "NmAsrMessage" BO_ 1321 1;
BA_ "NmAsrMessage" BO_ 1334 1;
BA_ "NmAsrMessage" BO_ 1315 1;
BA_ "NmAsrMessage" BO_ 1333 1;
BA_ "NmAsrMessage" BO_ 1319 1;
BA_ "NmAsrMessage" BO_ 1313 1;
BA_ "GenSigSendType" SG_ 323 AD4IMUAcceXAcce 0;
BA_ "GenSigDataID" SG_ 323 AD4IMUAcceXChks "0xDD9";
BA_ "GenSigFuncType" SG_ 323 AD4IMUAcceXChks 15;
BA_ "GenSigSendType" SG_ 323 AD4IMUAcceXChks 0;
BA_ "GenSigFuncType" SG_ 323 AD4IMUAcceXCntr 16;
BA_ "GenSigSendType" SG_ 323 AD4IMUAcceXCntr 0;
BA_ "GenSigSendType" SG_ 323 AD4IMUAcceXHead 0;
BA_ "GenSigSendType" SG_ 177 AD4IMUAcceYAcce 0;
BA_ "GenSigDataID" SG_ 177 AD4IMUAcceYChks "0xDDA";
BA_ "GenSigFuncType" SG_ 177 AD4IMUAcceYChks 15;
BA_ "GenSigSendType" SG_ 177 AD4IMUAcceYChks 0;
BA_ "GenSigFuncType" SG_ 177 AD4IMUAcceYCntr 16;
BA_ "GenSigSendType" SG_ 177 AD4IMUAcceYCntr 0;
BA_ "GenSigSendType" SG_ 177 AD4IMUAcceYHead 0;
BA_ "GenSigSendType" SG_ 181 AD4IMUAcceZAcce 0;
BA_ "GenSigDataID" SG_ 181 AD4IMUAcceZChks "0xDDB";
BA_ "GenSigFuncType" SG_ 181 AD4IMUAcceZChks 15;
BA_ "GenSigSendType" SG_ 181 AD4IMUAcceZChks 0;
BA_ "GenSigFuncType" SG_ 181 AD4IMUAcceZCntr 16;
BA_ "GenSigSendType" SG_ 181 AD4IMUAcceZCntr 0;
BA_ "GenSigSendType" SG_ 181 AD4IMUAcceZHead 0;
BA_ "GenSigDataID" SG_ 193 AD4IMUGyroXChks "0xDDC";
BA_ "GenSigFuncType" SG_ 193 AD4IMUGyroXChks 15;
BA_ "GenSigSendType" SG_ 193 AD4IMUGyroXChks 0;
BA_ "GenSigFuncType" SG_ 193 AD4IMUGyroXCntr 16;
BA_ "GenSigSendType" SG_ 193 AD4IMUGyroXCntr 0;
BA_ "GenSigSendType" SG_ 193 AD4IMUGyroXGyro 0;
BA_ "GenSigSendType" SG_ 193 AD4IMUGyroXHead 0;
BA_ "GenSigDataID" SG_ 200 AD4IMUGyroYChks "0xDDD";
BA_ "GenSigFuncType" SG_ 200 AD4IMUGyroYChks 15;
BA_ "GenSigSendType" SG_ 200 AD4IMUGyroYChks 0;
BA_ "GenSigFuncType" SG_ 200 AD4IMUGyroYCntr 16;
BA_ "GenSigSendType" SG_ 200 AD4IMUGyroYCntr 0;
BA_ "GenSigSendType" SG_ 200 AD4IMUGyroYGyro 0;
BA_ "GenSigSendType" SG_ 200 AD4IMUGyroYHead 0;
BA_ "GenSigDataID" SG_ 166 AD4IMUGyroZChks "0xDDE";
BA_ "GenSigFuncType" SG_ 166 AD4IMUGyroZChks 15;
BA_ "GenSigSendType" SG_ 166 AD4IMUGyroZChks 0;
BA_ "GenSigFuncType" SG_ 166 AD4IMUGyroZCntr 16;
BA_ "GenSigSendType" SG_ 166 AD4IMUGyroZCntr 0;
BA_ "GenSigSendType" SG_ 166 AD4IMUGyroZGyro 0;
BA_ "GenSigSendType" SG_ 166 AD4IMUGyroZHead 0;
BA_ "GenSigDataID" SG_ 289 AD4IMUStatChks "0xDDF";
BA_ "GenSigFuncType" SG_ 289 AD4IMUStatChks 15;
BA_ "GenSigSendType" SG_ 289 AD4IMUStatChks 0;
BA_ "GenSigFuncType" SG_ 289 AD4IMUStatCntr 16;
BA_ "GenSigSendType" SG_ 289 AD4IMUStatCntr 0;
BA_ "GenSigSendType" SG_ 289 AD4IMUStatHead 0;
BA_ "GenSigSendType" SG_ 289 AD4IMUStatIMUStat 0;
BA_ "GenSigSendType" SG_ 289 AD4IMUStatIMUTemp 0;
BA_ "GenSigSendType" SG_ 246 ADL3LatCtrlStsADMod 0;
BA_ "GenSigDataID" SG_ 246 ADL3LatCtrlStsChks "0x463";
BA_ "GenSigFuncType" SG_ 246 ADL3LatCtrlStsChks 15;
BA_ "GenSigSendType" SG_ 246 ADL3LatCtrlStsChks 0;
BA_ "GenSigFuncType" SG_ 246 ADL3LatCtrlStsCntr 16;
BA_ "GenSigSendType" SG_ 246 ADL3LatCtrlStsCntr 0;
BA_ "GenSigSendType" SG_ 246 ADL3LatCtrlStsCtrlSts 0;
BA_ "GenSigSendType" SG_ 246 ADL3LatCtrlStsDegraded 0;
BA_ "GenSigSendType" SG_ 246 ADL3LatCtrlStsQf 0;
BA_ "GenSigSendType" SG_ 246 ADL3LatCtrlStsSts 0;
BA_ "GenSigSendType" SG_ 160 ADataRawSafeALat 0;
BA_ "GenSigSendType" SG_ 160 ADataRawSafeALat1Qf 0;
BA_ "GenSigStartValue" SG_ 160 ADataRawSafeALat1Qf 1;
BA_ "GenSigSendType" SG_ 160 ADataRawSafeALgt 0;
BA_ "GenSigSendType" SG_ 160 ADataRawSafeALgt1Qf 0;
BA_ "GenSigStartValue" SG_ 160 ADataRawSafeALgt1Qf 1;
BA_ "GenSigSendType" SG_ 160 ADataRawSafeAVert 0;
BA_ "GenSigStartValue" SG_ 160 ADataRawSafeAVert 1155;
BA_ "GenSigSendType" SG_ 160 ADataRawSafeAVertQf 0;
BA_ "GenSigStartValue" SG_ 160 ADataRawSafeAVertQf 1;
BA_ "GenSigDataID" SG_ 160 ADataRawSafeChks "0x22";
BA_ "GenSigFuncType" SG_ 160 ADataRawSafeChks 15;
BA_ "GenSigSendType" SG_ 160 ADataRawSafeChks 0;
BA_ "GenSigStartValue" SG_ 160 ADataRawSafeChks 255;
BA_ "GenSigFuncType" SG_ 160 ADataRawSafeCntr 16;
BA_ "GenSigSendType" SG_ 160 ADataRawSafeCntr 0;
BA_ "GenSigSendType" SG_ 185 ALgtStdFromWhlSpdALgtStdFromWhlSpd 0;
BA_ "GenSigDataID" SG_ 185 ALgtStdFromWhlSpdChks "0x34";
BA_ "GenSigFuncType" SG_ 185 ALgtStdFromWhlSpdChks 15;
BA_ "GenSigSendType" SG_ 185 ALgtStdFromWhlSpdChks 0;
BA_ "GenSigFuncType" SG_ 185 ALgtStdFromWhlSpdCntr 16;
BA_ "GenSigSendType" SG_ 185 ALgtStdFromWhlSpdCntr 0;
BA_ "GenSigSendType" SG_ 185 ALgtStdFromWhlSpdQf 0;
BA_ "GenSigStartValue" SG_ 185 ALgtStdFromWhlSpdQf 1;
BA_ "GenSigDataID" SG_ 400 AbsCtrlActvChks "0xD06";
BA_ "GenSigFuncType" SG_ 400 AbsCtrlActvChks 15;
BA_ "GenSigSendType" SG_ 400 AbsCtrlActvChks 0;
BA_ "GenSigFuncType" SG_ 400 AbsCtrlActvCntr 16;
BA_ "GenSigSendType" SG_ 400 AbsCtrlActvCntr 0;
BA_ "GenSigSendType" SG_ 400 AbsCtrlActvCtrlSts1 0;
BA_ "GenSigSendType" SG_ 686 AbsSts 0;
BA_ "GenSigSendType" SG_ 85 AccrPedlLnrAccrPedlRat 0;
BA_ "GenSigDataID" SG_ 85 AccrPedlLnrChks "0x2C3";
BA_ "GenSigFuncType" SG_ 85 AccrPedlLnrChks 15;
BA_ "GenSigSendType" SG_ 85 AccrPedlLnrChks 0;
BA_ "GenSigFuncType" SG_ 85 AccrPedlLnrCntr 16;
BA_ "GenSigSendType" SG_ 85 AccrPedlLnrCntr 0;
BA_ "GenSigSendType" SG_ 544 AccrPedlRatAccrPedlRat 0;
BA_ "GenSigDataID" SG_ 544 AccrPedlRatChks "0x364";
BA_ "GenSigFuncType" SG_ 544 AccrPedlRatChks 15;
BA_ "GenSigSendType" SG_ 544 AccrPedlRatChks 0;
BA_ "GenSigFuncType" SG_ 544 AccrPedlRatCntr 16;
BA_ "GenSigSendType" SG_ 544 AccrPedlRatCntr 0;
BA_ "GenSigSendType" SG_ 51 AgCtrlTqLowrLim 0;
BA_ "GenSigStartValue" SG_ 51 AgCtrlTqLowrLim 240;
BA_ "GenSigSendType" SG_ 51 AgCtrlTqUpprLim 0;
BA_ "GenSigStartValue" SG_ 51 AgCtrlTqUpprLim 240;
BA_ "GenSigSendType" SG_ 26 AgDataCmpQualityPitchRateCmpQuality 0;
BA_ "GenSigSendType" SG_ 26 AgDataCmpQualityRollRateCmpQuality 0;
BA_ "GenSigSendType" SG_ 26 AgDataCmpQualityYawRateCmpQuality 0;
BA_ "GenSigDataID" SG_ 85 AgDataRaw2SafeChks "0x404";
BA_ "GenSigFuncType" SG_ 85 AgDataRaw2SafeChks 15;
BA_ "GenSigSendType" SG_ 85 AgDataRaw2SafeChks 0;
BA_ "GenSigStartValue" SG_ 85 AgDataRaw2SafeChks 255;
BA_ "GenSigFuncType" SG_ 85 AgDataRaw2SafeCntr 16;
BA_ "GenSigSendType" SG_ 85 AgDataRaw2SafeCntr 0;
BA_ "GenSigSendType" SG_ 85 AgDataRaw2SafePitchRate 0;
BA_ "GenSigSendType" SG_ 85 AgDataRaw2SafePitchRateQf 0;
BA_ "GenSigStartValue" SG_ 85 AgDataRaw2SafePitchRateQf 1;
BA_ "GenSigDataID" SG_ 432 AgDataRawSafeChks "0x23";
BA_ "GenSigFuncType" SG_ 432 AgDataRawSafeChks 15;
BA_ "GenSigSendType" SG_ 432 AgDataRawSafeChks 0;
BA_ "GenSigStartValue" SG_ 432 AgDataRawSafeChks 255;
BA_ "GenSigFuncType" SG_ 432 AgDataRawSafeCntr 16;
BA_ "GenSigSendType" SG_ 432 AgDataRawSafeCntr 0;
BA_ "GenSigSendType" SG_ 432 AgDataRawSafeRollRate 0;
BA_ "GenSigSendType" SG_ 432 AgDataRawSafeRollRateQf 0;
BA_ "GenSigStartValue" SG_ 432 AgDataRawSafeRollRateQf 1;
BA_ "GenSigSendType" SG_ 432 AgDataRawSafeYawRate 0;
BA_ "GenSigSendType" SG_ 432 AgDataRawSafeYawRateQf 0;
BA_ "GenSigStartValue" SG_ 432 AgDataRawSafeYawRateQf 1;
BA_ "GenSigSendType" SG_ 928 AmbTIndcdWithUnitAmbTIndcd 0;
BA_ "GenSigStartValue" SG_ 928 AmbTIndcdWithUnitAmbTIndcd 1000;
BA_ "GenSigSendType" SG_ 928 AmbTIndcdWithUnitAmbTIndcdUnit 0;
BA_ "GenSigSendType" SG_ 928 AmbTIndcdWithUnitQF 0;
BA_ "GenSigSendType" SG_ 400 AmbTRawAmbTVal 0;
BA_ "GenSigStartValue" SG_ 400 AmbTRawAmbTVal 700;
BA_ "GenSigSendType" SG_ 400 AmbTRawQly 0;
BA_ "GenSigSendType" SG_ 147 AsyADL3FuncCtrlStsADMod 0;
BA_ "GenSigDataID" SG_ 147 AsyADL3FuncCtrlStsChks "0xD17";
BA_ "GenSigFuncType" SG_ 147 AsyADL3FuncCtrlStsChks 15;
BA_ "GenSigSendType" SG_ 147 AsyADL3FuncCtrlStsChks 0;
BA_ "GenSigFuncType" SG_ 147 AsyADL3FuncCtrlStsCntr 16;
BA_ "GenSigSendType" SG_ 147 AsyADL3FuncCtrlStsCntr 0;
BA_ "GenSigSendType" SG_ 147 AsyADL3FuncCtrlStsCtrlSts 0;
BA_ "GenSigSendType" SG_ 147 AsyADL3FuncCtrlStsDegraded 0;
BA_ "GenSigSendType" SG_ 147 AsyADL3FuncCtrlStsQf 0;
BA_ "GenSigSendType" SG_ 147 AsyADL3FuncCtrlStsSts 0;
BA_ "GenSigSendType" SG_ 147 AsyADModeReqADActiveReq 0;
BA_ "GenSigSendType" SG_ 147 AsyADModeReqADDeactiveReq 0;
BA_ "GenSigDataID" SG_ 147 AsyADModeReqChks "0xD18";
BA_ "GenSigFuncType" SG_ 147 AsyADModeReqChks 15;
BA_ "GenSigSendType" SG_ 147 AsyADModeReqChks 0;
BA_ "GenSigFuncType" SG_ 147 AsyADModeReqCntr 16;
BA_ "GenSigSendType" SG_ 147 AsyADModeReqCntr 0;
BA_ "GenSigSendType" SG_ 81 AsyDataWithCmpSafeALat1Qf 0;
BA_ "GenSigStartValue" SG_ 81 AsyDataWithCmpSafeALat1Qf 1;
BA_ "GenSigSendType" SG_ 81 AsyDataWithCmpSafeALatWithCmp 0;
BA_ "GenSigSendType" SG_ 81 AsyDataWithCmpSafeALgt1Qf 0;
BA_ "GenSigStartValue" SG_ 81 AsyDataWithCmpSafeALgt1Qf 1;
BA_ "GenSigDataID" SG_ 81 AsyDataWithCmpSafeChks "0x24";
BA_ "GenSigFuncType" SG_ 81 AsyDataWithCmpSafeChks 15;
BA_ "GenSigSendType" SG_ 81 AsyDataWithCmpSafeChks 0;
BA_ "GenSigStartValue" SG_ 81 AsyDataWithCmpSafeChks 255;
BA_ "GenSigFuncType" SG_ 81 AsyDataWithCmpSafeCntr 16;
BA_ "GenSigSendType" SG_ 81 AsyDataWithCmpSafeCntr 0;
BA_ "GenSigSendType" SG_ 81 AsyDataWithCmpSafeGrdtOfALgt 0;
BA_ "GenSigSendType" SG_ 81 AsyDataWithCmpSafeYawRateQf 0;
BA_ "GenSigStartValue" SG_ 81 AsyDataWithCmpSafeYawRateQf 1;
BA_ "GenSigSendType" SG_ 81 AsyDataWithCmpSafeYawRateWithCmp 0;
BA_ "GenSigSendType" SG_ 51 AsyPinionAgReqSafeAsyPinionAgReq 0;
BA_ "GenSigStartValue" SG_ 51 AsyPinionAgReqSafeAsyPinionAgReq 14848;
BA_ "GenSigDataID" SG_ 51 AsyPinionAgReqSafeAsyPinionAgReqChks "0x2F7";
BA_ "GenSigFuncType" SG_ 51 AsyPinionAgReqSafeAsyPinionAgReqChks 15;
BA_ "GenSigSendType" SG_ 51 AsyPinionAgReqSafeAsyPinionAgReqChks 0;
BA_ "GenSigFuncType" SG_ 51 AsyPinionAgReqSafeAsyPinionAgReqCntr 16;
BA_ "GenSigSendType" SG_ 51 AsyPinionAgReqSafeAsyPinionAgReqCntr 0;
BA_ "GenSigSendType" SG_ 496 BkpOfDstTrvld 0;
BA_ "GenSigSendType" SG_ 66 BrkBstStsSec 0;
BA_ "GenSigSendType" SG_ 129 BrkFActAutParkBrkSpprtReq 0;
BA_ "GenSigDataID" SG_ 129 BrkFActChks "0x42C";
BA_ "GenSigFuncType" SG_ 129 BrkFActChks 15;
BA_ "GenSigSendType" SG_ 129 BrkFActChks 0;
BA_ "GenSigFuncType" SG_ 129 BrkFActCntr 16;
BA_ "GenSigSendType" SG_ 129 BrkFActCntr 0;
BA_ "GenSigSendType" SG_ 129 BrkFActForce 0;
BA_ "GenSigDataID" SG_ 545 BrkLiOnReqForBkpBrkLiOnReqChks "0x1966";
BA_ "GenSigFuncType" SG_ 545 BrkLiOnReqForBkpBrkLiOnReqChks 15;
BA_ "GenSigSendType" SG_ 545 BrkLiOnReqForBkpBrkLiOnReqChks 0;
BA_ "GenSigFuncType" SG_ 545 BrkLiOnReqForBkpBrkLiOnReqCntr 16;
BA_ "GenSigSendType" SG_ 545 BrkLiOnReqForBkpBrkLiOnReqCntr 0;
BA_ "GenSigSendType" SG_ 545 BrkLiOnReqForBkpBrkLiOnReqSts 0;
BA_ "GenSigSendType" SG_ 433 BrkPedlPsdBrkPedlNotPsdSafe 0;
BA_ "GenSigSendType" SG_ 433 BrkPedlPsdBrkPedlPsd 0;
BA_ "GenSigDataID" SG_ 433 BrkPedlPsdChks "0x38";
BA_ "GenSigFuncType" SG_ 433 BrkPedlPsdChks 15;
BA_ "GenSigSendType" SG_ 433 BrkPedlPsdChks 0;
BA_ "GenSigFuncType" SG_ 433 BrkPedlPsdCntr 16;
BA_ "GenSigSendType" SG_ 433 BrkPedlPsdCntr 0;
BA_ "GenSigSendType" SG_ 433 BrkPedlPsdQf 0;
BA_ "GenSigSendType" SG_ 1099 BrkTracCtrlActv 0;
BA_ "GenSigDataID" SG_ 308 BrkWssInfoFrntChks "0x1F4";
BA_ "GenSigFuncType" SG_ 308 BrkWssInfoFrntChks 15;
BA_ "GenSigSendType" SG_ 308 BrkWssInfoFrntChks 0;
BA_ "GenSigFuncType" SG_ 308 BrkWssInfoFrntCntr 16;
BA_ "GenSigSendType" SG_ 308 BrkWssInfoFrntCntr 0;
BA_ "GenSigSendType" SG_ 308 BrkWssInfoFrntTTCFactorFL 0;
BA_ "GenSigStartValue" SG_ 308 BrkWssInfoFrntTTCFactorFL 32751.0917031;
BA_ "GenSigSendType" SG_ 308 BrkWssInfoFrntTTCFactorFR 0;
BA_ "GenSigStartValue" SG_ 308 BrkWssInfoFrntTTCFactorFR 32751.0917031;
BA_ "GenSigSendType" SG_ 308 BrkWssInfoFrntWssCoreMonRob 0;
BA_ "GenSigDataID" SG_ 327 BrkWssInfoReChks "0x1F5";
BA_ "GenSigFuncType" SG_ 327 BrkWssInfoReChks 15;
BA_ "GenSigSendType" SG_ 327 BrkWssInfoReChks 0;
BA_ "GenSigFuncType" SG_ 327 BrkWssInfoReCntr 16;
BA_ "GenSigSendType" SG_ 327 BrkWssInfoReCntr 0;
BA_ "GenSigSendType" SG_ 327 BrkWssInfoReTTCFactorRL 0;
BA_ "GenSigStartValue" SG_ 327 BrkWssInfoReTTCFactorRL 32751.0917031;
BA_ "GenSigSendType" SG_ 327 BrkWssInfoReTTCFactorRR 0;
BA_ "GenSigStartValue" SG_ 327 BrkWssInfoReTTCFactorRR 32751.0917031;
BA_ "GenSigSendType" SG_ 864 CarTiGlb 0;
BA_ "GenSigSendType" SG_ 784 CmptmtTFrntCmptmtTFrnt 0;
BA_ "GenSigStartValue" SG_ 784 CmptmtTFrntCmptmtTFrnt 600;
BA_ "GenSigSendType" SG_ 784 CmptmtTFrntFanForCmptmtTRunng 0;
BA_ "GenSigSendType" SG_ 784 CmptmtTFrntQf 0;
BA_ "GenSigStartValue" SG_ 784 CmptmtTFrntQf 1;
BA_ "GenSigSendType" SG_ 686 DrvModReq 0;
BA_ "GenSigSendType" SG_ 496 DrvModReqForChampnMod 0;
BA_ "GenSigSendType" SG_ 134 DrvgCyc 0;
BA_ "GenSigSendType" SG_ 752 DrvrGearLvrInfoIndcn 0;
BA_ "GenSigDataID" SG_ 246 DrvrSteerActvChks "0xBC";
BA_ "GenSigFuncType" SG_ 246 DrvrSteerActvChks 15;
BA_ "GenSigSendType" SG_ 246 DrvrSteerActvChks 0;
BA_ "GenSigFuncType" SG_ 246 DrvrSteerActvCntr 16;
BA_ "GenSigSendType" SG_ 246 DrvrSteerActvCntr 0;
BA_ "GenSigSendType" SG_ 246 DrvrSteerActvDrvrSteerActv 0;
BA_ "GenSigSendType" SG_ 444 DrvrSteerWhlHldGroupDrvrSteerWhlHld 0;
BA_ "GenSigSendType" SG_ 444 DrvrSteerWhlHldGroupDrvrSteerWhlHldQly 0;
BA_ "GenSigSendType" SG_ 66 EBDiagActive 0;
BA_ "GenSigSendType" SG_ 121 EngPAmbAir 0;
BA_ "GenSigSendType" SG_ 752 EngSt1WdSts1 0;
BA_ "GenSigDataID" SG_ 131 EngSt1WdStsChks "0x89";
BA_ "GenSigFuncType" SG_ 131 EngSt1WdStsChks 15;
BA_ "GenSigSendType" SG_ 131 EngSt1WdStsChks 0;
BA_ "GenSigFuncType" SG_ 131 EngSt1WdStsCntr 16;
BA_ "GenSigSendType" SG_ 131 EngSt1WdStsCntr 0;
BA_ "GenSigSendType" SG_ 131 EngSt1WdStsEngSt1WdSts 0;
BA_ "GenSigSendType" SG_ 265 EpbAvlPrimApplyFunctionalitiesAvailable 0;
BA_ "GenSigDataID" SG_ 265 EpbAvlPrimChks "0x465";
BA_ "GenSigFuncType" SG_ 265 EpbAvlPrimChks 15;
BA_ "GenSigSendType" SG_ 265 EpbAvlPrimChks 0;
BA_ "GenSigFuncType" SG_ 265 EpbAvlPrimCntr 16;
BA_ "GenSigSendType" SG_ 265 EpbAvlPrimCntr 0;
BA_ "GenSigSendType" SG_ 265 EpbAvlPrimDriveAwayIntention 0;
BA_ "GenSigSendType" SG_ 265 EpbAvlPrimHostAvailabilityFull 0;
BA_ "GenSigSendType" SG_ 265 EpbAvlPrimHostAvailabilityRelOnly 0;
BA_ "GenSigSendType" SG_ 265 EpbAvlPrimPrimarySystemAvailable 0;
BA_ "GenSigSendType" SG_ 265 EpbAvlPrimReserved1 0;
BA_ "GenSigSendType" SG_ 265 EpbAvlPrimReserved2 0;
BA_ "GenSigSendType" SG_ 265 EpbAvlPrimReserved3 0;
BA_ "GenSigSendType" SG_ 265 EpbAvlPrimReserved4 0;
BA_ "GenSigSendType" SG_ 265 EpbAvlPrimRollerTestBench 0;
BA_ "GenSigDataID" SG_ 327 EpbStsChks "0x84";
BA_ "GenSigFuncType" SG_ 327 EpbStsChks 15;
BA_ "GenSigSendType" SG_ 327 EpbStsChks 0;
BA_ "GenSigFuncType" SG_ 327 EpbStsCntr 16;
BA_ "GenSigSendType" SG_ 327 EpbStsCntr 0;
BA_ "GenSigSendType" SG_ 327 EpbStsEpbSts 0;
BA_ "GenSigDataID" SG_ 1267 EscStChks "0x7F";
BA_ "GenSigFuncType" SG_ 1267 EscStChks 15;
BA_ "GenSigSendType" SG_ 1267 EscStChks 0;
BA_ "GenSigFuncType" SG_ 1267 EscStCntr 16;
BA_ "GenSigSendType" SG_ 1267 EscStCntr 0;
BA_ "GenSigSendType" SG_ 1267 EscStEscSt 0;
BA_ "GenSigStartValue" SG_ 1267 EscStEscSt 1;
BA_ "GenSigSendType" SG_ 246 FrntSteerFEstimd1 0;
BA_ "GenSigSendType" SG_ 137 HsaSt 0;
BA_ "GenSigStartValue" SG_ 137 HsaSt 1;
BA_ "GenSigDataID" SG_ 580 IDcDcActLoSideChks "0x14";
BA_ "GenSigFuncType" SG_ 580 IDcDcActLoSideChks 15;
BA_ "GenSigSendType" SG_ 580 IDcDcActLoSideChks 0;
BA_ "GenSigFuncType" SG_ 580 IDcDcActLoSideCntr 16;
BA_ "GenSigSendType" SG_ 580 IDcDcActLoSideCntr 0;
BA_ "GenSigSendType" SG_ 580 IDcDcActLoSideIDcDcActLoSide 0;
BA_ "GenSigDataID" SG_ 70 LatCtrlModCfmdChks "0x3A";
BA_ "GenSigFuncType" SG_ 70 LatCtrlModCfmdChks 15;
BA_ "GenSigSendType" SG_ 70 LatCtrlModCfmdChks 0;
BA_ "GenSigFuncType" SG_ 70 LatCtrlModCfmdCntr 16;
BA_ "GenSigSendType" SG_ 70 LatCtrlModCfmdCntr 0;
BA_ "GenSigSendType" SG_ 70 LatCtrlModCfmdLatCtrlMod 0;
BA_ "GenSigDataID" SG_ 400 LatCtrlReqSafeChks "0x30";
BA_ "GenSigFuncType" SG_ 400 LatCtrlReqSafeChks 15;
BA_ "GenSigSendType" SG_ 400 LatCtrlReqSafeChks 0;
BA_ "GenSigFuncType" SG_ 400 LatCtrlReqSafeCntr 16;
BA_ "GenSigSendType" SG_ 400 LatCtrlReqSafeCntr 0;
BA_ "GenSigSendType" SG_ 400 LatCtrlReqSafeLatCtrlModReq 0;
BA_ "GenSigSendType" SG_ 400 LatCtrlReqSafeSteerTqReq 0;
BA_ "GenSigSendType" SG_ 400 LatCtrlReqSafeSteerWhlHptcWarnReq 0;
BA_ "GenSigSendType" SG_ 147 PASFuncActive 0;
BA_ "GenSigSendType" SG_ 1431 PSCMdevelpsignalgroupreq1Functiondevpsignalgroup1 1;
BA_ "GenSigSendType" SG_ 1431 PSCMdevelpsignalgroupreq1Functiondevpsignalgroup2 1;
BA_ "GenSigSendType" SG_ 1431 PSCMdevelpsignalgroupreq1Functiondevpsignalgroup3 1;
BA_ "GenSigSendType" SG_ 1431 PSCMdevelpsignalgroupreq1Functiondevpsignalgroup4 1;
BA_ "GenSigSendType" SG_ 1431 PSCMdevelpsignalgroupreq1Functiondevpsignalgroup5 1;
BA_ "GenSigSendType" SG_ 1431 PSCMdevelpsignalgroupreq1Functiondevpsignalgroup6 1;
BA_ "GenSigSendType" SG_ 1431 PSCMdevelpsignalgroupreq1Functiondevpsignalgroup7 1;
BA_ "GenSigSendType" SG_ 1431 PSCMdevelpsignalgroupreq1Functiondevpsignalgroup8 1;
BA_ "GenSigSendType" SG_ 1430 PSCMdevelpsignalgroupresp1Functiondevpsignalgroup1 1;
BA_ "GenSigSendType" SG_ 1430 PSCMdevelpsignalgroupresp1Functiondevpsignalgroup2 1;
BA_ "GenSigSendType" SG_ 1430 PSCMdevelpsignalgroupresp1Functiondevpsignalgroup3 1;
BA_ "GenSigSendType" SG_ 1430 PSCMdevelpsignalgroupresp1Functiondevpsignalgroup4 1;
BA_ "GenSigSendType" SG_ 1430 PSCMdevelpsignalgroupresp1Functiondevpsignalgroup5 1;
BA_ "GenSigSendType" SG_ 1430 PSCMdevelpsignalgroupresp1Functiondevpsignalgroup6 1;
BA_ "GenSigSendType" SG_ 1430 PSCMdevelpsignalgroupresp1Functiondevpsignalgroup7 1;
BA_ "GenSigSendType" SG_ 1430 PSCMdevelpsignalgroupresp1Functiondevpsignalgroup8 1;
BA_ "GenSigDataID" SG_ 78 PinionSteerAgGroupChks "0x40D";
BA_ "GenSigFuncType" SG_ 78 PinionSteerAgGroupChks 15;
BA_ "GenSigSendType" SG_ 78 PinionSteerAgGroupChks 0;
BA_ "GenSigFuncType" SG_ 78 PinionSteerAgGroupCntr 16;
BA_ "GenSigSendType" SG_ 78 PinionSteerAgGroupCntr 0;
BA_ "GenSigSendType" SG_ 78 PinionSteerAgGroupPinionSteerAg1 0;
BA_ "GenSigSendType" SG_ 78 PinionSteerAgGroupPinionSteerAg1Qf 0;
BA_ "GenSigStartValue" SG_ 78 PinionSteerAgGroupPinionSteerAg1Qf 1;
BA_ "GenSigSendType" SG_ 78 PinionSteerAgGroupPinionSteerAgSpd1 0;
BA_ "GenSigSendType" SG_ 78 PinionSteerAgGroupPinionSteerAgSpd1Qf 0;
BA_ "GenSigStartValue" SG_ 78 PinionSteerAgGroupPinionSteerAgSpd1Qf 1;
BA_ "GenSigSendType" SG_ 78 PinionSteerAgGroupSteerWhlTq 0;
BA_ "GenSigSendType" SG_ 78 PinionSteerAgGroupSteerWhlTqQf 0;
BA_ "GenSigStartValue" SG_ 78 PinionSteerAgGroupSteerWhlTqQf 1;
BA_ "GenSigSendType" SG_ 955 PinionSteerAgMax1 0;
BA_ "GenSigSendType" SG_ 265 PrimBrkSysStBrkSysSt 0;
BA_ "GenSigDataID" SG_ 265 PrimBrkSysStChks "0x42E";
BA_ "GenSigFuncType" SG_ 265 PrimBrkSysStChks 15;
BA_ "GenSigSendType" SG_ 265 PrimBrkSysStChks 0;
BA_ "GenSigFuncType" SG_ 265 PrimBrkSysStCntr 16;
BA_ "GenSigSendType" SG_ 265 PrimBrkSysStCntr 0;
BA_ "GenSigDataID" SG_ 149 PrkgGearReqGroupChks "0x29D";
BA_ "GenSigFuncType" SG_ 149 PrkgGearReqGroupChks 15;
BA_ "GenSigSendType" SG_ 149 PrkgGearReqGroupChks 1;
BA_ "GenSigFuncType" SG_ 149 PrkgGearReqGroupCntr 16;
BA_ "GenSigSendType" SG_ 149 PrkgGearReqGroupCntr 1;
BA_ "GenSigSendType" SG_ 149 PrkgGearReqGroupReqSts1 1;
BA_ "GenSigSendType" SG_ 235 PrkgPinionAgReqGroupParkAssiPinionAgReq 0;
BA_ "GenSigStartValue" SG_ 235 PrkgPinionAgReqGroupParkAssiPinionAgReq 14847.9923978;
BA_ "GenSigDataID" SG_ 235 PrkgPinionAgReqGroupParkAssiPinionAgReqChks "0x1B1";
BA_ "GenSigFuncType" SG_ 235 PrkgPinionAgReqGroupParkAssiPinionAgReqChks 15;
BA_ "GenSigSendType" SG_ 235 PrkgPinionAgReqGroupParkAssiPinionAgReqChks 0;
BA_ "GenSigFuncType" SG_ 235 PrkgPinionAgReqGroupParkAssiPinionAgReqCntr 16;
BA_ "GenSigSendType" SG_ 235 PrkgPinionAgReqGroupParkAssiPinionAgReqCntr 0;
BA_ "GenSigSendType" SG_ 235 PrkgPinionAgReqGroupQF 0;
BA_ "GenSigStartValue" SG_ 235 PrkgPinionAgReqGroupQF 1;
BA_ "GenSigSendType" SG_ 864 ProfPenSts1 0;
BA_ "GenSigSendType" SG_ 54 PrpsnTqReReq 0;
BA_ "GenSigDataID" SG_ 1111 PtTqAtWhlFrntActChks "0x4E";
BA_ "GenSigFuncType" SG_ 1111 PtTqAtWhlFrntActChks 15;
BA_ "GenSigSendType" SG_ 1111 PtTqAtWhlFrntActChks 0;
BA_ "GenSigFuncType" SG_ 1111 PtTqAtWhlFrntActCntr 16;
BA_ "GenSigSendType" SG_ 1111 PtTqAtWhlFrntActCntr 0;
BA_ "GenSigSendType" SG_ 1111 PtTqAtWhlFrntActPtTqAtAxleFrntAct 0;
BA_ "GenSigSendType" SG_ 1111 PtTqAtWhlFrntActPtTqAtWhlFrntLeAct 0;
BA_ "GenSigSendType" SG_ 1111 PtTqAtWhlFrntActPtTqAtWhlFrntRiAct 0;
BA_ "GenSigSendType" SG_ 1111 PtTqAtWhlFrntActPtTqAtWhlsFrntQly 0;
BA_ "GenSigSendType" SG_ 1504 RBCMdevelpsignalgroupreq1Functiondevpsignalgroup1 1;
BA_ "GenSigSendType" SG_ 1504 RBCMdevelpsignalgroupreq1Functiondevpsignalgroup2 1;
BA_ "GenSigSendType" SG_ 1504 RBCMdevelpsignalgroupreq1Functiondevpsignalgroup3 1;
BA_ "GenSigSendType" SG_ 1504 RBCMdevelpsignalgroupreq1Functiondevpsignalgroup4 1;
BA_ "GenSigSendType" SG_ 1504 RBCMdevelpsignalgroupreq1Functiondevpsignalgroup5 1;
BA_ "GenSigSendType" SG_ 1504 RBCMdevelpsignalgroupreq1Functiondevpsignalgroup6 1;
BA_ "GenSigSendType" SG_ 1504 RBCMdevelpsignalgroupreq1Functiondevpsignalgroup7 1;
BA_ "GenSigSendType" SG_ 1504 RBCMdevelpsignalgroupreq1Functiondevpsignalgroup8 1;
BA_ "GenSigSendType" SG_ 129 RbuCtrlModReqSafeBrkSysModCfmd 0;
BA_ "GenSigDataID" SG_ 129 RbuCtrlModReqSafeChks "0x428";
BA_ "GenSigFuncType" SG_ 129 RbuCtrlModReqSafeChks 15;
BA_ "GenSigSendType" SG_ 129 RbuCtrlModReqSafeChks 0;
BA_ "GenSigFuncType" SG_ 129 RbuCtrlModReqSafeCntr 16;
BA_ "GenSigSendType" SG_ 129 RbuCtrlModReqSafeCntr 0;
BA_ "GenSigSendType" SG_ 147 RctaBrkReqQM 0;
BA_ "GenSigSendType" SG_ 147 RcwmBrkReqQM 0;
BA_ "GenSigSendType" SG_ 375 RlyPwrDistbnCmd1WdIgnRlyCmd 0;
BA_ "GenSigSendType" SG_ 84 SBMHealthChkCmd 0;
BA_ "GenSigSendType" SG_ 66 SBMHealthChkResp 0;
BA_ "GenSigSendType" SG_ 864 SaveSetgToMemPrmnt 0;
BA_ "GenSigSendType" SG_ 289 SecBrkSysStBrkSysSt 0;
BA_ "GenSigDataID" SG_ 289 SecBrkSysStChks "0x370";
BA_ "GenSigFuncType" SG_ 289 SecBrkSysStChks 15;
BA_ "GenSigSendType" SG_ 289 SecBrkSysStChks 0;
BA_ "GenSigFuncType" SG_ 289 SecBrkSysStCntr 16;
BA_ "GenSigSendType" SG_ 289 SecBrkSysStCntr 0;
BA_ "GenSigSendType" SG_ 274 SecParkBrkSysSt2BrkSysSt 0;
BA_ "GenSigDataID" SG_ 274 SecParkBrkSysSt2Chks "0x1989";
BA_ "GenSigFuncType" SG_ 274 SecParkBrkSysSt2Chks 15;
BA_ "GenSigSendType" SG_ 274 SecParkBrkSysSt2Chks 0;
BA_ "GenSigFuncType" SG_ 274 SecParkBrkSysSt2Cntr 16;
BA_ "GenSigSendType" SG_ 274 SecParkBrkSysSt2Cntr 0;
BA_ "GenSigSendType" SG_ 185 SlipRatWithinRngForReWhls 0;
BA_ "GenSigStartValue" SG_ 185 SlipRatWithinRngForReWhls 1;
BA_ "GenSigSendType" SG_ 444 SteerErrReq 0;
BA_ "GenSigStartValue" SG_ 444 SteerErrReq 1;
BA_ "GenSigDataID" SG_ 444 SteerExtFctStsChks "0x406";
BA_ "GenSigFuncType" SG_ 444 SteerExtFctStsChks 15;
BA_ "GenSigSendType" SG_ 444 SteerExtFctStsChks 0;
BA_ "GenSigFuncType" SG_ 444 SteerExtFctStsCntr 16;
BA_ "GenSigSendType" SG_ 444 SteerExtFctStsCntr 0;
BA_ "GenSigSendType" SG_ 444 SteerExtFctStsDrvrSteerOvrd 0;
BA_ "GenSigSendType" SG_ 444 SteerExtFctStsExtFctLowerLimActive 0;
BA_ "GenSigSendType" SG_ 444 SteerExtFctStsExtFctRateLimActive 0;
BA_ "GenSigSendType" SG_ 444 SteerExtFctStsExtFctUpperLimActive 0;
BA_ "GenSigSendType" SG_ 444 SteerExtFctStsExtSafeLimActive 0;
BA_ "GenSigSendType" SG_ 444 SteerExtFctStsLatAgReqNotInRange 0;
BA_ "GenSigSendType" SG_ 444 SteerExtFctStsLatCtrlReqNotInRange 0;
BA_ "GenSigSendType" SG_ 84 SteerReCtrlReqAgReq 0;
BA_ "GenSigSendType" SG_ 84 SteerReCtrlReqAqRecQf 0;
BA_ "GenSigDataID" SG_ 84 SteerReCtrlReqChks "0x1979";
BA_ "GenSigFuncType" SG_ 84 SteerReCtrlReqChks 15;
BA_ "GenSigSendType" SG_ 84 SteerReCtrlReqChks 0;
BA_ "GenSigFuncType" SG_ 84 SteerReCtrlReqCntr 16;
BA_ "GenSigSendType" SG_ 84 SteerReCtrlReqCntr 0;
BA_ "GenSigSendType" SG_ 84 SteerReCtrlReqSteerReCtrlSts 0;
BA_ "GenSigSendType" SG_ 70 SteerServoSts 0;
BA_ "GenSigSendType" SG_ 1123 SteerSetgPen 0;
BA_ "GenSigSendType" SG_ 1123 SteerSetgSteerAsscLvl 0;
BA_ "GenSigSendType" SG_ 1123 SteerSetgSteerMod 0;
BA_ "GenSigSendType" SG_ 70 SteerSftyLimrSts 0;
BA_ "GenSigSendType" SG_ 444 SteerStsToParkAssi 0;
BA_ "GenSigSendType" SG_ 64 SteerWhlSnsrAg 0;
BA_ "GenSigSendType" SG_ 64 SteerWhlSnsrAgSpd 0;
BA_ "GenSigDataID" SG_ 64 SteerWhlSnsrChks "0x33";
BA_ "GenSigFuncType" SG_ 64 SteerWhlSnsrChks 15;
BA_ "GenSigSendType" SG_ 64 SteerWhlSnsrChks 0;
BA_ "GenSigFuncType" SG_ 64 SteerWhlSnsrCntr 16;
BA_ "GenSigSendType" SG_ 64 SteerWhlSnsrCntr 0;
BA_ "GenSigSendType" SG_ 64 SteerWhlSnsrQf 0;
BA_ "GenSigStartValue" SG_ 64 SteerWhlSnsrQf 1;
BA_ "GenSigSendType" SG_ 70 SteerWhlTqAddl 0;
BA_ "GenSigSendType" SG_ 342 TiAndDateIndcnDataValid 0;
BA_ "GenSigSendType" SG_ 342 TiAndDateIndcnDay 0;
BA_ "GenSigStartValue" SG_ 342 TiAndDateIndcnDay 1;
BA_ "GenSigSendType" SG_ 342 TiAndDateIndcnHr1 0;
BA_ "GenSigSendType" SG_ 342 TiAndDateIndcnMins1 0;
BA_ "GenSigSendType" SG_ 342 TiAndDateIndcnMth1 0;
BA_ "GenSigStartValue" SG_ 342 TiAndDateIndcnMth1 1;
BA_ "GenSigSendType" SG_ 342 TiAndDateIndcnSec1 0;
BA_ "GenSigSendType" SG_ 342 TiAndDateIndcnYr1 0;
BA_ "GenSigSendType" SG_ 70 TqAssAddl 0;
BA_ "GenSigSendType" SG_ 246 UBoostReqBySteerFrnt 0;
BA_ "GenSigDataID" SG_ 686 ULoWarnChks "0x43";
BA_ "GenSigFuncType" SG_ 686 ULoWarnChks 15;
BA_ "GenSigSendType" SG_ 686 ULoWarnChks 0;
BA_ "GenSigFuncType" SG_ 686 ULoWarnCntr 16;
BA_ "GenSigSendType" SG_ 686 ULoWarnCntr 0;
BA_ "GenSigSendType" SG_ 686 ULoWarnULoWarn 0;
BA_ "GenSigSendType" SG_ 235 UturnTrqRelsChks 0;
BA_ "GenSigSendType" SG_ 235 UturnTrqRelsCntr 0;
BA_ "GenSigSendType" SG_ 235 UturnTrqRelsUturnTrqRels 0;
BA_ "GenSigSendType" SG_ 1432 VDDMdevelpsignalgroupreq1Functiondevpsignalgroup1 1;
BA_ "GenSigSendType" SG_ 1432 VDDMdevelpsignalgroupreq1Functiondevpsignalgroup2 1;
BA_ "GenSigSendType" SG_ 1432 VDDMdevelpsignalgroupreq1Functiondevpsignalgroup3 1;
BA_ "GenSigSendType" SG_ 1432 VDDMdevelpsignalgroupreq1Functiondevpsignalgroup4 1;
BA_ "GenSigSendType" SG_ 1432 VDDMdevelpsignalgroupreq1Functiondevpsignalgroup5 1;
BA_ "GenSigSendType" SG_ 1432 VDDMdevelpsignalgroupreq1Functiondevpsignalgroup6 1;
BA_ "GenSigSendType" SG_ 1432 VDDMdevelpsignalgroupreq1Functiondevpsignalgroup7 1;
BA_ "GenSigSendType" SG_ 1432 VDDMdevelpsignalgroupreq1Functiondevpsignalgroup8 1;
BA_ "GenSigSendType" SG_ 1433 VDDMdevelpsignalgroupreq2Functiondevpsignalgroup1 1;
BA_ "GenSigSendType" SG_ 1433 VDDMdevelpsignalgroupreq2Functiondevpsignalgroup2 1;
BA_ "GenSigSendType" SG_ 1433 VDDMdevelpsignalgroupreq2Functiondevpsignalgroup3 1;
BA_ "GenSigSendType" SG_ 1433 VDDMdevelpsignalgroupreq2Functiondevpsignalgroup4 1;
BA_ "GenSigSendType" SG_ 1433 VDDMdevelpsignalgroupreq2Functiondevpsignalgroup5 1;
BA_ "GenSigSendType" SG_ 1433 VDDMdevelpsignalgroupreq2Functiondevpsignalgroup6 1;
BA_ "GenSigSendType" SG_ 1433 VDDMdevelpsignalgroupreq2Functiondevpsignalgroup7 1;
BA_ "GenSigSendType" SG_ 1433 VDDMdevelpsignalgroupreq2Functiondevpsignalgroup8 1;
BA_ "GenSigSendType" SG_ 1434 VDDMdevelpsignalgroupresp1Functiondevpsignalgroup1 1;
BA_ "GenSigSendType" SG_ 1434 VDDMdevelpsignalgroupresp1Functiondevpsignalgroup2 1;
BA_ "GenSigSendType" SG_ 1434 VDDMdevelpsignalgroupresp1Functiondevpsignalgroup3 1;
BA_ "GenSigSendType" SG_ 1434 VDDMdevelpsignalgroupresp1Functiondevpsignalgroup4 1;
BA_ "GenSigSendType" SG_ 1434 VDDMdevelpsignalgroupresp1Functiondevpsignalgroup5 1;
BA_ "GenSigSendType" SG_ 1434 VDDMdevelpsignalgroupresp1Functiondevpsignalgroup6 1;
BA_ "GenSigSendType" SG_ 1434 VDDMdevelpsignalgroupresp1Functiondevpsignalgroup7 1;
BA_ "GenSigSendType" SG_ 1434 VDDMdevelpsignalgroupresp1Functiondevpsignalgroup8 1;
BA_ "GenSigSendType" SG_ 1435 VDDMdevelpsignalgroupresp2Functiondevpsignalgroup1 1;
BA_ "GenSigSendType" SG_ 1435 VDDMdevelpsignalgroupresp2Functiondevpsignalgroup2 1;
BA_ "GenSigSendType" SG_ 1435 VDDMdevelpsignalgroupresp2Functiondevpsignalgroup3 1;
BA_ "GenSigSendType" SG_ 1435 VDDMdevelpsignalgroupresp2Functiondevpsignalgroup4 1;
BA_ "GenSigSendType" SG_ 1435 VDDMdevelpsignalgroupresp2Functiondevpsignalgroup5 1;
BA_ "GenSigSendType" SG_ 1435 VDDMdevelpsignalgroupresp2Functiondevpsignalgroup6 1;
BA_ "GenSigSendType" SG_ 1435 VDDMdevelpsignalgroupresp2Functiondevpsignalgroup7 1;
BA_ "GenSigSendType" SG_ 1435 VDDMdevelpsignalgroupresp2Functiondevpsignalgroup8 1;
BA_ "GenSigSendType" SG_ 38 VFCInfoEna 1;
BA_ "GenSigSendType" SG_ 1383 VFCVectorRBCMBlockID 1;
BA_ "GenSigSendType" SG_ 1383 VFCVectorRBCMVFCid0 1;
BA_ "GenSigSendType" SG_ 1383 VFCVectorRBCMVFCid1 1;
BA_ "GenSigSendType" SG_ 1383 VFCVectorRBCMVFCid10 1;
BA_ "GenSigSendType" SG_ 1383 VFCVectorRBCMVFCid11 1;
BA_ "GenSigSendType" SG_ 1383 VFCVectorRBCMVFCid12 1;
BA_ "GenSigSendType" SG_ 1383 VFCVectorRBCMVFCid13 1;
BA_ "GenSigSendType" SG_ 1383 VFCVectorRBCMVFCid14 1;
BA_ "GenSigSendType" SG_ 1383 VFCVectorRBCMVFCid15 1;
BA_ "GenSigSendType" SG_ 1383 VFCVectorRBCMVFCid16 1;
BA_ "GenSigSendType" SG_ 1383 VFCVectorRBCMVFCid17 1;
BA_ "GenSigSendType" SG_ 1383 VFCVectorRBCMVFCid18 1;
BA_ "GenSigSendType" SG_ 1383 VFCVectorRBCMVFCid19 1;
BA_ "GenSigSendType" SG_ 1383 VFCVectorRBCMVFCid2 1;
BA_ "GenSigSendType" SG_ 1383 VFCVectorRBCMVFCid20 1;
BA_ "GenSigSendType" SG_ 1383 VFCVectorRBCMVFCid21 1;
BA_ "GenSigSendType" SG_ 1383 VFCVectorRBCMVFCid22 1;
BA_ "GenSigSendType" SG_ 1383 VFCVectorRBCMVFCid23 1;
BA_ "GenSigSendType" SG_ 1383 VFCVectorRBCMVFCid24 1;
BA_ "GenSigSendType" SG_ 1383 VFCVectorRBCMVFCid25 1;
BA_ "GenSigSendType" SG_ 1383 VFCVectorRBCMVFCid26 1;
BA_ "GenSigSendType" SG_ 1383 VFCVectorRBCMVFCid27 1;
BA_ "GenSigSendType" SG_ 1383 VFCVectorRBCMVFCid28 1;
BA_ "GenSigSendType" SG_ 1383 VFCVectorRBCMVFCid29 1;
BA_ "GenSigSendType" SG_ 1383 VFCVectorRBCMVFCid3 1;
BA_ "GenSigSendType" SG_ 1383 VFCVectorRBCMVFCid30 1;
BA_ "GenSigSendType" SG_ 1383 VFCVectorRBCMVFCid31 1;
BA_ "GenSigSendType" SG_ 1383 VFCVectorRBCMVFCid32 1;
BA_ "GenSigSendType" SG_ 1383 VFCVectorRBCMVFCid33 1;
BA_ "GenSigSendType" SG_ 1383 VFCVectorRBCMVFCid34 1;
BA_ "GenSigSendType" SG_ 1383 VFCVectorRBCMVFCid35 1;
BA_ "GenSigSendType" SG_ 1383 VFCVectorRBCMVFCid36 1;
BA_ "GenSigSendType" SG_ 1383 VFCVectorRBCMVFCid37 1;
BA_ "GenSigSendType" SG_ 1383 VFCVectorRBCMVFCid38 1;
BA_ "GenSigSendType" SG_ 1383 VFCVectorRBCMVFCid39 1;
BA_ "GenSigSendType" SG_ 1383 VFCVectorRBCMVFCid4 1;
BA_ "GenSigSendType" SG_ 1383 VFCVectorRBCMVFCid40 1;
BA_ "GenSigSendType" SG_ 1383 VFCVectorRBCMVFCid41 1;
BA_ "GenSigSendType" SG_ 1383 VFCVectorRBCMVFCid42 1;
BA_ "GenSigSendType" SG_ 1383 VFCVectorRBCMVFCid43 1;
BA_ "GenSigSendType" SG_ 1383 VFCVectorRBCMVFCid44 1;
BA_ "GenSigSendType" SG_ 1383 VFCVectorRBCMVFCid45 1;
BA_ "GenSigSendType" SG_ 1383 VFCVectorRBCMVFCid46 1;
BA_ "GenSigSendType" SG_ 1383 VFCVectorRBCMVFCid47 1;
BA_ "GenSigSendType" SG_ 1383 VFCVectorRBCMVFCid48 1;
BA_ "GenSigSendType" SG_ 1383 VFCVectorRBCMVFCid49 1;
BA_ "GenSigSendType" SG_ 1383 VFCVectorRBCMVFCid5 1;
BA_ "GenSigSendType" SG_ 1383 VFCVectorRBCMVFCid50 1;
BA_ "GenSigSendType" SG_ 1383 VFCVectorRBCMVFCid51 1;
BA_ "GenSigSendType" SG_ 1383 VFCVectorRBCMVFCid52 1;
BA_ "GenSigSendType" SG_ 1383 VFCVectorRBCMVFCid53 1;
BA_ "GenSigSendType" SG_ 1383 VFCVectorRBCMVFCid54 1;
BA_ "GenSigSendType" SG_ 1383 VFCVectorRBCMVFCid55 1;
BA_ "GenSigSendType" SG_ 1383 VFCVectorRBCMVFCid56 1;
BA_ "GenSigSendType" SG_ 1383 VFCVectorRBCMVFCid57 1;
BA_ "GenSigSendType" SG_ 1383 VFCVectorRBCMVFCid58 1;
BA_ "GenSigSendType" SG_ 1383 VFCVectorRBCMVFCid59 1;
BA_ "GenSigSendType" SG_ 1383 VFCVectorRBCMVFCid6 1;
BA_ "GenSigSendType" SG_ 1383 VFCVectorRBCMVFCid60 1;
BA_ "GenSigSendType" SG_ 1383 VFCVectorRBCMVFCid61 1;
BA_ "GenSigSendType" SG_ 1383 VFCVectorRBCMVFCid7 1;
BA_ "GenSigSendType" SG_ 1383 VFCVectorRBCMVFCid8 1;
BA_ "GenSigSendType" SG_ 1383 VFCVectorRBCMVFCid9 1;
BA_ "GenSigSendType" SG_ 896 VehBattUSysU 0;
BA_ "GenSigSendType" SG_ 896 VehBattUSysUQf 0;
BA_ "GenSigStartValue" SG_ 896 VehBattUSysUQf 1;
BA_ "GenSigSendType" SG_ 592 VehCfgPrmBlkIDBytePosn1 1;
BA_ "GenSigSendType" SG_ 592 VehCfgPrmCCPBytePosn2 1;
BA_ "GenSigSendType" SG_ 592 VehCfgPrmCCPBytePosn3 1;
BA_ "GenSigSendType" SG_ 592 VehCfgPrmCCPBytePosn4 1;
BA_ "GenSigSendType" SG_ 592 VehCfgPrmCCPBytePosn5 1;
BA_ "GenSigSendType" SG_ 592 VehCfgPrmCCPBytePosn6 1;
BA_ "GenSigSendType" SG_ 592 VehCfgPrmCCPBytePosn7 1;
BA_ "GenSigSendType" SG_ 592 VehCfgPrmCCPBytePosn8 1;
BA_ "GenSigSendType" SG_ 1015 VehCfgPrmExtBlkIDBytePosn1 1;
BA_ "GenSigSendType" SG_ 1015 VehCfgPrmExtCCPBytePosn2 1;
BA_ "GenSigSendType" SG_ 1015 VehCfgPrmExtCCPBytePosn3 1;
BA_ "GenSigSendType" SG_ 1015 VehCfgPrmExtCCPBytePosn4 1;
BA_ "GenSigSendType" SG_ 1015 VehCfgPrmExtCCPBytePosn5 1;
BA_ "GenSigSendType" SG_ 1015 VehCfgPrmExtCCPBytePosn6 1;
BA_ "GenSigSendType" SG_ 1015 VehCfgPrmExtCCPBytePosn7 1;
BA_ "GenSigSendType" SG_ 1015 VehCfgPrmExtCCPBytePosn8 1;
BA_ "GenSigSendType" SG_ 736 VehModMngtGlbSafe1CarModSts1 0;
BA_ "GenSigSendType" SG_ 736 VehModMngtGlbSafe1CarModSubtypWdCarModSubtyp 0;
BA_ "GenSigDataID" SG_ 736 VehModMngtGlbSafe1Chks "0x74";
BA_ "GenSigFuncType" SG_ 736 VehModMngtGlbSafe1Chks 15;
BA_ "GenSigSendType" SG_ 736 VehModMngtGlbSafe1Chks 0;
BA_ "GenSigFuncType" SG_ 736 VehModMngtGlbSafe1Cntr 16;
BA_ "GenSigSendType" SG_ 736 VehModMngtGlbSafe1Cntr 0;
BA_ "GenSigSendType" SG_ 736 VehModMngtGlbSafe1EgyLvlElecMai 0;
BA_ "GenSigSendType" SG_ 736 VehModMngtGlbSafe1EgyLvlElecSubtyp 0;
BA_ "GenSigSendType" SG_ 736 VehModMngtGlbSafe1FltEgyCnsWdSts 0;
BA_ "GenSigSendType" SG_ 736 VehModMngtGlbSafe1PwrLvlElecMai 0;
BA_ "GenSigSendType" SG_ 736 VehModMngtGlbSafe1PwrLvlElecSubtyp 0;
BA_ "GenSigSendType" SG_ 736 VehModMngtGlbSafe1UsgModSts 0;
BA_ "GenSigStartValue" SG_ 736 VehModMngtGlbSafe1UsgModSts 1;
BA_ "GenSigDataID" SG_ 1159 VehMtnStChks "0x36";
BA_ "GenSigFuncType" SG_ 1159 VehMtnStChks 15;
BA_ "GenSigSendType" SG_ 1159 VehMtnStChks 0;
BA_ "GenSigFuncType" SG_ 1159 VehMtnStCntr 16;
BA_ "GenSigSendType" SG_ 1159 VehMtnStCntr 0;
BA_ "GenSigSendType" SG_ 1159 VehMtnStVehMtnSt 0;
BA_ "GenSigSendType" SG_ 224 VehSpdLgtA 0;
BA_ "GenSigDataID" SG_ 224 VehSpdLgtChks "0x37";
BA_ "GenSigFuncType" SG_ 224 VehSpdLgtChks 15;
BA_ "GenSigSendType" SG_ 224 VehSpdLgtChks 0;
BA_ "GenSigFuncType" SG_ 224 VehSpdLgtCntr 16;
BA_ "GenSigSendType" SG_ 224 VehSpdLgtCntr 0;
BA_ "GenSigSendType" SG_ 545 VehSpdLgtForBkpVehSpdLgtA 0;
BA_ "GenSigDataID" SG_ 545 VehSpdLgtForBkpVehSpdLgtChks "0x1967";
BA_ "GenSigFuncType" SG_ 545 VehSpdLgtForBkpVehSpdLgtChks 15;
BA_ "GenSigSendType" SG_ 545 VehSpdLgtForBkpVehSpdLgtChks 0;
BA_ "GenSigFuncType" SG_ 545 VehSpdLgtForBkpVehSpdLgtCntr 16;
BA_ "GenSigSendType" SG_ 545 VehSpdLgtForBkpVehSpdLgtCntr 0;
BA_ "GenSigSendType" SG_ 545 VehSpdLgtForBkpVehSpdLgtQf 0;
BA_ "GenSigSendType" SG_ 224 VehSpdLgtQf 0;
BA_ "GenSigStartValue" SG_ 224 VehSpdLgtQf 1;
BA_ "GenSigSendType" SG_ 137 WhlFastSpdSafeA 0;
BA_ "GenSigDataID" SG_ 137 WhlFastSpdSafeChks "0x1972";
BA_ "GenSigFuncType" SG_ 137 WhlFastSpdSafeChks 15;
BA_ "GenSigSendType" SG_ 137 WhlFastSpdSafeChks 0;
BA_ "GenSigFuncType" SG_ 137 WhlFastSpdSafeCntr 16;
BA_ "GenSigSendType" SG_ 137 WhlFastSpdSafeCntr 0;
BA_ "GenSigSendType" SG_ 137 WhlFastSpdSafeQF 0;
BA_ "GenSigStartValue" SG_ 137 WhlFastSpdSafeQF 1;
BA_ "GenSigDataID" SG_ 1099 WhlRotToothCntrChks "0x19C8";
BA_ "GenSigFuncType" SG_ 1099 WhlRotToothCntrChks 15;
BA_ "GenSigSendType" SG_ 1099 WhlRotToothCntrChks 0;
BA_ "GenSigFuncType" SG_ 1099 WhlRotToothCntrCntr 16;
BA_ "GenSigSendType" SG_ 1099 WhlRotToothCntrCntr 0;
BA_ "GenSigDataID" SG_ 593 WhlRotToothCntrForBkpChks "0x19AF";
BA_ "GenSigFuncType" SG_ 593 WhlRotToothCntrForBkpChks 15;
BA_ "GenSigSendType" SG_ 593 WhlRotToothCntrForBkpChks 0;
BA_ "GenSigFuncType" SG_ 593 WhlRotToothCntrForBkpCntr 16;
BA_ "GenSigSendType" SG_ 593 WhlRotToothCntrForBkpCntr 0;
BA_ "GenSigSendType" SG_ 593 WhlRotToothCntrForBkpWhlRotToothCntrFrntLe 0;
BA_ "GenSigSendType" SG_ 593 WhlRotToothCntrForBkpWhlRotToothCntrFrntRi 0;
BA_ "GenSigSendType" SG_ 593 WhlRotToothCntrForBkpWhlRotToothCntrReLe 0;
BA_ "GenSigSendType" SG_ 593 WhlRotToothCntrForBkpWhlRotToothCntrReRi 0;
BA_ "GenSigSendType" SG_ 1099 WhlRotToothCntrFrntLe 0;
BA_ "GenSigSendType" SG_ 1099 WhlRotToothCntrFrntRi 0;
BA_ "GenSigSendType" SG_ 1099 WhlRotToothCntrReLe 0;
BA_ "GenSigSendType" SG_ 1099 WhlRotToothCntrReRi 0;
BA_ "GenSigDataID" SG_ 433 WhlSpdCircumlFrntChks "0x6F";
BA_ "GenSigFuncType" SG_ 433 WhlSpdCircumlFrntChks 15;
BA_ "GenSigSendType" SG_ 433 WhlSpdCircumlFrntChks 0;
BA_ "GenSigFuncType" SG_ 433 WhlSpdCircumlFrntCntr 16;
BA_ "GenSigSendType" SG_ 433 WhlSpdCircumlFrntCntr 0;
BA_ "GenSigSendType" SG_ 562 WhlSpdCircumlFrntForBkpWhlSpdCircumlFrntChks 0;
BA_ "GenSigSendType" SG_ 562 WhlSpdCircumlFrntForBkpWhlSpdCircumlFrntCntr 0;
BA_ "GenSigSendType" SG_ 562 WhlSpdCircumlFrntForBkpWhlSpdCircumlFrntLe 0;
BA_ "GenSigSendType" SG_ 562 WhlSpdCircumlFrntForBkpWhlSpdCircumlFrntLeQf 0;
BA_ "GenSigSendType" SG_ 562 WhlSpdCircumlFrntForBkpWhlSpdCircumlFrntRiQf 0;
BA_ "GenSigSendType" SG_ 562 WhlSpdCircumlFrntForBkpWhlSpdCircumlFrntWhlSpdCircumlFrntRi 0;
BA_ "GenSigSendType" SG_ 433 WhlSpdCircumlFrntLe 0;
BA_ "GenSigSendType" SG_ 433 WhlSpdCircumlFrntLeQf 0;
BA_ "GenSigStartValue" SG_ 433 WhlSpdCircumlFrntLeQf 1;
BA_ "GenSigSendType" SG_ 433 WhlSpdCircumlFrntRiQf 0;
BA_ "GenSigStartValue" SG_ 433 WhlSpdCircumlFrntRiQf 1;
BA_ "GenSigSendType" SG_ 433 WhlSpdCircumlFrntWhlSpdCircumlFrntRi 0;
BA_ "GenSigDataID" SG_ 439 WhlSpdCircumlReChks "0x7C";
BA_ "GenSigFuncType" SG_ 439 WhlSpdCircumlReChks 15;
BA_ "GenSigSendType" SG_ 439 WhlSpdCircumlReChks 0;
BA_ "GenSigFuncType" SG_ 439 WhlSpdCircumlReCntr 16;
BA_ "GenSigSendType" SG_ 439 WhlSpdCircumlReCntr 0;
BA_ "GenSigSendType" SG_ 569 WhlSpdCircumlReForBkpWhlSpdCircumlReChks 0;
BA_ "GenSigSendType" SG_ 569 WhlSpdCircumlReForBkpWhlSpdCircumlReCntr 0;
BA_ "GenSigSendType" SG_ 569 WhlSpdCircumlReForBkpWhlSpdCircumlReLe 0;
BA_ "GenSigSendType" SG_ 569 WhlSpdCircumlReForBkpWhlSpdCircumlReLeQf 0;
BA_ "GenSigSendType" SG_ 569 WhlSpdCircumlReForBkpWhlSpdCircumlReRi 0;
BA_ "GenSigSendType" SG_ 569 WhlSpdCircumlReForBkpWhlSpdCircumlReRiQf 0;
BA_ "GenSigSendType" SG_ 439 WhlSpdCircumlReLe 0;
BA_ "GenSigSendType" SG_ 439 WhlSpdCircumlReLeQf 0;
BA_ "GenSigStartValue" SG_ 439 WhlSpdCircumlReLeQf 1;
BA_ "GenSigSendType" SG_ 439 WhlSpdCircumlReRi 0;
BA_ "GenSigSendType" SG_ 439 WhlSpdCircumlReRiQf 0;
BA_ "GenSigStartValue" SG_ 439 WhlSpdCircumlReRiQf 1;

VAL_ 147 AsyADL3FuncCtrlStsADMod 0 "ADMod_NAD_Mod" 1 "ADMod_TJP_HWC" 2 "ADMod_NOP" 3 "ADMod_E2E";
VAL_ 147 AsyADL3FuncCtrlStsCtrlSts 0 "Primary" 1 "Secondary";
VAL_ 147 AsyADL3FuncCtrlStsQf 0 "GenQf1_UndefindDataAccur" 1 "GenQf1_TmpUndefdData" 2 "GenQf1_DataAccurNotWithinSpcn" 3 "GenQf1_AccurData";
VAL_ 147 AsyADL3FuncCtrlStsSts 0 "ColorSts_Red" 1 "ColorSts_Yellow" 2 "ColorSts_Green" 3 "ColorSts_Reserved";
VAL_ 147 AsyADModeReqADActiveReq 0 "ADMod_NAD_Mod" 1 "ADMod_TJP_HWC" 2 "ADMod_NOP" 3 "ADMod_E2E";
VAL_ 147 AsyADModeReqADDeactiveReq 0 "ReqSts1_NotReqd" 1 "ReqSts1_Reqd";
VAL_ 147 PASFuncActive 0 "OnOff1_Off" 1 "OnOff1_On";
VAL_ 147 RctaBrkReqQM 0 "OnOff1_Off" 1 "OnOff1_On";
VAL_ 147 RcwmBrkReqQM 0 "OnOff1_Off" 1 "OnOff1_On";
VAL_ 327 EpbStsEpbSts 0 "EpbSts_Resd0" 1 "EpbSts_Resd1" 2 "EpbSts_Resd2" 3 "EpbSts_AllAppld" 4 "EpbSts_Resd4" 5 "EpbSts_AllInTran" 6 "EpbSts_BrkgDynByActr" 7 "EpbSts_Resd7" 8 "EpbSts_Resd8" 9 "EpbSts_ActrAllReld" 10 "EpbSts_BrkgDynDegraded" 11 "EpbSts_Resd11" 12 "EpbSts_BrkgDyn" 13 "EpbSts_Resd13" 14 "EpbSts_Resd14" 15 "EpbSts_Err";
VAL_ 84 SteerReCtrlReqAqRecQf 0 "GenQf1_UndefindDataAccur" 1 "GenQf1_TmpUndefdData" 2 "GenQf1_DataAccurNotWithinSpcn" 3 "GenQf1_AccurData";
VAL_ 84 SteerReCtrlReqSteerReCtrlSts 0 "CtrlSts3b_INIT" 1 "CtrlSts3b_CONTROL_NOT_REQUESTED" 2 "CtrlSts3b_CONTROL_REQUESTED" 3 "CtrlSts3b_ERROR" 4 "CtrlSts3b_RESERVED_1" 5 "CtrlSts3b_RESERVED_2" 6 "CtrlSts3b_RESERVED_3" 7 "CtrlSts3b_RESERVED_4";
VAL_ 129 BrkFActAutParkBrkSpprtReq 0 "ReqSts1_NotReqd" 1 "ReqSts1_Reqd";
VAL_ 129 RbuCtrlModReqSafeBrkSysModCfmd 0 "ModCfmd_NoReq" 1 "ModCfmd_E2E" 2 "ModCfmd_Reserved2" 3 "ModCfmd_Reserved3" 4 "ModCfmd_Reserved4" 5 "ModCfmd_Reserved5" 6 "ModCfmd_Reserved6" 7 "ModCfmd_Reserved7" 8 "ModCfmd_Reserved8" 9 "ModCfmd_ACC_HWA" 10 "ModCfmd_PEB" 11 "ModCfmd_APA" 12 "ModCfmd_RPA" 13 "ModCfmd_HPA" 14 "ModCfmd_TJP_HWC" 15 "ModCfmd_NOP";
VAL_ 265 EpbAvlPrimApplyFunctionalitiesAvailable 0 "MsgSts_Inactive" 1 "MsgSts_Active";
VAL_ 265 EpbAvlPrimDriveAwayIntention 0 "MsgSts_Inactive" 1 "MsgSts_Active";
VAL_ 265 EpbAvlPrimHostAvailabilityFull 0 "MsgSts_Inactive" 1 "MsgSts_Active";
VAL_ 265 EpbAvlPrimHostAvailabilityRelOnly 0 "MsgSts_Inactive" 1 "MsgSts_Active";
VAL_ 265 EpbAvlPrimPrimarySystemAvailable 0 "MsgSts_Inactive" 1 "MsgSts_Active";
VAL_ 265 EpbAvlPrimReserved1 0 "MsgSts_Inactive" 1 "MsgSts_Active";
VAL_ 265 EpbAvlPrimReserved2 0 "MsgSts_Inactive" 1 "MsgSts_Active";
VAL_ 265 EpbAvlPrimReserved3 0 "MsgSts_Inactive" 1 "MsgSts_Active";
VAL_ 265 EpbAvlPrimReserved4 0 "MsgSts_Inactive" 1 "MsgSts_Active";
VAL_ 265 EpbAvlPrimRollerTestBench 0 "MsgSts_Inactive" 1 "MsgSts_Active";
VAL_ 265 PrimBrkSysStBrkSysSt 0 "NotAvailable_Temporary" 1 "NotAvailable_NotReleased" 2 "NotAvailable_Permanent" 3 "NotActivated_FullAvailable" 4 "Activation_Preparation" 5 "Activation_Pending" 6 "Activation_PendingRedundancyLost" 7 "Activation_PendingFailOperation" 8 "Activated_FullAvailable" 9 "Activated_FailOperation" 10 "Activated_RedundancyLost" 11 "Deactivation_Pending";
VAL_ 185 ALgtStdFromWhlSpdQf 0 "GenQf1_UndefindDataAccur" 1 "GenQf1_TmpUndefdData" 2 "GenQf1_DataAccurNotWithinSpcn" 3 "GenQf1_AccurData";
VAL_ 185 SlipRatWithinRngForReWhls 0 "NoYes1_No" 1 "NoYes1_Yes";
VAL_ 134 DrvgCyc 0 "OnOff1_Off" 1 "OnOff1_On";
VAL_ 1111 PtTqAtWhlFrntActPtTqAtWhlsFrntQly 0 "Qly3_De0" 1 "Qly3_De1" 2 "Qly3_De2" 3 "Qly3_De3" 4 "Qly3_De4" 5 "Qly3_De5" 6 "Qly3_De6" 7 "Qly3_De7";
VAL_ 131 EngSt1WdStsEngSt1WdSts 0 "EngSt1_Ini" 1 "EngSt1_Awake" 2 "EngSt1_Rdy" 3 "EngSt1_PreStrtg" 4 "EngSt1_StrtgInProgs" 5 "EngSt1_RunngRunng" 6 "EngSt1_RunngStb" 7 "EngSt1_RunngStrtgInProgs" 8 "EngSt1_RunngRemStrtd" 9 "EngSt1_AftRun";
VAL_ 752 DrvrGearLvrInfoIndcn 0 "BrkMsgWarn1_NoReq" 1 "BrkMsgWarn1_Msg1" 2 "BrkMsgWarn1_Msg2" 3 "BrkMsgWarn1_Msg3" 4 "BrkMsgWarn1_Msg4" 5 "BrkMsgWarn1_Msg5" 6 "BrkMsgWarn1_Msg6" 7 "BrkMsgWarn1_Msg7";
VAL_ 752 EngSt1WdSts1 0 "EngSt1_Ini" 1 "EngSt1_Awake" 2 "EngSt1_Rdy" 3 "EngSt1_PreStrtg" 4 "EngSt1_StrtgInProgs" 5 "EngSt1_RunngRunng" 6 "EngSt1_RunngStb" 7 "EngSt1_RunngStrtgInProgs" 8 "EngSt1_RunngRemStrtd" 9 "EngSt1_AftRun";
VAL_ 235 PrkgPinionAgReqGroupQF 0 "GenQf1_UndefindDataAccur" 1 "GenQf1_TmpUndefdData" 2 "GenQf1_DataAccurNotWithinSpcn" 3 "GenQf1_AccurData";
VAL_ 235 UturnTrqRelsUturnTrqRels 0 "Boolean_FALSE" 1 "Boolean_TRUE";
VAL_ 149 PrkgGearReqGroupReqSts1 0 "ReqSts1_NotReqd" 1 "ReqSts1_Reqd";
VAL_ 246 ADL3LatCtrlStsADMod 0 "ADMod_NAD_Mod" 1 "ADMod_TJP_HWC" 2 "ADMod_NOP" 3 "ADMod_E2E";
VAL_ 246 ADL3LatCtrlStsCtrlSts 0 "Primary" 1 "Secondary";
VAL_ 246 ADL3LatCtrlStsDegraded 0 "LatDegrad_NoDegradation_Green" 1 "LatDegrad_Red_fault1" 2 "LatDegrad_Yellow_fault2" 3 "LatDegrad_Yellow_fault3" 4 "LatDegrad_Yellow_fault4" 5 "LatDegrad_Yellow_fault5" 6 "LatDegrad_Yellow_fault6" 7 "LatDegrad_Yellow_fault7" 8 "LatDegrad_Yellow_fault8" 9 "LatDegrad_Yellow_fault9" 10 "LatDegrad_Yellow_fault10" 11 "LatDegrad_Reserved1";
VAL_ 246 ADL3LatCtrlStsQf 0 "GenQf1_UndefindDataAccur" 1 "GenQf1_TmpUndefdData" 2 "GenQf1_DataAccurNotWithinSpcn" 3 "GenQf1_AccurData";
VAL_ 246 ADL3LatCtrlStsSts 0 "ColorSts_Red" 1 "ColorSts_Yellow" 2 "ColorSts_Green" 3 "ColorSts_Reserved";
VAL_ 246 DrvrSteerActvDrvrSteerActv 0 "OnOff1_Off" 1 "OnOff1_On";
VAL_ 246 UBoostReqBySteerFrnt 0 "ReqStsSteer_NoReq" 1 "ReqStsSteer_ParkReq" 2 "ReqStsSteer_EvasiveReq" 3 "ReqStsSteer_Spare01";
VAL_ 70 LatCtrlModCfmdLatCtrlMod 0 "LatCtrlMod1_NoReq" 1 "LatCtrlMod1_HighWayAssist" 2 "LatCtrlMod1_EmgyLaneKeepAidForObjRe" 3 "LatCtrlMod1_EmgyLaneKeepAidForStat" 4 "LatCtrlMod1_SftyLaneKeepAid" 5 "LatCtrlMod1_SteerAssc" 6 "LatCtrlMod1_DsrOversteer" 7 "LatCtrlMod1_DsrMueSplit" 8 "LatCtrlMod1_DsrTrlrStaby" 9 "LatCtrlMod1_EmgyManvAssi" 10 "LatCtrlMod1_Reserved1" 11 "LatCtrlMod1_Reserved2" 12 "LatCtrlMod1_SHWA" 13 "LatCtrlMod1_APA" 14 "LatCtrlMod1_RPA" 15 "LatCtrlMod1_HPA";
VAL_ 70 SteerServoSts 0 "SteerServoSts1_SteerPwrAssidElecFullFct" 1 "SteerServoSts1_SteerPwrAssidElecCritErr";
VAL_ 70 SteerSftyLimrSts 0 "Boolean_FALSE" 1 "Boolean_TRUE";
VAL_ 444 DrvrSteerWhlHldGroupDrvrSteerWhlHld 0 "OnOffDetd1_NoInfo" 1 "OnOffDetd1_OffDetd" 2 "OnOffDetd1_NotOnOrOffDetd" 3 "OnOffDetd1_OnDetd";
VAL_ 444 SteerErrReq 0 "SteerErrReq3_NoReq" 1 "SteerErrReq3_SteerAssiSrvRqrd" 2 "SteerErrReq3_SteerErrStopSfty" 3 "SteerErrReq3_SteerAssiUrgentSrvRqrd" 4 "SteerErrReq3_SteerAssiTmpRedn" 5 "SteerErrReq3_Spare01" 6 "SteerErrReq3_Spare02" 7 "SteerErrReq3_Spare03";
VAL_ 444 SteerExtFctStsDrvrSteerOvrd 0 "Boolean_FALSE" 1 "Boolean_TRUE";
VAL_ 444 SteerExtFctStsExtFctLowerLimActive 0 "Boolean_FALSE" 1 "Boolean_TRUE";
VAL_ 444 SteerExtFctStsExtFctRateLimActive 0 "Boolean_FALSE" 1 "Boolean_TRUE";
VAL_ 444 SteerExtFctStsExtFctUpperLimActive 0 "Boolean_FALSE" 1 "Boolean_TRUE";
VAL_ 444 SteerExtFctStsExtSafeLimActive 0 "Boolean_FALSE" 1 "Boolean_TRUE";
VAL_ 444 SteerExtFctStsLatAgReqNotInRange 0 "Boolean_FALSE" 1 "Boolean_TRUE";
VAL_ 444 SteerExtFctStsLatCtrlReqNotInRange 0 "Boolean_FALSE" 1 "Boolean_TRUE";
VAL_ 444 SteerStsToParkAssi 0 "SteerStsToParkAssi_NormOper" 1 "SteerStsToParkAssi_SteerAbortBySpdHi" 2 "SteerStsToParkAssi_CtrlDifHi" 3 "SteerStsToParkAssi_SteerCtrlIntErr" 4 "SteerStsToParkAssi_SteerAbortByDrvrIntv" 5 "SteerStsToParkAssi_SteerTqHi" 6 "SteerStsToParkAssi_Spare1" 7 "SteerStsToParkAssi_Spare2";
VAL_ 78 PinionSteerAgGroupPinionSteerAg1Qf 0 "GenQf1_UndefindDataAccur" 1 "GenQf1_TmpUndefdData" 2 "GenQf1_DataAccurNotWithinSpcn" 3 "GenQf1_AccurData";
VAL_ 78 PinionSteerAgGroupPinionSteerAgSpd1Qf 0 "GenQf1_UndefindDataAccur" 1 "GenQf1_TmpUndefdData" 2 "GenQf1_DataAccurNotWithinSpcn" 3 "GenQf1_AccurData";
VAL_ 78 PinionSteerAgGroupSteerWhlTqQf 0 "GenQf1_UndefindDataAccur" 1 "GenQf1_TmpUndefdData" 2 "GenQf1_DataAccurNotWithinSpcn" 3 "GenQf1_AccurData";
VAL_ 66 AsySftyHWLReqBkp 0 "AsySftyHWLReq_NoRequest" 1 "AsySftyHWLReq_TurnOn" 2 "AsySftyHWLReq_TurnOff" 3 "AsySftyHWLReq_Reserved";
VAL_ 66 BrkBstStsSec 0 "NoYesUnknown_No" 1 "NoYesUnknown_Yes" 2 "NoYesUnknown_Unknown";
VAL_ 66 EBDiagActive 0 "YesNo2_No" 1 "YesNo2_Yes";
VAL_ 66 TakeoverWarnForBackupTakeoverWarnForBackup 0 "Backup3_Bkp1" 1 "Backup3_Bkp2" 2 "Backup3_Bkp3" 3 "Backup3_Bkp4" 4 "Backup3_Bkp5" 5 "Backup3_Bkp6" 6 "Backup3_Bkp7" 7 "Backup3_Bkp8";
VAL_ 289 AD4IMUStatIMUStat 0 "IMUStat_Normal" 1 "IMUStat_SensorError" 2 "IMUStat_Reserved1" 3 "IMUStat_Reserved2";
VAL_ 289 SecBrkSysStBrkSysSt 0 "NotAvailable_Temporary" 1 "NotAvailable_NotReleased" 2 "NotAvailable_Permanent" 3 "NotActivated_FullAvailable" 4 "Activation_Preparation" 5 "Activation_Pending" 6 "Activation_PendingRedundancyLost" 7 "Activation_PendingFailOperation" 8 "Activated_FullAvailable" 9 "Activated_FailOperation" 10 "Activated_RedundancyLost" 11 "Deactivation_Pending";
VAL_ 545 BrkLiOnReqForBkpBrkLiOnReqSts 0 "ReqSts1_NotReqd" 1 "ReqSts1_Reqd";
VAL_ 545 VehSpdLgtForBkpVehSpdLgtQf 0 "GenQf1_UndefindDataAccur" 1 "GenQf1_TmpUndefdData" 2 "GenQf1_DataAccurNotWithinSpcn" 3 "GenQf1_AccurData";
VAL_ 562 WhlSpdCircumlFrntForBkpWhlSpdCircumlFrntLeQf 0 "GenQf1_UndefindDataAccur" 1 "GenQf1_TmpUndefdData" 2 "GenQf1_DataAccurNotWithinSpcn" 3 "GenQf1_AccurData";
VAL_ 562 WhlSpdCircumlFrntForBkpWhlSpdCircumlFrntRiQf 0 "GenQf1_UndefindDataAccur" 1 "GenQf1_TmpUndefdData" 2 "GenQf1_DataAccurNotWithinSpcn" 3 "GenQf1_AccurData";
VAL_ 569 WhlSpdCircumlReForBkpWhlSpdCircumlReLeQf 0 "GenQf1_UndefindDataAccur" 1 "GenQf1_TmpUndefdData" 2 "GenQf1_DataAccurNotWithinSpcn" 3 "GenQf1_AccurData";
VAL_ 569 WhlSpdCircumlReForBkpWhlSpdCircumlReRiQf 0 "GenQf1_UndefindDataAccur" 1 "GenQf1_TmpUndefdData" 2 "GenQf1_DataAccurNotWithinSpcn" 3 "GenQf1_AccurData";
VAL_ 1383 VFCVectorRBCMVFCid0 0 "VFCOnOff_Off" 1 "VFCOnOff_On";
VAL_ 1383 VFCVectorRBCMVFCid1 0 "VFCOnOff_Off" 1 "VFCOnOff_On";
VAL_ 1383 VFCVectorRBCMVFCid10 0 "VFCOnOff_Off" 1 "VFCOnOff_On";
VAL_ 1383 VFCVectorRBCMVFCid11 0 "VFCOnOff_Off" 1 "VFCOnOff_On";
VAL_ 1383 VFCVectorRBCMVFCid12 0 "VFCOnOff_Off" 1 "VFCOnOff_On";
VAL_ 1383 VFCVectorRBCMVFCid13 0 "VFCOnOff_Off" 1 "VFCOnOff_On";
VAL_ 1383 VFCVectorRBCMVFCid14 0 "VFCOnOff_Off" 1 "VFCOnOff_On";
VAL_ 1383 VFCVectorRBCMVFCid15 0 "VFCOnOff_Off" 1 "VFCOnOff_On";
VAL_ 1383 VFCVectorRBCMVFCid16 0 "VFCOnOff_Off" 1 "VFCOnOff_On";
VAL_ 1383 VFCVectorRBCMVFCid17 0 "VFCOnOff_Off" 1 "VFCOnOff_On";
VAL_ 1383 VFCVectorRBCMVFCid18 0 "VFCOnOff_Off" 1 "VFCOnOff_On";
VAL_ 1383 VFCVectorRBCMVFCid19 0 "VFCOnOff_Off" 1 "VFCOnOff_On";
VAL_ 1383 VFCVectorRBCMVFCid2 0 "VFCOnOff_Off" 1 "VFCOnOff_On";
VAL_ 1383 VFCVectorRBCMVFCid20 0 "VFCOnOff_Off" 1 "VFCOnOff_On";
VAL_ 1383 VFCVectorRBCMVFCid21 0 "VFCOnOff_Off" 1 "VFCOnOff_On";
VAL_ 1383 VFCVectorRBCMVFCid22 0 "VFCOnOff_Off" 1 "VFCOnOff_On";
VAL_ 1383 VFCVectorRBCMVFCid23 0 "VFCOnOff_Off" 1 "VFCOnOff_On";
VAL_ 1383 VFCVectorRBCMVFCid24 0 "VFCOnOff_Off" 1 "VFCOnOff_On";
VAL_ 1383 VFCVectorRBCMVFCid25 0 "VFCOnOff_Off" 1 "VFCOnOff_On";
VAL_ 1383 VFCVectorRBCMVFCid26 0 "VFCOnOff_Off" 1 "VFCOnOff_On";
VAL_ 1383 VFCVectorRBCMVFCid27 0 "VFCOnOff_Off" 1 "VFCOnOff_On";
VAL_ 1383 VFCVectorRBCMVFCid28 0 "VFCOnOff_Off" 1 "VFCOnOff_On";
VAL_ 1383 VFCVectorRBCMVFCid29 0 "VFCOnOff_Off" 1 "VFCOnOff_On";
VAL_ 1383 VFCVectorRBCMVFCid3 0 "VFCOnOff_Off" 1 "VFCOnOff_On";
VAL_ 1383 VFCVectorRBCMVFCid30 0 "VFCOnOff_Off" 1 "VFCOnOff_On";
VAL_ 1383 VFCVectorRBCMVFCid31 0 "VFCOnOff_Off" 1 "VFCOnOff_On";
VAL_ 1383 VFCVectorRBCMVFCid32 0 "VFCOnOff_Off" 1 "VFCOnOff_On";
VAL_ 1383 VFCVectorRBCMVFCid33 0 "VFCOnOff_Off" 1 "VFCOnOff_On";
VAL_ 1383 VFCVectorRBCMVFCid34 0 "VFCOnOff_Off" 1 "VFCOnOff_On";
VAL_ 1383 VFCVectorRBCMVFCid35 0 "VFCOnOff_Off" 1 "VFCOnOff_On";
VAL_ 1383 VFCVectorRBCMVFCid36 0 "VFCOnOff_Off" 1 "VFCOnOff_On";
VAL_ 1383 VFCVectorRBCMVFCid37 0 "VFCOnOff_Off" 1 "VFCOnOff_On";
VAL_ 1383 VFCVectorRBCMVFCid38 0 "VFCOnOff_Off" 1 "VFCOnOff_On";
VAL_ 1383 VFCVectorRBCMVFCid39 0 "VFCOnOff_Off" 1 "VFCOnOff_On";
VAL_ 1383 VFCVectorRBCMVFCid4 0 "VFCOnOff_Off" 1 "VFCOnOff_On";
VAL_ 1383 VFCVectorRBCMVFCid40 0 "VFCOnOff_Off" 1 "VFCOnOff_On";
VAL_ 1383 VFCVectorRBCMVFCid41 0 "VFCOnOff_Off" 1 "VFCOnOff_On";
VAL_ 1383 VFCVectorRBCMVFCid42 0 "VFCOnOff_Off" 1 "VFCOnOff_On";
VAL_ 1383 VFCVectorRBCMVFCid43 0 "VFCOnOff_Off" 1 "VFCOnOff_On";
VAL_ 1383 VFCVectorRBCMVFCid44 0 "VFCOnOff_Off" 1 "VFCOnOff_On";
VAL_ 1383 VFCVectorRBCMVFCid45 0 "VFCOnOff_Off" 1 "VFCOnOff_On";
VAL_ 1383 VFCVectorRBCMVFCid46 0 "VFCOnOff_Off" 1 "VFCOnOff_On";
VAL_ 1383 VFCVectorRBCMVFCid47 0 "VFCOnOff_Off" 1 "VFCOnOff_On";
VAL_ 1383 VFCVectorRBCMVFCid48 0 "VFCOnOff_Off" 1 "VFCOnOff_On";
VAL_ 1383 VFCVectorRBCMVFCid49 0 "VFCOnOff_Off" 1 "VFCOnOff_On";
VAL_ 1383 VFCVectorRBCMVFCid5 0 "VFCOnOff_Off" 1 "VFCOnOff_On";
VAL_ 1383 VFCVectorRBCMVFCid50 0 "VFCOnOff_Off" 1 "VFCOnOff_On";
VAL_ 1383 VFCVectorRBCMVFCid51 0 "VFCOnOff_Off" 1 "VFCOnOff_On";
VAL_ 1383 VFCVectorRBCMVFCid52 0 "VFCOnOff_Off" 1 "VFCOnOff_On";
VAL_ 1383 VFCVectorRBCMVFCid53 0 "VFCOnOff_Off" 1 "VFCOnOff_On";
VAL_ 1383 VFCVectorRBCMVFCid54 0 "VFCOnOff_Off" 1 "VFCOnOff_On";
VAL_ 1383 VFCVectorRBCMVFCid55 0 "VFCOnOff_Off" 1 "VFCOnOff_On";
VAL_ 1383 VFCVectorRBCMVFCid56 0 "VFCOnOff_Off" 1 "VFCOnOff_On";
VAL_ 1383 VFCVectorRBCMVFCid57 0 "VFCOnOff_Off" 1 "VFCOnOff_On";
VAL_ 1383 VFCVectorRBCMVFCid58 0 "VFCOnOff_Off" 1 "VFCOnOff_On";
VAL_ 1383 VFCVectorRBCMVFCid59 0 "VFCOnOff_Off" 1 "VFCOnOff_On";
VAL_ 1383 VFCVectorRBCMVFCid6 0 "VFCOnOff_Off" 1 "VFCOnOff_On";
VAL_ 1383 VFCVectorRBCMVFCid60 0 "VFCOnOff_Off" 1 "VFCOnOff_On";
VAL_ 1383 VFCVectorRBCMVFCid61 0 "VFCOnOff_Off" 1 "VFCOnOff_On";
VAL_ 1383 VFCVectorRBCMVFCid7 0 "VFCOnOff_Off" 1 "VFCOnOff_On";
VAL_ 1383 VFCVectorRBCMVFCid8 0 "VFCOnOff_Off" 1 "VFCOnOff_On";
VAL_ 1383 VFCVectorRBCMVFCid9 0 "VFCOnOff_Off" 1 "VFCOnOff_On";
VAL_ 64 SteerWhlSnsrQf 0 "GenQf1_UndefindDataAccur" 1 "GenQf1_TmpUndefdData" 2 "GenQf1_DataAccurNotWithinSpcn" 3 "GenQf1_AccurData";
VAL_ 274 SecParkBrkSysSt2BrkSysSt 0 "NotAvailable_Temporary" 1 "NotAvailable_NotReleased" 2 "NotAvailable_Permanent" 3 "NotActivated_FullAvailable" 4 "Activation_Preparation" 5 "Activation_Pending" 6 "Activation_PendingRedundancyLost" 7 "Activation_PendingFailOperation" 8 "Activated_FullAvailable" 9 "Activated_FailOperation" 10 "Activated_RedundancyLost" 11 "Deactivation_Pending";
VAL_ 85 AgDataRaw2SafePitchRateQf 0 "Qf1_DevOfDataUndefd" 1 "Qf1_DataTmpUndefdAndEvlnInProgs" 2 "Qf1_DevOfDataNotWithinRngAllwd" 3 "Qf1_DataCalcdWithDevDefd";
VAL_ 375 RlyPwrDistbnCmd1WdIgnRlyCmd 0 "OnOff1_Off" 1 "OnOff1_On";
VAL_ 342 TiAndDateIndcnDataValid 0 "NoYes1_No" 1 "NoYes1_Yes";
VAL_ 81 AsyDataWithCmpSafeALat1Qf 0 "Qf1_DevOfDataUndefd" 1 "Qf1_DataTmpUndefdAndEvlnInProgs" 2 "Qf1_DevOfDataNotWithinRngAllwd" 3 "Qf1_DataCalcdWithDevDefd";
VAL_ 81 AsyDataWithCmpSafeALgt1Qf 0 "Qf1_DevOfDataUndefd" 1 "Qf1_DataTmpUndefdAndEvlnInProgs" 2 "Qf1_DevOfDataNotWithinRngAllwd" 3 "Qf1_DataCalcdWithDevDefd";
VAL_ 81 AsyDataWithCmpSafeYawRateQf 0 "Qf1_DevOfDataUndefd" 1 "Qf1_DataTmpUndefdAndEvlnInProgs" 2 "Qf1_DevOfDataNotWithinRngAllwd" 3 "Qf1_DataCalcdWithDevDefd";
VAL_ 160 ADataRawSafeALat1Qf 0 "Qf1_DevOfDataUndefd" 1 "Qf1_DataTmpUndefdAndEvlnInProgs" 2 "Qf1_DevOfDataNotWithinRngAllwd" 3 "Qf1_DataCalcdWithDevDefd";
VAL_ 160 ADataRawSafeALgt1Qf 0 "Qf1_DevOfDataUndefd" 1 "Qf1_DataTmpUndefdAndEvlnInProgs" 2 "Qf1_DevOfDataNotWithinRngAllwd" 3 "Qf1_DataCalcdWithDevDefd";
VAL_ 160 ADataRawSafeAVertQf 0 "Qf1_DevOfDataUndefd" 1 "Qf1_DataTmpUndefdAndEvlnInProgs" 2 "Qf1_DevOfDataNotWithinRngAllwd" 3 "Qf1_DataCalcdWithDevDefd";
VAL_ 400 AbsCtrlActvCtrlSts1 0 "CtrlSts1_NoCtrl" 1 "CtrlSts1_InCtrl";
VAL_ 400 AmbTRawQly 0 "GenQf1_UndefindDataAccur" 1 "GenQf1_TmpUndefdData" 2 "GenQf1_DataAccurNotWithinSpcn" 3 "GenQf1_AccurData";
VAL_ 400 LatCtrlReqSafeLatCtrlModReq 0 "LatCtrlMod1_NoReq" 1 "LatCtrlMod1_HighWayAssist" 2 "LatCtrlMod1_EmgyLaneKeepAidForObjRe" 3 "LatCtrlMod1_EmgyLaneKeepAidForStat" 4 "LatCtrlMod1_SftyLaneKeepAid" 5 "LatCtrlMod1_SteerAssc" 6 "LatCtrlMod1_DsrOversteer" 7 "LatCtrlMod1_DsrMueSplit" 8 "LatCtrlMod1_DsrTrlrStaby" 9 "LatCtrlMod1_EmgyManvAssi" 10 "LatCtrlMod1_Reserved1" 11 "LatCtrlMod1_Reserved2" 12 "LatCtrlMod1_SHWA" 13 "LatCtrlMod1_APA" 14 "LatCtrlMod1_RPA" 15 "LatCtrlMod1_HPA";
VAL_ 400 LatCtrlReqSafeSteerWhlHptcWarnReq 0 "OnOff1_Off" 1 "OnOff1_On";
VAL_ 224 VehSpdLgtQf 0 "GenQf1_UndefindDataAccur" 1 "GenQf1_TmpUndefdData" 2 "GenQf1_DataAccurNotWithinSpcn" 3 "GenQf1_AccurData";
VAL_ 928 AmbTIndcdWithUnitAmbTIndcdUnit 0 "AmbTIndcdUnit_Celsius" 1 "AmbTIndcdUnit_Fahrenheit" 2 "AmbTIndcdUnit_UkwnUnit";
VAL_ 928 AmbTIndcdWithUnitQF 0 "GenQf1_UndefindDataAccur" 1 "GenQf1_TmpUndefdData" 2 "GenQf1_DataAccurNotWithinSpcn" 3 "GenQf1_AccurData";
VAL_ 433 BrkPedlPsdBrkPedlNotPsdSafe 0 "NoYes1_No" 1 "NoYes1_Yes";
VAL_ 433 BrkPedlPsdBrkPedlPsd 0 "NoYes1_No" 1 "NoYes1_Yes";
VAL_ 433 BrkPedlPsdQf 0 "GenQf1_UndefindDataAccur" 1 "GenQf1_TmpUndefdData" 2 "GenQf1_DataAccurNotWithinSpcn" 3 "GenQf1_AccurData";
VAL_ 433 WhlSpdCircumlFrntLeQf 0 "GenQf1_UndefindDataAccur" 1 "GenQf1_TmpUndefdData" 2 "GenQf1_DataAccurNotWithinSpcn" 3 "GenQf1_AccurData";
VAL_ 433 WhlSpdCircumlFrntRiQf 0 "GenQf1_UndefindDataAccur" 1 "GenQf1_TmpUndefdData" 2 "GenQf1_DataAccurNotWithinSpcn" 3 "GenQf1_AccurData";
VAL_ 432 AgDataRawSafeRollRateQf 0 "Qf1_DevOfDataUndefd" 1 "Qf1_DataTmpUndefdAndEvlnInProgs" 2 "Qf1_DevOfDataNotWithinRngAllwd" 3 "Qf1_DataCalcdWithDevDefd";
VAL_ 432 AgDataRawSafeYawRateQf 0 "Qf1_DevOfDataUndefd" 1 "Qf1_DataTmpUndefdAndEvlnInProgs" 2 "Qf1_DevOfDataNotWithinRngAllwd" 3 "Qf1_DataCalcdWithDevDefd";
VAL_ 736 VehModMngtGlbSafe1CarModSts1 0 "CarModSts1_CarModNorm" 1 "CarModSts1_CarModTrnsp" 2 "CarModSts1_CarModFcy" 3 "CarModSts1_CarModCrash" 5 "CarModSts1_CarModDyno";
VAL_ 736 VehModMngtGlbSafe1FltEgyCnsWdSts 0 "FltEgyCns1_NoFlt" 1 "FltEgyCns1_Flt";
VAL_ 736 VehModMngtGlbSafe1UsgModSts 0 "UsgModSts1_UsgModAbdnd" 1 "UsgModSts1_UsgModInActv" 2 "UsgModSts1_UsgModCnvinc" 11 "UsgModSts1_UsgModActv" 13 "UsgModSts1_UsgModDrvg";
VAL_ 38 VFCInfoEna 0 "EnableDisableCoding_Disabled" 1 "EnableDisableCoding_Enabled";
VAL_ 1123 SteerSetgPen 0 "IdPen_ProfUkwn" 1 "IdPen_Prof1" 2 "IdPen_Prof2" 3 "IdPen_Prof3" 4 "IdPen_Prof4" 5 "IdPen_Prof5" 6 "IdPen_Prof6" 7 "IdPen_Prof7" 8 "IdPen_Prof8" 9 "IdPen_Prof9" 10 "IdPen_Prof10" 11 "IdPen_Prof11" 12 "IdPen_Prof12" 13 "IdPen_Prof13" 14 "IdPen_Resd14" 15 "IdPen_ProfAll";
VAL_ 1123 SteerSetgSteerAsscLvl 0 "SteerAsscLvl_Ukwn" 1 "SteerAsscLvl_Lvl1" 2 "SteerAsscLvl_Lvl2" 3 "SteerAsscLvl_Lvl3" 4 "SteerAsscLvl_Lvl4" 5 "SteerAsscLvl_Resd5" 6 "SteerAsscLvl_Resd6" 7 "SteerAsscLvl_Resd7";
VAL_ 1123 SteerSetgSteerMod 0 "SteerMod_Ukwn" 1 "SteerMod_Mod1" 2 "SteerMod_Mod2" 3 "SteerMod_Mod3" 4 "SteerMod_Mod4" 5 "SteerMod_Resd5" 6 "SteerMod_Resd6" 7 "SteerMod_Resd7";
VAL_ 784 CmptmtTFrntFanForCmptmtTRunng 0 "Flg1_Rst" 1 "Flg1_Set";
VAL_ 784 CmptmtTFrntQf 0 "CmptmtTFrntQf_SnsrDataUndefd" 1 "CmptmtTFrntQf_FanNotRunning" 2 "CmptmtTFrntQf_SnsrDataNotOk" 3 "CmptmtTFrntQf_SnsrDataOk";
VAL_ 137 HsaSt 0 "YesNo2_No" 1 "YesNo2_Yes";
VAL_ 137 WhlFastSpdSafeQF 0 "GenQf1_UndefindDataAccur" 1 "GenQf1_TmpUndefdData" 2 "GenQf1_DataAccurNotWithinSpcn" 3 "GenQf1_AccurData";
VAL_ 686 AbsSts 0 "DevErrSts2_NoFlt" 1 "DevErrSts2_Flt";
VAL_ 686 DrvModReq 0 "DrvModReqType1_Undefd" 1 "DrvModReqType1_ECO" 2 "DrvModReqType1_Comfort_Normal" 3 "DrvModReqType1_Dynamic_Sport" 4 "DrvModReqType1_Individual" 5 "DrvModReqType1_Offroad_CrossTerrain" 6 "DrvModReqType1_Adaptive" 7 "DrvModReqType1_Race" 8 "DrvModReqType1_Pure_EV" 9 "DrvModReqType1_Hybrid" 10 "DrvModReqType1_Power" 11 "DrvModReqType1_Snow" 12 "DrvModReqType1_Sand" 13 "DrvModReqType1_Mud" 14 "DrvModReqType1_Rock" 15 "DrvModReqType1_Err";
VAL_ 686 ULoWarnULoWarn 0 "ULoWarn_UOk" 1 "ULoWarn_ULoTmp" 2 "ULoWarn_ULoPrmnt";
VAL_ 1267 EscStEscSt 0 "EscSt1_Inin" 1 "EscSt1_Ok" 2 "EscSt1_TmpErr" 3 "EscSt1_PrmntErr" 4 "EscSt1_UsrOff";
VAL_ 1099 BrkTracCtrlActv 0 "CtrlSts1_NoCtrl" 1 "CtrlSts1_InCtrl";
VAL_ 1159 VehMtnStVehMtnSt 0 "VehMtnSt2_Ukwn" 1 "VehMtnSt2_StandStillVal1" 2 "VehMtnSt2_StandStillVal2" 3 "VehMtnSt2_StandStillVal3" 4 "VehMtnSt2_RollgFwdVal1" 5 "VehMtnSt2_RollgFwdVal2" 6 "VehMtnSt2_RollgBackwVal1" 7 "VehMtnSt2_RollgBackwVal2";
VAL_ 864 ProfPenSts1 0 "IdPen_ProfUkwn" 1 "IdPen_Prof1" 2 "IdPen_Prof2" 3 "IdPen_Prof3" 4 "IdPen_Prof4" 5 "IdPen_Prof5" 6 "IdPen_Prof6" 7 "IdPen_Prof7" 8 "IdPen_Prof8" 9 "IdPen_Prof9" 10 "IdPen_Prof10" 11 "IdPen_Prof11" 12 "IdPen_Prof12" 13 "IdPen_Prof13" 14 "IdPen_Resd14" 15 "IdPen_ProfAll";
VAL_ 864 SaveSetgToMemPrmnt 0 "OffOnAut1_Off" 1 "OffOnAut1_On" 2 "OffOnAut1_Aut";
VAL_ 896 VehBattUSysUQf 0 "GenQf1_UndefindDataAccur" 1 "GenQf1_TmpUndefdData" 2 "GenQf1_DataAccurNotWithinSpcn" 3 "GenQf1_AccurData";
VAL_ 496 DrvModReqForChampnMod 0 "SteerMod_Ukwn" 1 "SteerMod_Mod1" 2 "SteerMod_Mod2" 3 "SteerMod_Mod3" 4 "SteerMod_Mod4" 5 "SteerMod_Resd5" 6 "SteerMod_Resd6" 7 "SteerMod_Resd7";
VAL_ 439 WhlSpdCircumlReLeQf 0 "GenQf1_UndefindDataAccur" 1 "GenQf1_TmpUndefdData" 2 "GenQf1_DataAccurNotWithinSpcn" 3 "GenQf1_AccurData";
VAL_ 439 WhlSpdCircumlReRiQf 0 "GenQf1_UndefindDataAccur" 1 "GenQf1_TmpUndefdData" 2 "GenQf1_DataAccurNotWithinSpcn" 3 "GenQf1_AccurData";
SIG_GROUP_ 400 AbsCtrlActv 1 : AbsCtrlActvChks AbsCtrlActvCntr AbsCtrlActvCtrlSts1;
SIG_GROUP_ 85 AccrPedlLnr 1 : AccrPedlLnrAccrPedlRat AccrPedlLnrChks AccrPedlLnrCntr;
SIG_GROUP_ 544 AccrPedlRat 1 : AccrPedlRatAccrPedlRat AccrPedlRatChks AccrPedlRatCntr;
SIG_GROUP_ 323 AD4IMUAcceX 1 : AD4IMUAcceXAcce AD4IMUAcceXChks AD4IMUAcceXCntr AD4IMUAcceXHead;
SIG_GROUP_ 177 AD4IMUAcceY 1 : AD4IMUAcceYAcce AD4IMUAcceYChks AD4IMUAcceYCntr AD4IMUAcceYHead;
SIG_GROUP_ 181 AD4IMUAcceZ 1 : AD4IMUAcceZAcce AD4IMUAcceZChks AD4IMUAcceZCntr AD4IMUAcceZHead;
SIG_GROUP_ 193 AD4IMUGyroX 1 : AD4IMUGyroXChks AD4IMUGyroXCntr AD4IMUGyroXGyro AD4IMUGyroXHead;
SIG_GROUP_ 200 AD4IMUGyroY 1 : AD4IMUGyroYChks AD4IMUGyroYCntr AD4IMUGyroYGyro AD4IMUGyroYHead;
SIG_GROUP_ 166 AD4IMUGyroZ 1 : AD4IMUGyroZChks AD4IMUGyroZCntr AD4IMUGyroZGyro AD4IMUGyroZHead;
SIG_GROUP_ 289 AD4IMUStat 1 : AD4IMUStatChks AD4IMUStatCntr AD4IMUStatHead AD4IMUStatIMUStat AD4IMUStatIMUTemp;
SIG_GROUP_ 160 ADataRawSafe 1 : ADataRawSafeALat ADataRawSafeALat1Qf ADataRawSafeALgt ADataRawSafeALgt1Qf ADataRawSafeAVert ADataRawSafeAVertQf ADataRawSafeChks ADataRawSafeCntr;
SIG_GROUP_ 246 ADL3LatCtrlSts 1 : ADL3LatCtrlStsADMod ADL3LatCtrlStsChks ADL3LatCtrlStsCntr ADL3LatCtrlStsCtrlSts ADL3LatCtrlStsDegraded ADL3LatCtrlStsQf ADL3LatCtrlStsSts;
SIG_GROUP_ 26 AgDataCmpQuality 1 : AgDataCmpQualityPitchRateCmpQuality AgDataCmpQualityRollRateCmpQuality AgDataCmpQualityYawRateCmpQuality;
SIG_GROUP_ 85 AgDataRaw2Safe 1 : AgDataRaw2SafeChks AgDataRaw2SafeCntr AgDataRaw2SafePitchRate AgDataRaw2SafePitchRateQf;
SIG_GROUP_ 432 AgDataRawSafe 1 : AgDataRawSafeChks AgDataRawSafeCntr AgDataRawSafeRollRate AgDataRawSafeRollRateQf AgDataRawSafeYawRate AgDataRawSafeYawRateQf;
SIG_GROUP_ 185 ALgtStdFromWhlSpd 1 : ALgtStdFromWhlSpdALgtStdFromWhlSpd ALgtStdFromWhlSpdChks ALgtStdFromWhlSpdCntr ALgtStdFromWhlSpdQf;
SIG_GROUP_ 928 AmbTIndcdWithUnit 1 : AmbTIndcdWithUnitAmbTIndcd AmbTIndcdWithUnitAmbTIndcdUnit AmbTIndcdWithUnitQF;
SIG_GROUP_ 400 AmbTRaw 1 : AmbTRawAmbTVal AmbTRawQly;
SIG_GROUP_ 147 AsyADL3FuncCtrlSts 1 : AsyADL3FuncCtrlStsADMod AsyADL3FuncCtrlStsChks AsyADL3FuncCtrlStsCntr AsyADL3FuncCtrlStsCtrlSts AsyADL3FuncCtrlStsDegraded AsyADL3FuncCtrlStsQf AsyADL3FuncCtrlStsSts;
SIG_GROUP_ 147 AsyADModeReq 1 : AsyADModeReqADActiveReq AsyADModeReqADDeactiveReq AsyADModeReqChks AsyADModeReqCntr;
SIG_GROUP_ 81 AsyDataWithCmpSafe 1 : AsyDataWithCmpSafeALat1Qf AsyDataWithCmpSafeALatWithCmp AsyDataWithCmpSafeALgt1Qf AsyDataWithCmpSafeChks AsyDataWithCmpSafeCntr AsyDataWithCmpSafeGrdtOfALgt AsyDataWithCmpSafeYawRateQf AsyDataWithCmpSafeYawRateWithCmp;
SIG_GROUP_ 51 AsyPinionAgReqSafe 1 : AsyPinionAgReqSafeAsyPinionAgReq AsyPinionAgReqSafeAsyPinionAgReqChks AsyPinionAgReqSafeAsyPinionAgReqCntr;
SIG_GROUP_ 129 BrkFAct 1 : BrkFActAutParkBrkSpprtReq BrkFActChks BrkFActCntr BrkFActForce;
SIG_GROUP_ 545 BrkLiOnReqForBkp 1 : BrkLiOnReqForBkpBrkLiOnReqChks BrkLiOnReqForBkpBrkLiOnReqCntr BrkLiOnReqForBkpBrkLiOnReqSts;
SIG_GROUP_ 433 BrkPedlPsd 1 : BrkPedlPsdBrkPedlNotPsdSafe BrkPedlPsdBrkPedlPsd BrkPedlPsdChks BrkPedlPsdCntr BrkPedlPsdQf;
SIG_GROUP_ 308 BrkWssInfoFrnt 1 : BrkWssInfoFrntChks BrkWssInfoFrntCntr BrkWssInfoFrntTTCFactorFL BrkWssInfoFrntTTCFactorFR BrkWssInfoFrntWssCoreMonRob;
SIG_GROUP_ 327 BrkWssInfoRe 1 : BrkWssInfoReChks BrkWssInfoReCntr BrkWssInfoReTTCFactorRL BrkWssInfoReTTCFactorRR;
SIG_GROUP_ 784 CmptmtTFrnt 1 : CmptmtTFrntCmptmtTFrnt CmptmtTFrntFanForCmptmtTRunng CmptmtTFrntQf;
SIG_GROUP_ 246 DrvrSteerActv 1 : DrvrSteerActvChks DrvrSteerActvCntr DrvrSteerActvDrvrSteerActv;
SIG_GROUP_ 444 DrvrSteerWhlHldGroup 1 : DrvrSteerWhlHldGroupDrvrSteerWhlHld DrvrSteerWhlHldGroupDrvrSteerWhlHldQly;
SIG_GROUP_ 131 EngSt1WdSts 1 : EngSt1WdStsChks EngSt1WdStsCntr EngSt1WdStsEngSt1WdSts;
SIG_GROUP_ 265 EpbAvlPrim 1 : EpbAvlPrimApplyFunctionalitiesAvailable EpbAvlPrimChks EpbAvlPrimCntr EpbAvlPrimDriveAwayIntention EpbAvlPrimHostAvailabilityFull EpbAvlPrimHostAvailabilityRelOnly EpbAvlPrimPrimarySystemAvailable EpbAvlPrimReserved1 EpbAvlPrimReserved2 EpbAvlPrimReserved3 EpbAvlPrimReserved4 EpbAvlPrimRollerTestBench;
SIG_GROUP_ 327 EpbSts 1 : EpbStsChks EpbStsCntr EpbStsEpbSts;
SIG_GROUP_ 1267 EscSt 1 : EscStChks EscStCntr EscStEscSt;
SIG_GROUP_ 580 IDcDcActLoSide 1 : IDcDcActLoSideChks IDcDcActLoSideCntr IDcDcActLoSideIDcDcActLoSide;
SIG_GROUP_ 70 LatCtrlModCfmd 1 : LatCtrlModCfmdChks LatCtrlModCfmdCntr LatCtrlModCfmdLatCtrlMod;
SIG_GROUP_ 400 LatCtrlReqSafe 1 : LatCtrlReqSafeChks LatCtrlReqSafeCntr LatCtrlReqSafeLatCtrlModReq LatCtrlReqSafeSteerTqReq LatCtrlReqSafeSteerWhlHptcWarnReq;
SIG_GROUP_ 78 PinionSteerAgGroup 1 : PinionSteerAgGroupChks PinionSteerAgGroupCntr PinionSteerAgGroupPinionSteerAg1 PinionSteerAgGroupPinionSteerAg1Qf PinionSteerAgGroupPinionSteerAgSpd1 PinionSteerAgGroupPinionSteerAgSpd1Qf PinionSteerAgGroupSteerWhlTq PinionSteerAgGroupSteerWhlTqQf;
SIG_GROUP_ 265 PrimBrkSysSt 1 : PrimBrkSysStBrkSysSt PrimBrkSysStChks PrimBrkSysStCntr;
SIG_GROUP_ 149 PrkgGearReqGroup 1 : PrkgGearReqGroupChks PrkgGearReqGroupCntr PrkgGearReqGroupReqSts1;
SIG_GROUP_ 235 PrkgPinionAgReqGroup 1 : PrkgPinionAgReqGroupParkAssiPinionAgReq PrkgPinionAgReqGroupParkAssiPinionAgReqChks PrkgPinionAgReqGroupParkAssiPinionAgReqCntr PrkgPinionAgReqGroupQF;
SIG_GROUP_ 1431 PSCMdevelpsignalgroupreq1 1 : PSCMdevelpsignalgroupreq1Functiondevpsignalgroup1 PSCMdevelpsignalgroupreq1Functiondevpsignalgroup2 PSCMdevelpsignalgroupreq1Functiondevpsignalgroup3 PSCMdevelpsignalgroupreq1Functiondevpsignalgroup4 PSCMdevelpsignalgroupreq1Functiondevpsignalgroup5 PSCMdevelpsignalgroupreq1Functiondevpsignalgroup6 PSCMdevelpsignalgroupreq1Functiondevpsignalgroup7 PSCMdevelpsignalgroupreq1Functiondevpsignalgroup8;
SIG_GROUP_ 1430 PSCMdevelpsignalgroupresp1 1 : PSCMdevelpsignalgroupresp1Functiondevpsignalgroup1 PSCMdevelpsignalgroupresp1Functiondevpsignalgroup2 PSCMdevelpsignalgroupresp1Functiondevpsignalgroup3 PSCMdevelpsignalgroupresp1Functiondevpsignalgroup4 PSCMdevelpsignalgroupresp1Functiondevpsignalgroup5 PSCMdevelpsignalgroupresp1Functiondevpsignalgroup6 PSCMdevelpsignalgroupresp1Functiondevpsignalgroup7 PSCMdevelpsignalgroupresp1Functiondevpsignalgroup8;
SIG_GROUP_ 1111 PtTqAtWhlFrntAct 1 : PtTqAtWhlFrntActChks PtTqAtWhlFrntActCntr PtTqAtWhlFrntActPtTqAtAxleFrntAct PtTqAtWhlFrntActPtTqAtWhlFrntLeAct PtTqAtWhlFrntActPtTqAtWhlFrntRiAct PtTqAtWhlFrntActPtTqAtWhlsFrntQly;
SIG_GROUP_ 1504 RBCMdevelpsignalgroupreq1 1 : RBCMdevelpsignalgroupreq1Functiondevpsignalgroup1 RBCMdevelpsignalgroupreq1Functiondevpsignalgroup2 RBCMdevelpsignalgroupreq1Functiondevpsignalgroup3 RBCMdevelpsignalgroupreq1Functiondevpsignalgroup4 RBCMdevelpsignalgroupreq1Functiondevpsignalgroup5 RBCMdevelpsignalgroupreq1Functiondevpsignalgroup6 RBCMdevelpsignalgroupreq1Functiondevpsignalgroup7 RBCMdevelpsignalgroupreq1Functiondevpsignalgroup8;
SIG_GROUP_ 129 RbuCtrlModReqSafe 1 : RbuCtrlModReqSafeBrkSysModCfmd RbuCtrlModReqSafeChks RbuCtrlModReqSafeCntr;
SIG_GROUP_ 289 SecBrkSysSt 1 : SecBrkSysStBrkSysSt SecBrkSysStChks SecBrkSysStCntr;
SIG_GROUP_ 274 SecParkBrkSysSt2 1 : SecParkBrkSysSt2BrkSysSt SecParkBrkSysSt2Chks SecParkBrkSysSt2Cntr;
SIG_GROUP_ 444 SteerExtFctSts 1 : SteerExtFctStsChks SteerExtFctStsCntr SteerExtFctStsDrvrSteerOvrd SteerExtFctStsExtFctLowerLimActive SteerExtFctStsExtFctRateLimActive SteerExtFctStsExtFctUpperLimActive SteerExtFctStsExtSafeLimActive SteerExtFctStsLatAgReqNotInRange SteerExtFctStsLatCtrlReqNotInRange;
SIG_GROUP_ 84 SteerReCtrlReq 1 : SteerReCtrlReqAgReq SteerReCtrlReqAqRecQf SteerReCtrlReqChks SteerReCtrlReqCntr SteerReCtrlReqSteerReCtrlSts;
SIG_GROUP_ 1123 SteerSetg 1 : SteerSetgPen SteerSetgSteerAsscLvl SteerSetgSteerMod;
SIG_GROUP_ 64 SteerWhlSnsr 1 : SteerWhlSnsrAg SteerWhlSnsrAgSpd SteerWhlSnsrChks SteerWhlSnsrCntr SteerWhlSnsrQf;
SIG_GROUP_ 66 TakeoverWarnForBackup 1 : TakeoverWarnForBackupChks TakeoverWarnForBackupCntr TakeoverWarnForBackupTakeoverWarnForBackup;
SIG_GROUP_ 342 TiAndDateIndcn 1 : TiAndDateIndcnDataValid TiAndDateIndcnDay TiAndDateIndcnHr1 TiAndDateIndcnMins1 TiAndDateIndcnMth1 TiAndDateIndcnSec1 TiAndDateIndcnYr1;
SIG_GROUP_ 686 ULoWarn 1 : ULoWarnChks ULoWarnCntr ULoWarnULoWarn;
SIG_GROUP_ 235 UturnTrqRels 1 : UturnTrqRelsChks UturnTrqRelsCntr UturnTrqRelsUturnTrqRels;
SIG_GROUP_ 1432 VDDMdevelpsignalgroupreq1 1 : VDDMdevelpsignalgroupreq1Functiondevpsignalgroup1 VDDMdevelpsignalgroupreq1Functiondevpsignalgroup2 VDDMdevelpsignalgroupreq1Functiondevpsignalgroup3 VDDMdevelpsignalgroupreq1Functiondevpsignalgroup4 VDDMdevelpsignalgroupreq1Functiondevpsignalgroup5 VDDMdevelpsignalgroupreq1Functiondevpsignalgroup6 VDDMdevelpsignalgroupreq1Functiondevpsignalgroup7 VDDMdevelpsignalgroupreq1Functiondevpsignalgroup8;
SIG_GROUP_ 1433 VDDMdevelpsignalgroupreq2 1 : VDDMdevelpsignalgroupreq2Functiondevpsignalgroup1 VDDMdevelpsignalgroupreq2Functiondevpsignalgroup2 VDDMdevelpsignalgroupreq2Functiondevpsignalgroup3 VDDMdevelpsignalgroupreq2Functiondevpsignalgroup4 VDDMdevelpsignalgroupreq2Functiondevpsignalgroup5 VDDMdevelpsignalgroupreq2Functiondevpsignalgroup6 VDDMdevelpsignalgroupreq2Functiondevpsignalgroup7 VDDMdevelpsignalgroupreq2Functiondevpsignalgroup8;
SIG_GROUP_ 1434 VDDMdevelpsignalgroupresp1 1 : VDDMdevelpsignalgroupresp1Functiondevpsignalgroup1 VDDMdevelpsignalgroupresp1Functiondevpsignalgroup2 VDDMdevelpsignalgroupresp1Functiondevpsignalgroup3 VDDMdevelpsignalgroupresp1Functiondevpsignalgroup4 VDDMdevelpsignalgroupresp1Functiondevpsignalgroup5 VDDMdevelpsignalgroupresp1Functiondevpsignalgroup6 VDDMdevelpsignalgroupresp1Functiondevpsignalgroup7 VDDMdevelpsignalgroupresp1Functiondevpsignalgroup8;
SIG_GROUP_ 1435 VDDMdevelpsignalgroupresp2 1 : VDDMdevelpsignalgroupresp2Functiondevpsignalgroup1 VDDMdevelpsignalgroupresp2Functiondevpsignalgroup2 VDDMdevelpsignalgroupresp2Functiondevpsignalgroup3 VDDMdevelpsignalgroupresp2Functiondevpsignalgroup4 VDDMdevelpsignalgroupresp2Functiondevpsignalgroup5 VDDMdevelpsignalgroupresp2Functiondevpsignalgroup6 VDDMdevelpsignalgroupresp2Functiondevpsignalgroup7 VDDMdevelpsignalgroupresp2Functiondevpsignalgroup8;
SIG_GROUP_ 896 VehBattU 1 : VehBattUSysU VehBattUSysUQf;
SIG_GROUP_ 592 VehCfgPrm 1 : VehCfgPrmBlkIDBytePosn1 VehCfgPrmCCPBytePosn2 VehCfgPrmCCPBytePosn3 VehCfgPrmCCPBytePosn4 VehCfgPrmCCPBytePosn5 VehCfgPrmCCPBytePosn6 VehCfgPrmCCPBytePosn7 VehCfgPrmCCPBytePosn8;
SIG_GROUP_ 1015 VehCfgPrmExt 1 : VehCfgPrmExtBlkIDBytePosn1 VehCfgPrmExtCCPBytePosn2 VehCfgPrmExtCCPBytePosn3 VehCfgPrmExtCCPBytePosn4 VehCfgPrmExtCCPBytePosn5 VehCfgPrmExtCCPBytePosn6 VehCfgPrmExtCCPBytePosn7 VehCfgPrmExtCCPBytePosn8;
SIG_GROUP_ 736 VehModMngtGlbSafe1 1 : VehModMngtGlbSafe1CarModSts1 VehModMngtGlbSafe1CarModSubtypWdCarModSubtyp VehModMngtGlbSafe1Chks VehModMngtGlbSafe1Cntr VehModMngtGlbSafe1EgyLvlElecMai VehModMngtGlbSafe1EgyLvlElecSubtyp VehModMngtGlbSafe1FltEgyCnsWdSts VehModMngtGlbSafe1PwrLvlElecMai VehModMngtGlbSafe1PwrLvlElecSubtyp VehModMngtGlbSafe1UsgModSts;
SIG_GROUP_ 1159 VehMtnSt 1 : VehMtnStChks VehMtnStCntr VehMtnStVehMtnSt;
SIG_GROUP_ 224 VehSpdLgt 1 : VehSpdLgtA VehSpdLgtChks VehSpdLgtCntr VehSpdLgtQf;
SIG_GROUP_ 545 VehSpdLgtForBkp 1 : VehSpdLgtForBkpVehSpdLgtA VehSpdLgtForBkpVehSpdLgtChks VehSpdLgtForBkpVehSpdLgtCntr VehSpdLgtForBkpVehSpdLgtQf;
SIG_GROUP_ 1383 VFCVectorRBCM 1 : VFCVectorRBCMBlockID VFCVectorRBCMVFCid0 VFCVectorRBCMVFCid1 VFCVectorRBCMVFCid10 VFCVectorRBCMVFCid11 VFCVectorRBCMVFCid12 VFCVectorRBCMVFCid13 VFCVectorRBCMVFCid14 VFCVectorRBCMVFCid15 VFCVectorRBCMVFCid16 VFCVectorRBCMVFCid17 VFCVectorRBCMVFCid18 VFCVectorRBCMVFCid19 VFCVectorRBCMVFCid2 VFCVectorRBCMVFCid20 VFCVectorRBCMVFCid21 VFCVectorRBCMVFCid22 VFCVectorRBCMVFCid23 VFCVectorRBCMVFCid24 VFCVectorRBCMVFCid25 VFCVectorRBCMVFCid26 VFCVectorRBCMVFCid27 VFCVectorRBCMVFCid28 VFCVectorRBCMVFCid29 VFCVectorRBCMVFCid3 VFCVectorRBCMVFCid30 VFCVectorRBCMVFCid31 VFCVectorRBCMVFCid32 VFCVectorRBCMVFCid33 VFCVectorRBCMVFCid34 VFCVectorRBCMVFCid35 VFCVectorRBCMVFCid36 VFCVectorRBCMVFCid37 VFCVectorRBCMVFCid38 VFCVectorRBCMVFCid39 VFCVectorRBCMVFCid4 VFCVectorRBCMVFCid40 VFCVectorRBCMVFCid41 VFCVectorRBCMVFCid42 VFCVectorRBCMVFCid43 VFCVectorRBCMVFCid44 VFCVectorRBCMVFCid45 VFCVectorRBCMVFCid46 VFCVectorRBCMVFCid47 VFCVectorRBCMVFCid48 VFCVectorRBCMVFCid49 VFCVectorRBCMVFCid5 VFCVectorRBCMVFCid50 VFCVectorRBCMVFCid51 VFCVectorRBCMVFCid52 VFCVectorRBCMVFCid53 VFCVectorRBCMVFCid54 VFCVectorRBCMVFCid55 VFCVectorRBCMVFCid56 VFCVectorRBCMVFCid57 VFCVectorRBCMVFCid58 VFCVectorRBCMVFCid59 VFCVectorRBCMVFCid6 VFCVectorRBCMVFCid60 VFCVectorRBCMVFCid61 VFCVectorRBCMVFCid7 VFCVectorRBCMVFCid8 VFCVectorRBCMVFCid9;
SIG_GROUP_ 137 WhlFastSpdSafe 1 : WhlFastSpdSafeA WhlFastSpdSafeChks WhlFastSpdSafeCntr WhlFastSpdSafeQF;
SIG_GROUP_ 1099 WhlRotToothCntr 1 : WhlRotToothCntrChks WhlRotToothCntrCntr WhlRotToothCntrFrntLe WhlRotToothCntrFrntRi WhlRotToothCntrReLe WhlRotToothCntrReRi;
SIG_GROUP_ 593 WhlRotToothCntrForBkp 1 : WhlRotToothCntrForBkpChks WhlRotToothCntrForBkpCntr WhlRotToothCntrForBkpWhlRotToothCntrFrntLe WhlRotToothCntrForBkpWhlRotToothCntrFrntRi WhlRotToothCntrForBkpWhlRotToothCntrReLe WhlRotToothCntrForBkpWhlRotToothCntrReRi;
SIG_GROUP_ 433 WhlSpdCircumlFrnt 1 : WhlSpdCircumlFrntChks WhlSpdCircumlFrntCntr WhlSpdCircumlFrntLe WhlSpdCircumlFrntLeQf WhlSpdCircumlFrntRiQf WhlSpdCircumlFrntWhlSpdCircumlFrntRi;
SIG_GROUP_ 562 WhlSpdCircumlFrntForBkp 1 : WhlSpdCircumlFrntForBkpWhlSpdCircumlFrntChks WhlSpdCircumlFrntForBkpWhlSpdCircumlFrntCntr WhlSpdCircumlFrntForBkpWhlSpdCircumlFrntLe WhlSpdCircumlFrntForBkpWhlSpdCircumlFrntLeQf WhlSpdCircumlFrntForBkpWhlSpdCircumlFrntRiQf WhlSpdCircumlFrntForBkpWhlSpdCircumlFrntWhlSpdCircumlFrntRi;
SIG_GROUP_ 439 WhlSpdCircumlRe 1 : WhlSpdCircumlReChks WhlSpdCircumlReCntr WhlSpdCircumlReLe WhlSpdCircumlReLeQf WhlSpdCircumlReRi WhlSpdCircumlReRiQf;
SIG_GROUP_ 569 WhlSpdCircumlReForBkp 1 : WhlSpdCircumlReForBkpWhlSpdCircumlReChks WhlSpdCircumlReForBkpWhlSpdCircumlReCntr WhlSpdCircumlReForBkpWhlSpdCircumlReLe WhlSpdCircumlReForBkpWhlSpdCircumlReLeQf WhlSpdCircumlReForBkpWhlSpdCircumlReRi WhlSpdCircumlReForBkpWhlSpdCircumlReRiQf;
